VERSION ""

NS_ :

BS_:

BU_: TCM HCM IPMA_ADAS PSCM ABS_ESC TCCM TCM_DSL PCM_HEV PCM ECM_HEVDSL ECM_HEV ECM_Diesel ECM SIMA_DLCS BCMD_IPDB VDM CMR_DSMC SOBDMC_HPCM CHCM GWM _delete AWD_DLCM GENERIC TSTR

BO_ 936 ParkAid_Data: 8 IPMA_ADAS
 SG_ ApaSys_D_Stat : 61|3@0+ (1,0) [0|7] "SED"  PSCM,GWM,ECM,ECM_Diesel,ECM_HEV,ECM_HEVDSL,PCM,PCM_HEV
 SG_ ApaSteWhl_D_RqDrv : 63|2@0+ (1,0) [0|3] "SED"  GWM
 SG_ ApaSteScanMde_D_Stat : 49|2@0+ (1,0) [0|3] "SED"  GWM
 SG_ ApaSelSapp_D_Stat : 51|2@0+ (1,0) [0|3] "SED"  GWM
 SG_ ApaSelPpa_D_Stat : 53|2@0+ (1,0) [0|3] "SED"  GWM
 SG_ ApaSelPoa_D_Stat : 55|2@0+ (1,0) [0|3] "SED"  GWM
 SG_ ApaScan_D_Stat : 41|2@0+ (1,0) [0|3] "SED"  GWM
 SG_ ApaLongCtl_D_RqDrv : 44|3@0+ (1,0) [0|7] "SED"  GWM
 SG_ ApaGearShif_D_RqDrv : 47|3@0+ (1,0) [0|7] "SED"  GWM
 SG_ ApaActvSide2_D_Stat : 33|2@0+ (1,0) [0|3] "SED"  GWM
 SG_ ApaAcsy_D_RqDrv : 36|3@0+ (1,0) [0|7] "SED"  GWM
 SG_ ApaTrgtDist_D_Stat : 11|4@0+ (1,0) [0|15] "SED"  GWM
 SG_ ApaMsgTxt_D_Rq : 15|4@0+ (1,0) [0|15] "SED"  GWM
 SG_ ApaChime_D_Rq : 39|3@0+ (1,0) [0|7] "SED"  GWM
 SG_ SAPPStatusCoding : 7|8@0+ (1,0) [0|255] "unitless"  GWM
 SG_ EPASExtAngleStatReq : 23|1@0+ (1,0) [0|1] "SED"  PSCM,GWM,ABS_ESC
 SG_ ExtSteeringAngleReq2 : 22|15@0+ (0.1,-1000) [-1000|2276.5] "Degrees"  GWM,PSCM
 SG_ ApaButtnPrssd_B_Stat : 58|1@0+ (1,0) [0|1] "SED"  PSCM,GWM

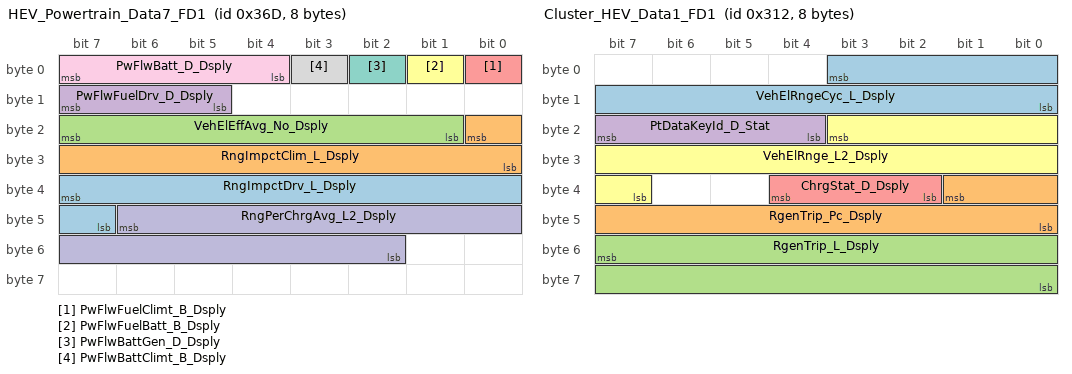
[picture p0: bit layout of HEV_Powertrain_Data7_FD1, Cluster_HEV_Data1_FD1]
BO_ 877 HEV_Powertrain_Data7_FD1: 8 SOBDMC_HPCM
 SG_ RngImpctDrv_L_Dsply : 39|9@0+ (1,-255) [-255|256] "km"  GWM
 SG_ RngImpctClim_L_Dsply : 16|9@0+ (1,-255) [-255|256] "km"  GWM
 SG_ VehElEffAvg_No_Dsply : 23|7@0+ (10,-100) [-100|1150] "wattHr/km"  GWM
 SG_ PwFlwFuelDrv_D_Dsply : 15|3@0+ (1,0) [0|7] "SED"  GWM
 SG_ PwFlwFuelClimt_B_Dsply : 0|1@0+ (1,0) [0|1] "SED"  GWM
 SG_ PwFlwFuelBatt_B_Dsply : 1|1@0+ (1,0) [0|1] "SED"  GWM
 SG_ PwFlwBattGen_D_Dsply : 2|1@0+ (1,0) [0|1] "SED"  GWM
 SG_ PwFlwBattClimt_B_Dsply : 3|1@0+ (1,0) [0|1] "SED"  GWM
 SG_ PwFlwBatt_D_Dsply : 7|4@0+ (1,0) [0|15] "SED"  GWM
 SG_ RngPerChrgAvg_L2_Dsply : 46|13@0+ (0.1,0) [0|818.9] "km"  ECM_HEV,GWM

BO_ 791 Cluster_HEV_Data8_FD1: 8 IPC
 SG_ AwdDrvMde_D2_Rq : 21|4@0+ (1,0) [0|15] "SED"  GENERIC
 SG_ StopStrtVThres_D_RqMnu : 17|2@0+ (1,0) [0|3] "SED"  ECM_HEV,ECM_HEVDSL,PCM_HEV
 SG_ EngAirFilt_B_RqReset : 48|1@0+ (1,0) [0|1] "SED"  ECM_Diesel,ECM,ECM_HEV,ECM_HEVDSL,PCM,GENERIC
 SG_ BattElEmotive_Pc_Dsply : 1|10@0+ (0.1,0) [0|102.1] "percent"  GENERIC
 SG_ HybMdeOvrrd_D_Rq : 7|2@0+ (1,0) [0|3] "SED"  PCM,SOBDMC_HPCM,PCM_HEV
 SG_ GpsElMdeSel_B_Rq : 50|1@0+ (1,0) [0|1] "SED"  SOBDMC_HPCM
 SG_ LongTermReset_B_Rq : 49|1@0+ (1,0) [0|1] "SED"  PCM_HEV,SOBDMC_HPCM
 SG_ EcoCcActv_B_Rq : 51|1@0+ (1,0) [0|1] "SED"  ECM_HEV
 SG_ DrvEffLvl_No_Stat : 61|6@0+ (1,0) [0|61] "unitless"  SOBDMC_HPCM
 SG_ ChargeProfIDPref_Rq : 5|2@0+ (1,0) [0|3] "SED"  GENERIC
 SG_ ConsAvgTrip_Fe_Dsply : 31|24@0+ (0.0001,0) [0|1677.7215] "litre/100km"  GENERIC
 SG_ GrdAsstAllw_D_RqMnu : 23|2@0+ (1,0) [0|3] "SED"  SOBDMC_HPCM,ECM_HEV
 SG_ PlgOvrrdStrt_D_Cmd : 55|2@0+ (1,0) [0|3] "SED"  SOBDMC_HPCM,PCM,PCM_HEV
 SG_ EcoMde_D_RqMnu : 3|2@0+ (1,0) [0|3] "SED"  SOBDMC_HPCM
 SG_ EmotiveType_D_Dsply : 53|2@0+ (1,0) [0|3] "SED"  GENERIC
 SG_ VehElEffTrip2Reset_B_Rq : 62|1@0+ (1,0) [0|1] "SED"  SOBDMC_HPCM
 SG_ VehElEffTrip1Reset_B_Rq : 63|1@0+ (1,0) [0|1] "SED"  SOBDMC_HPCM

BO_ 786 Cluster_HEV_Data1_FD1: 8 SOBDMC_HPCM
 SG_ VehElRngeCyc_L_Dsply : 3|12@0+ (0.1,0) [0|409.3] "km"  GWM
 SG_ RgenTrip_Pc_Dsply : 33|10@0+ (0.1,0) [0|102.3] "percent"  GWM
 SG_ RgenTrip_L_Dsply : 55|16@0+ (0.1,0) [0|6553.3] "kilometer"  GWM
 SG_ PtDataKeyId_D_Stat : 23|4@0+ (1,0) [0|15] "SED"  GWM
 SG_ ChrgStat_D_Dsply : 36|3@0+ (1,0) [0|7] "SED"  GWM
 SG_ VehElRnge_L2_Dsply : 19|13@0+ (0.1,0) [0|818.9] "kilometer"  ECM_HEV,GWM

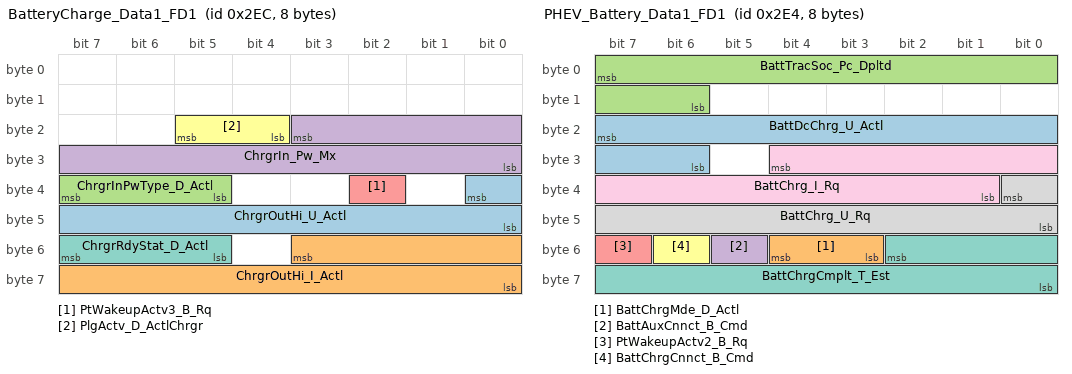
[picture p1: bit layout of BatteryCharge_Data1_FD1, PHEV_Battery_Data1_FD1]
BO_ 748 BatteryCharge_Data1_FD1: 8 SOBDM_BCCM
 SG_ ChrgrOutHi_U_Actl : 32|9@0+ (1,0) [0|510] "volt"  SOBDMC_HPCM,GENERIC
 SG_ ChrgrOutHi_I_Actl : 51|12@0+ (0.1,0) [0|409.4] "ampere"  SOBDMC_HPCM,GENERIC
 SG_ ChrgrInPwType_D_Actl : 39|3@0+ (1,0) [0|7] "SED"  SOBDMC_HPCM,PCM_HEV
 SG_ ChrgrIn_Pw_Mx : 19|12@0+ (50,0) [0|204700] "watts"  ECM_HEV,SOBDMC_HPCM,PCM_HEV
 SG_ PtWakeupActv3_B_Rq : 34|1@0+ (1,0) [0|1] "SED"  SOBDMC_HPCM,GENERIC
 SG_ PlgActv_D_ActlChrgr : 21|2@0+ (1,0) [0|3] "SED"  SOBDMC_HPCM,ECM_HEV,PCM_HEV
 SG_ ChrgrRdyStat_D_Actl : 55|3@0+ (1,0) [0|7] "SED"  SOBDMC_HPCM,ECM_HEV,PCM_HEV

BO_ 740 PHEV_Battery_Data1_FD1: 8 BECM
 SG_ BattDcChrg_U_Actl : 23|10@0+ (0.5,0) [0|510.5] "volt"  GENERIC
 SG_ BattChrgMde_D_Actl : 52|2@0+ (1,0) [0|3] "SED"  GENERIC
 SG_ BattTracSoc_Pc_Dpltd : 7|10@0+ (0.1,0) [0|102.3] "percent"  SOBDMC_HPCM,PCM_HEV
 SG_ BattAuxCnnct_B_Cmd : 53|1@0+ (1,0) [0|1] "SED"  SOBDMC_HPCM,GENERIC
 SG_ PtWakeupActv2_B_Rq : 55|1@0+ (1,0) [0|1] "SED"  SOBDMC_HPCM,GENERIC
 SG_ BattChrgCnnct_B_Cmd : 54|1@0+ (1,0) [0|1] "SED"  GENERIC
 SG_ BattChrgCmplt_T_Est : 50|11@0+ (1,0) [0|2047] "minute"  GENERIC
 SG_ BattChrg_U_Rq : 32|9@0+ (1,0) [0|511] "volt"  SOBDMC_HPCM,GENERIC
 SG_ BattChrg_I_Rq : 28|12@0+ (0.1,0) [0|409.5] "ampere"  SOBDMC_HPCM,GENERIC

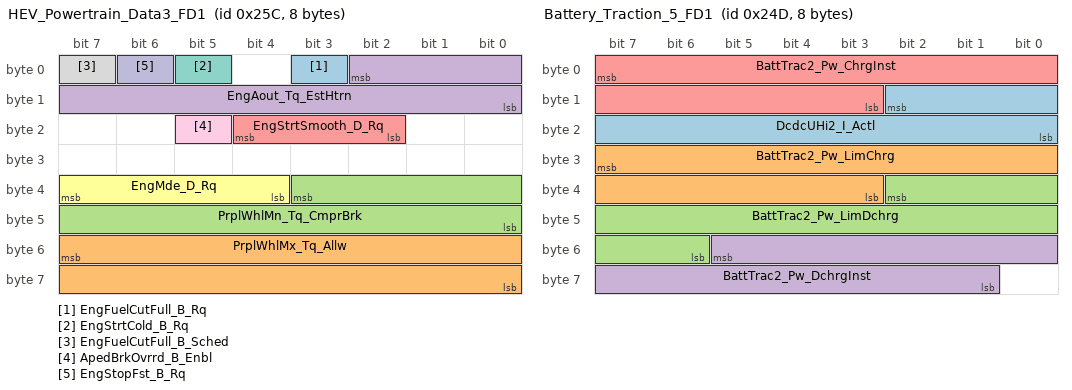
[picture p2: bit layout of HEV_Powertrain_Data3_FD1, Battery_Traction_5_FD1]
BO_ 604 HEV_Powertrain_Data3_FD1: 8 SOBDMC_HPCM
 SG_ EngFuelCutFull_B_Rq : 3|1@0+ (1,0) [0|1] "SED"  GWM,ECM_HEV
 SG_ PrplWhlMx_Tq_Allw : 55|16@0+ (4,-131072) [-131072|131064] "Nm"  GWM,ECM_HEV
 SG_ PrplWhlMn_Tq_CmprBrk : 35|12@0+ (4,-8192) [-8192|8184] "Nm"  GWM,ECM_HEV
 SG_ EngAout_Tq_EstHtrn : 2|11@0+ (1,-500) [-500|1546] "Nm"  GWM,ECM_HEV
 SG_ EngStrtSmooth_D_Rq : 20|3@0+ (1,0) [0|7] "SED"  GWM,ECM_HEV
 SG_ EngMde_D_Rq : 39|4@0+ (1,0) [0|15] "SED"  GWM,ECM_HEV
 SG_ EngStrtCold_B_Rq : 5|1@0+ (1,0) [0|1] "SED"  GWM,ECM_HEV
 SG_ EngFuelCutFull_B_Sched : 7|1@0+ (1,0) [0|1] "SED"  GWM,ECM_HEV
 SG_ ApedBrkOvrrd_B_Enbl : 21|1@0+ (1,0) [0|1] "SED"  GWM,ECM_HEV
 SG_ EngStopFst_B_Rq : 6|1@0+ (1,0) [0|1] "SED"  GWM,ECM_HEV

BO_ 589 Battery_Traction_5_FD1: 8 BECM
 SG_ DcdcUHi2_I_Actl : 10|11@0+ (0.1,0) [0|204.6] "ampere"  SOBDMC_HPCM,ECM_HEVDSL,PCM_HEV
 SG_ BattTrac2_Pw_LimChrg : 31|13@0+ (50,0) [0|409550] "watts"  SOBDMC_HPCM,ECM_HEVDSL,PCM_HEV
 SG_ BattTrac2_Pw_LimDchrg : 34|13@0+ (50,0) [0|409550] "watts"  SOBDMC_HPCM,ECM_HEVDSL,PCM_HEV
 SG_ BattTrac2_Pw_DchrgInst : 53|13@0+ (50,0) [0|409550] "watts"  SOBDMC_HPCM,ECM_HEVDSL,PCM_HEV
 SG_ BattTrac2_Pw_ChrgInst : 7|13@0+ (50,0) [0|409550] "watts"  SOBDMC_HPCM,ECM_HEVDSL,PCM_HEV

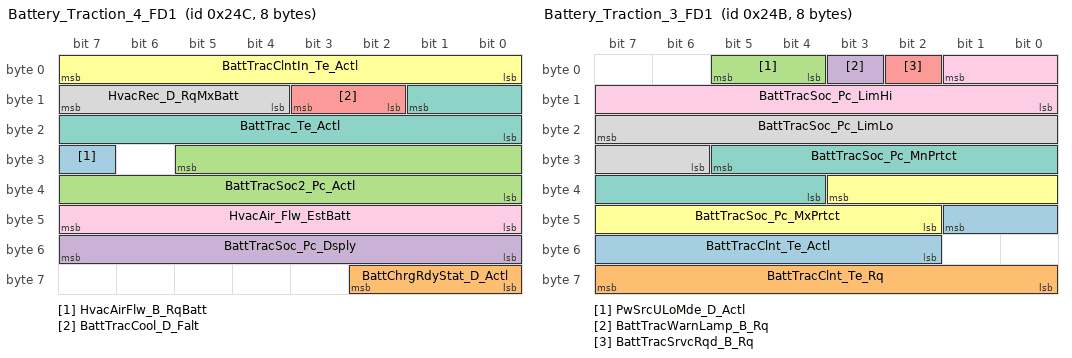
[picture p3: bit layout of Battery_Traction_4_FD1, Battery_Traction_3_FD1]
BO_ 588 Battery_Traction_4_FD1: 8 BECM
 SG_ HvacAirFlw_B_RqBatt : 31|1@0+ (1,0) [0|1] "SED"  SOBDMC_HPCM,ECM_HEVDSL
 SG_ BattChrgRdyStat_D_Actl : 58|3@0+ (1,0) [0|7] "SED"  SOBDMC_HPCM,ECM_HEV,ECM_HEVDSL,PCM_HEV
 SG_ BattTracSoc2_Pc_Actl : 29|14@0+ (0.01,0) [0|163.81] "%"  SOBDMC_HPCM,ECM_HEV,ECM_HEVDSL,PCM_HEV
 SG_ BattTracSoc_Pc_Dsply : 55|8@0+ (0.5,0) [0|126.5] "Percent"  SOBDMC_HPCM,PCM_HEV
 SG_ BattTracCool_D_Falt : 11|2@0+ (1,0) [0|3] "SED"  GENERIC
 SG_ BattTracClntIn_Te_Actl : 7|8@0+ (1,-50) [-50|204] "degC"  GENERIC
 SG_ BattTrac_Te_Actl : 9|10@0+ (0.5,-50) [-50|460.5] "degC"  SOBDMC_HPCM,ECM_HEV,ECM_HEVDSL,PCM_HEV
 SG_ HvacRec_D_RqMxBatt : 15|4@0+ (1,0) [0|15] "SED"  GENERIC
 SG_ HvacAir_Flw_EstBatt : 47|8@0+ (0.5,0) [0|127] "liter/second"  ECM_HEVDSL

BO_ 587 Battery_Traction_3_FD1: 8 BECM
 SG_ BattTracClnt_Te_Actl : 41|8@0+ (0.5,-60) [-60|66.5] "degC"  ECM_Diesel,ECM_HEVDSL,SOBDMC_HPCM
 SG_ BattTracClnt_Te_Rq : 63|8@0+ (0.5,-60) [-60|67.5] "degC"  SOBDMC_HPCM,GENERIC
 SG_ PwSrcULoMde_D_Actl : 5|2@0+ (1,0) [0|3] "SED"  ECM_HEV,ECM_HEVDSL,PCM_HEV
 SG_ BattTracWarnLamp_B_Rq : 3|1@0+ (1,0) [0|1] "SED"  GENERIC
 SG_ BattTracSrvcRqd_B_Rq : 2|1@0+ (1,0) [0|1] "SED"  GENERIC
 SG_ BattTracSoc_Pc_MxPrtct : 35|10@0+ (0.1,0) [0|100] "%"  SOBDMC_HPCM,ECM_HEVDSL,PCM_HEV,ECM_HEV
 SG_ BattTracSoc_Pc_MnPrtct : 29|10@0+ (0.1,0) [0|100] "%"  SOBDMC_HPCM,ECM_HEV,ECM_HEVDSL,PCM_HEV
 SG_ BattTracSoc_Pc_LimLo : 23|10@0+ (0.1,0) [0|100] "%"  SOBDMC_HPCM,ECM_HEV,ECM_HEVDSL,PCM_HEV
 SG_ BattTracSoc_Pc_LimHi : 1|10@0+ (0.1,0) [0|100] "%"  SOBDMC_HPCM,ECM_HEV,ECM_HEVDSL,PCM_HEV

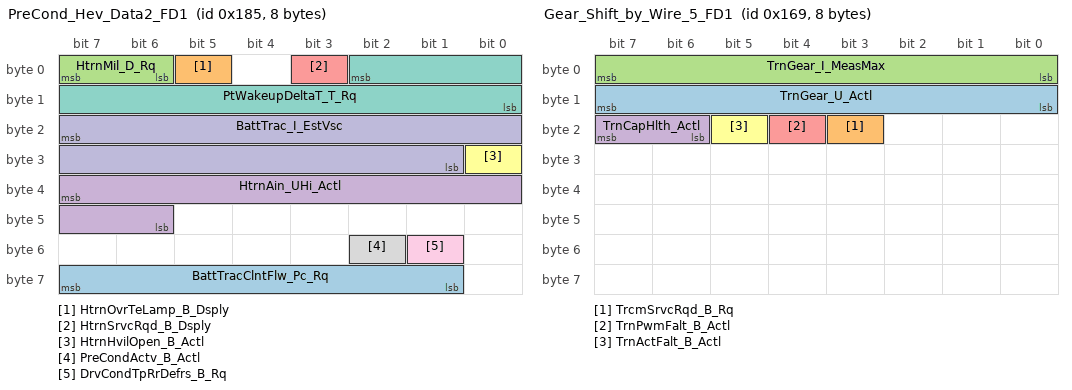
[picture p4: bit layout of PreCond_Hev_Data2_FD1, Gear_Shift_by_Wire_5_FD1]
BO_ 389 PreCond_Hev_Data2_FD1: 8 SOBDMC_HPCM
 SG_ BattTracClntFlw_Pc_Rq : 63|7@0+ (1,0) [0|127] "percent"  GWM,GENERIC
 SG_ HtrnOvrTeLamp_B_Dsply : 5|1@0+ (1,0) [0|1] "SED"  GWM,GENERIC
 SG_ HtrnMil_D_Rq : 7|2@0+ (1,0) [0|3] "SED"  GWM,ECM_HEV
 SG_ HtrnAin_UHi_Actl : 39|10@0+ (0.5,0) [0|510.5] "volt"  GWM,PCM_HEV,ECM_HEV
 SG_ HtrnSrvcRqd_B_Dsply : 3|1@0+ (1,0) [0|1] "SED"  GWM
 SG_ HtrnHvilOpen_B_Actl : 24|1@0+ (1,0) [0|1] "SED"  GWM,PCM_HEV
 SG_ PtWakeupDeltaT_T_Rq : 2|11@0+ (1,0) [0|2045] "minute"  GWM,GENERIC
 SG_ PreCondActv_B_Actl : 50|1@0+ (1,0) [0|1] "SED"  GWM,ECM_HEV,PCM_HEV
 SG_ DrvCondTpRrDefrs_B_Rq : 49|1@0+ (1,0) [0|1] "SED"  GWM,GENERIC
 SG_ BattTrac_I_EstVsc : 23|15@0+ (0.05,-750) [-750|888.25] "Amps"  GWM

BO_ 361 Gear_Shift_by_Wire_5_FD1: 8 TRCM
 SG_ TrnGear_U_Actl : 15|8@0+ (0.1,0) [0|25.5] "volt"  PCM,PCM_HEV
 SG_ TrcmSrvcRqd_B_Rq : 19|1@0+ (1,0) [0|1] "SED"  GENERIC
 SG_ TrnGear_I_MeasMax : 7|8@0+ (0.1,0) [0|25.4] "Amps"  ECM_HEV,PCM,PCM_HEV
 SG_ TrnCapHlth_Actl : 23|2@0+ (1,0) [0|3] "SED"  ECM_HEV,PCM,PCM_HEV
 SG_ TrnPwmFalt_B_Actl : 20|1@0+ (1,0) [0|1] "SED"  ECM_HEV,PCM,PCM_HEV
 SG_ TrnActFalt_B_Actl : 21|1@0+ (1,0) [0|1] "SED"  PCM_HEV,PCM,ECM_HEV

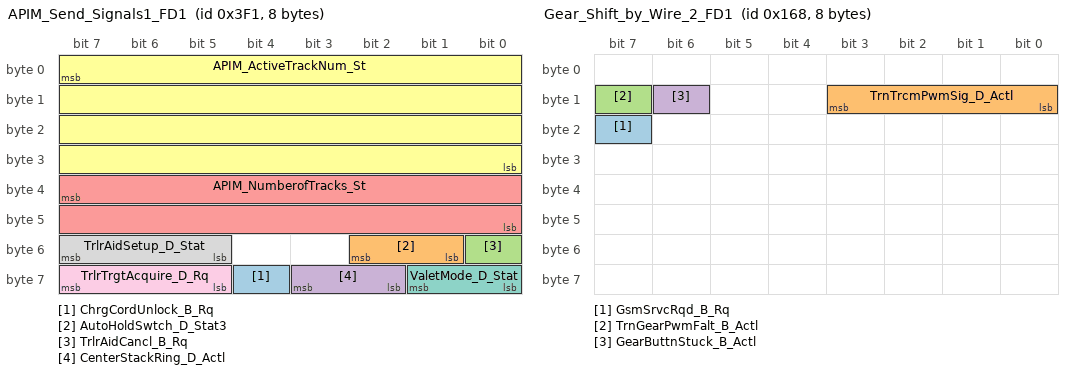
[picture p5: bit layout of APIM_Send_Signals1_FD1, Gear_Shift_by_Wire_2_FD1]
BO_ 1009 APIM_Send_Signals1_FD1: 8 APIM
 SG_ ChrgCordUnlock_B_Rq : 60|1@0+ (1,0) [0|1] "SED"  GENERIC
 SG_ AutoHoldSwtch_D_Stat3 : 50|2@0+ (1,0) [0|3] "SED"  ABS_ESC
 SG_ TrlrAidCancl_B_Rq : 48|1@0+ (1,0) [0|1] "SED"  IPMA_ADAS,PSCM
 SG_ CenterStackRing_D_Actl : 59|2@0+ (1,0) [0|3] "SED"  GENERIC
 SG_ APIM_NumberofTracks_St : 39|16@0+ (1,0) [0|65535] "unitless"  GENERIC
 SG_ APIM_ActiveTrackNum_St : 7|32@0+ (1,0) [0|4294967295] "unitless"  GENERIC
 SG_ ValetMode_D_Stat : 57|2@0+ (1,0) [0|3] "SED"  GENERIC
 SG_ TrlrAidSetup_D_Stat : 55|3@0+ (1,0) [0|7] "SED"  GENERIC
 SG_ TrlrTrgtAcquire_D_Rq : 63|3@0+ (1,0) [0|7] "SED"  GENERIC

BO_ 360 Gear_Shift_by_Wire_2_FD1: 8 GSM
 SG_ GsmSrvcRqd_B_Rq : 23|1@0+ (1,0) [0|1] "SED"  TCM,SOBDMC_HPCM,TCM_DSL
 SG_ TrnTrcmPwmSig_D_Actl : 11|4@0+ (1,0) [0|15] "SED"  TCM,SOBDMC_HPCM,ECM_HEV,PCM,PCM_HEV,TCM_DSL
 SG_ TrnGearPwmFalt_B_Actl : 15|1@0+ (1,0) [0|1] "SED"  TCM,SOBDMC_HPCM,ECM_HEV,PCM,PCM_HEV,TCM_DSL
 SG_ GearButtnStuck_B_Actl : 14|1@0+ (1,0) [0|1] "SED"  TCM,SOBDMC_HPCM,ECM_HEV,PCM,PCM_HEV,TCM_DSL

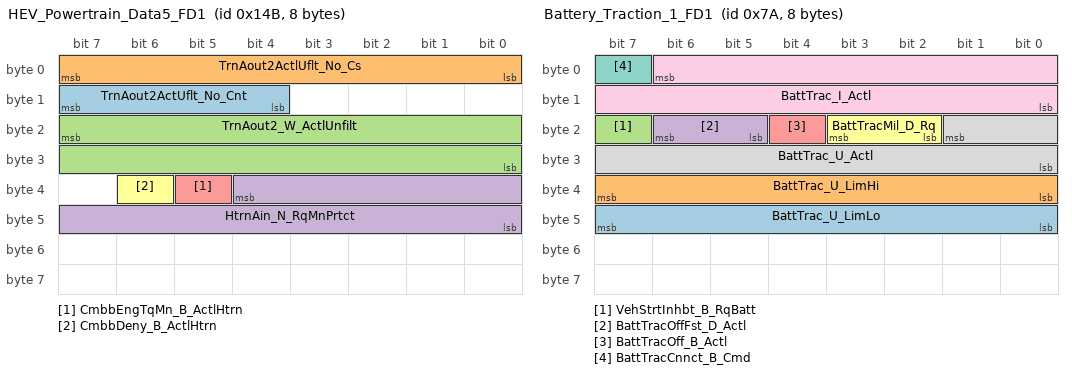
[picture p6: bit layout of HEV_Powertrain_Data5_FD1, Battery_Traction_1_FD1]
BO_ 331 HEV_Powertrain_Data5_FD1: 8 SOBDMC_HPCM
 SG_ TrnAout2ActUflt_No_Cnt : 15|4@0+ (1,0) [0|15] "Unitless"  GWM,ECM_HEV
 SG_ TrnAout2ActlUflt_No_Cs : 7|8@0+ (1,0) [0|255] "Unitless"  GWM,ECM_HEV
 SG_ TrnAout2_W_ActlUnfilt : 23|16@0+ (0.1,-3276.5) [-3276.5|3276.8] "rad/s"  GWM,ABS_ESC,ECM_HEV
 SG_ HtrnAin_N_RqMnPrtct : 36|13@0+ (2,0) [0|16382] "RPM"  GWM,ECM_HEV
 SG_ CmbbEngTqMn_B_ActlHtrn : 37|1@0+ (1,0) [0|1] "SED"  GWM,ECM_HEV
 SG_ CmbbDeny_B_ActlHtrn : 38|1@0+ (1,0) [0|1] "SED"  GWM,ECM_HEV

BO_ 140 CruiseCtrl_StrgData2_FD1: 8 IPC
 SG_ DcacPwResetBttn_D_Stat : 36|2@0+ (1,0) [0|3] "SED"  ECM,ECM_Diesel,ECM_HEV,ECM_HEVDSL,PCM,PCM_HEV
 SG_ CcAslButtnIndxIncPress2 : 18|1@0+ (1,0) [0|1] "SED"  ECM,ECM_HEVDSL,PCM
 SG_ SteWhlSwtchMde_D_Stat : 23|2@0+ (1,0) [0|3] "SED"  GENERIC
 SG_ CcAslButtnIndxDecPress2 : 19|1@0+ (1,0) [0|1] "SED"  ECM,ECM_HEVDSL,PCM
 SG_ CcAslButtnResIncPress3 : 29|1@0+ (1,0) [0|1] "SED"  PCM,ECM_HEVDSL,ECM
 SG_ CcButtnOnPress3 : 37|1@0+ (1,0) [0|1] "SED"  PCM,ECM_HEVDSL,ECM
 SG_ CcButtnOnOffPress3 : 38|1@0+ (1,0) [0|1] "SED"  PCM,ECM_HEVDSL,ECM
 SG_ CcButtnOnOffCnclPress3 : 39|1@0+ (1,0) [0|1] "SED"  PCM,ECM_HEVDSL,ECM
 SG_ CcButtnOffPress3 : 24|1@0+ (1,0) [0|1] "SED"  PCM,ECM_HEVDSL,ECM
 SG_ CcAsllButtnResPress3 : 25|1@0+ (1,0) [0|1] "SED"  PCM,ECM_HEVDSL,ECM
 SG_ CcAslButtnSetPress3 : 26|1@0+ (1,0) [0|1] "SED"  PCM,ECM_HEVDSL,ECM
 SG_ CcAslButtnSetIncPress3 : 27|1@0+ (1,0) [0|1] "SED"  PCM,ECM_HEVDSL,ECM
 SG_ CcAslButtnSetDecPress3 : 28|1@0+ (1,0) [0|1] "SED"  PCM,ECM_HEVDSL,ECM
 SG_ CcAslButtnResDecPress3 : 30|1@0+ (1,0) [0|1] "SED"  PCM,ECM_HEVDSL,ECM
 SG_ CcAslButtnOnPress3 : 31|1@0+ (1,0) [0|1] "SED"  PCM,ECM_HEVDSL,ECM
 SG_ CcAslButtnOnOffCncl3 : 16|1@0+ (1,0) [0|1] "SED"  PCM,ECM_HEVDSL,ECM
 SG_ CcAslButtnDeny_B_Actl3 : 20|1@0+ (1,0) [0|1] "SED"  PCM,ECM_HEVDSL,ECM
 SG_ CcAslButtnCnclPress3 : 8|1@0+ (1,0) [0|1] "SED"  PCM,ECM_HEVDSL,ECM
 SG_ AslButtnOnOffPress3 : 9|1@0+ (1,0) [0|1] "SED"  PCM,ECM_HEVDSL,ECM
 SG_ AslButtnOnOffCnclPress2 : 10|1@0+ (1,0) [0|1] "SED"  PCM,ECM_HEVDSL,ECM
 SG_ CcAslButtnOffCnclPress2 : 17|1@0+ (1,0) [0|1] "SED"  ECM_HEVDSL,PCM,ECM
 SG_ CcAslButtnCnclResPress2 : 21|1@0+ (1,0) [0|1] "SED"  ECM,ECM_HEVDSL,PCM

BO_ 122 Battery_Traction_1_FD1: 8 BECM
 SG_ BattTrac_U_LimLo : 47|8@0+ (2,0) [0|510] "volt"  SOBDMC_HPCM,PCM_HEV
 SG_ BattTrac_U_LimHi : 39|8@0+ (2,0) [0|510] "volt"  SOBDMC_HPCM,PCM_HEV
 SG_ VehStrtInhbt_B_RqBatt : 23|1@0+ (1,0) [0|1] "SED"  SOBDMC_HPCM,PCM_HEV,ECM_HEVDSL
 SG_ BattTracOffFst_D_Actl : 22|2@0+ (1,0) [0|3] "SED"  SOBDMC_HPCM,ECM_HEV,ECM_HEVDSL,PCM_HEV
 SG_ BattTracOff_B_Actl : 20|1@0+ (1,0) [0|1] "SED"  ECM_HEVDSL,SOBDMC_HPCM,PCM_HEV
 SG_ BattTracMil_D_Rq : 19|2@0+ (1,0) [0|3] "SED"  PCM_HEV,ECM_HEV
 SG_ BattTracCnnct_B_Cmd : 7|1@0+ (1,0) [0|1] "SED"  SOBDMC_HPCM,ECM_HEV,ECM_HEVDSL,PCM_HEV
 SG_ BattTrac_U_Actl : 17|10@0+ (0.5,0) [0|510.5] "Volts"  SOBDMC_HPCM,ECM_HEV,ECM_HEVDSL,PCM_HEV
 SG_ BattTrac_I_Actl : 6|15@0+ (0.05,-750) [-750|888.25] "Amps"  SOBDMC_HPCM,ECM_HEV,ECM_HEVDSL,PCM_HEV

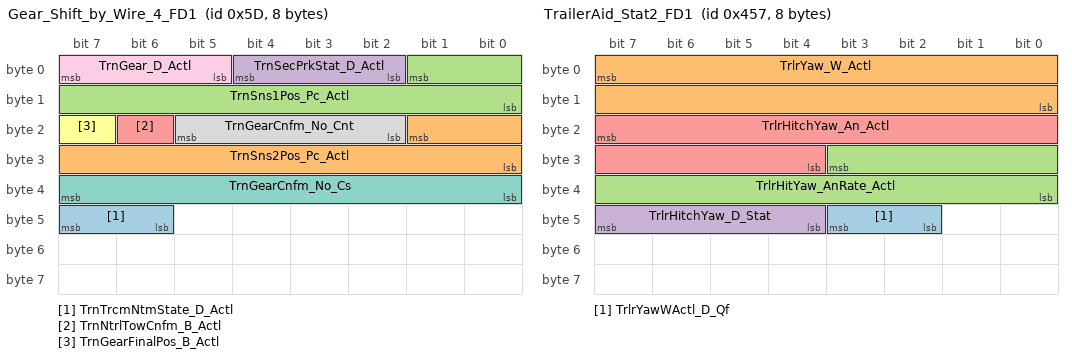
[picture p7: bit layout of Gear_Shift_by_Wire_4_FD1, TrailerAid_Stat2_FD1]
BO_ 93 Gear_Shift_by_Wire_4_FD1: 8 TRCM
 SG_ TrnTrcmNtmState_D_Actl : 47|2@0+ (1,0) [0|3] "SED"  TCM,ECM_HEV,PCM,PCM_HEV,TCM_DSL
 SG_ TrnSns2Pos_Pc_Actl : 17|10@0+ (0.1,0) [0|102.2] "percent duty cycle"  ECM_HEV,PCM,PCM_HEV
 SG_ TrnSns1Pos_Pc_Actl : 1|10@0+ (0.1,0) [0|102.2] "percent duty cycle"  ECM_HEV,PCM,PCM_HEV
 SG_ TrnSecPrkStat_D_Actl : 4|3@0+ (1,0) [0|7] "SED"  ECM_HEV,PCM,PCM_HEV
 SG_ TrnNtrlTowCnfm_B_Actl : 22|1@0+ (1,0) [0|1] "SED"  ECM_HEV,PCM,PCM_HEV
 SG_ TrnGearFinalPos_B_Actl : 23|1@0+ (1,0) [0|1] "SED"  ECM_HEV,PCM,PCM_HEV
 SG_ TrnGearCnfm_No_Cs : 39|8@0+ (1,0) [0|255] "Unitless"  ECM_HEV,PCM,PCM_HEV
 SG_ TrnGearCnfm_No_Cnt : 21|4@0+ (1,0) [0|15] "Unitless"  ECM_HEV,PCM,PCM_HEV
 SG_ TrnGear_D_Actl : 7|3@0+ (1,0) [0|7] "SED"  ECM_HEV,PCM,PCM_HEV

BO_ 90 Gear_Shift_by_Wire_FD1: 8 GSM
 SG_ TrnGsmNtmState_D_Actl : 55|2@0+ (1,0) [0|3] "SED"  TCM,SOBDMC_HPCM,ABS_ESC,ECM_HEV,PCM,PCM_HEV,TCM_DSL
 SG_ DrQltyDrv_D_StatGsm : 42|3@0+ (1,0) [0|7] "SED"  TCM,SOBDMC_HPCM,ABS_ESC,ECM,ECM_HEV,ECM_HEVDSL,PCM,PCM_HEV,TCM_DSL,IPMA_ADAS
 SG_ TrnBtsiOvrrd_B_Stat : 43|1@0+ (1,0) [0|1] "SED"  ABS_ESC,TCM,SOBDMC_HPCM,ECM,ECM_HEV,ECM_HEVDSL,PCM,PCM_HEV,TCM_DSL
 SG_ GsmGearMsgTxt_D_Rq : 63|2@0+ (1,0) [0|3] "SED"  SOBDMC_HPCM,GENERIC
 SG_ TrnRng_D_RqGsm : 51|4@0+ (1,0) [0|15] "SED"  TCM,SOBDMC_HPCM,ECM,ECM_HEV,ECM_HEVDSL,PCM,TCM_DSL,PCM_HEV
 SG_ PrkBrkActv_D_RqGsmGear : 53|2@0+ (1,0) [0|3] "SED"  SOBDMC_HPCM,ABS_ESC
 SG_ TrnValidGearRq_D_Stat : 25|2@0+ (1,0) [0|3] "SED"  ABS_ESC,TCM,SOBDMC_HPCM,ECM_HEV,PCM,PCM_HEV,TCM_DSL
 SG_ TrnGearRqCnt_B_Actl : 26|1@0+ (1,0) [0|1] "unitless"  ABS_ESC,TCM,SOBDMC_HPCM,ECM_HEV,PCM,PCM_HEV,TCM_DSL
 SG_ TrnGearButtn_U_Actl : 23|8@0+ (0.05,0) [0|12.7] "VOLT"  TCM,SOBDMC_HPCM,ECM_HEV,PCM,PCM_HEV,TCM_DSL
 SG_ TrnGearButtn_B_ActlR2 : 8|1@0+ (1,0) [0|1] "SED"  TCM,SOBDMC_HPCM,ECM_HEV,PCM,PCM_HEV,TCM_DSL
 SG_ TrnGearButtn_B_ActlR1 : 9|1@0+ (1,0) [0|1] "SED"  TCM,SOBDMC_HPCM,ECM_HEV,PCM,PCM_HEV,TCM_DSL
 SG_ TrnGearButtn_B_ActlR0 : 10|1@0+ (1,0) [0|1] "SED"  TCM,SOBDMC_HPCM,ECM_HEV,PCM,PCM_HEV,TCM_DSL
 SG_ TrnGearButtn_B_ActlP2 : 11|1@0+ (1,0) [0|1] "SED"  TCM,SOBDMC_HPCM,TCM_DSL,ECM_HEV,PCM,PCM_HEV
 SG_ TrnGearButtn_B_ActlP1 : 12|1@0+ (1,0) [0|1] "SED"  TCM,SOBDMC_HPCM,ECM_HEV,PCM,PCM_HEV,TCM_DSL
 SG_ TrnGearButtn_B_ActlP0 : 13|1@0+ (1,0) [0|1] "SED"  TCM,SOBDMC_HPCM,ECM_HEV,PCM,PCM_HEV,TCM_DSL
 SG_ TrnGearButtn_B_ActlN2 : 14|1@0+ (1,0) [0|1] "SED"  TCM,SOBDMC_HPCM,ECM_HEV,PCM,PCM_HEV,TCM_DSL
 SG_ TrnGearButtn_B_ActlN1 : 15|1@0+ (1,0) [0|1] "SED"  TCM,SOBDMC_HPCM,ECM_HEV,PCM,PCM_HEV,TCM_DSL
 SG_ TrnGearButtn_B_ActlN0 : 0|1@0+ (1,0) [0|1] "SED"  TCM,SOBDMC_HPCM,ECM_HEV,PCM,PCM_HEV,TCM_DSL
 SG_ TrnGearButtn_B_ActlM2 : 1|1@0+ (1,0) [0|1] "SED"  TCM,SOBDMC_HPCM,ECM_HEV,PCM,PCM_HEV,TCM_DSL
 SG_ TrnGearButtn_B_ActlM1 : 2|1@0+ (1,0) [0|1] "SED"  TCM,SOBDMC_HPCM,ECM_HEV,PCM,PCM_HEV,TCM_DSL
 SG_ TrnGearButtn_B_ActlM0 : 3|1@0+ (1,0) [0|1] "SED"  TCM,SOBDMC_HPCM,ECM_HEV,PCM,PCM_HEV,TCM_DSL
 SG_ TrnGearButtn_B_ActlD2 : 4|1@0+ (1,0) [0|1] "SED"  TCM,SOBDMC_HPCM,ECM_HEV,PCM,PCM_HEV,TCM_DSL
 SG_ TrnGearButtn_B_ActlD1 : 5|1@0+ (1,0) [0|1] "SED"  TCM,SOBDMC_HPCM,ECM_HEV,PCM,PCM_HEV,TCM_DSL
 SG_ TrnGearButtn_B_ActlD0 : 6|1@0+ (1,0) [0|1] "SED"  TCM,SOBDMC_HPCM,ECM_HEV,PCM,PCM_HEV,TCM_DSL
 SG_ TrnGear_No_Cs : 39|8@0+ (1,0) [0|255] "Unitless"  ABS_ESC,TCM,SOBDMC_HPCM,ECM_HEV,PCM,PCM_HEV,TCM_DSL
 SG_ TrnGear_No_Cnt : 47|4@0+ (1,0) [0|15] "Unitless"  ABS_ESC,TCM,SOBDMC_HPCM,ECM_HEV,PCM,PCM_HEV,TCM_DSL
 SG_ TrnGear_D_RqDrv : 31|5@0+ (1,0) [0|31] "SED"  ABS_ESC,TCM,SOBDMC_HPCM,ECM_HEV,PCM,PCM_HEV,TCM_DSL
 SG_ BrkSwtchPos_B_ActlGsm : 7|1@0+ (1,0) [0|1] "SED"  ABS_ESC,TCM,SOBDMC_HPCM,ECM_HEV,PCM,PCM_HEV,TCM_DSL

BO_ 1114 TrailerAid_Data_FD1: 8 IPC
 SG_ TrailCtlSwtch_B_Stat2 : 16|1@0+ (1,0) [0|1] "SED"  ABS_ESC
 SG_ TrlBrkInitOut_D_Rq : 60|2@0+ (1,0) [0|3] "SED"  GENERIC

BO_ 1111 TrailerAid_Stat2_FD1: 8 RCM
 SG_ TrlrYawWActl_D_Qf : 43|2@0+ (1,0) [0|3] "SED"  IPMA_ADAS,PSCM
 SG_ TrlrYaw_W_Actl : 7|16@0+ (0.0002,-6.5) [-6.5|6.6066] "radians/second"  IPMA_ADAS,PSCM
 SG_ TrlrHitYaw_AnRate_Actl : 27|12@0+ (0.1,-50) [-50|359.3] "degrees/second"  IPMA_ADAS,PSCM
 SG_ TrlrHitchYaw_D_Stat : 47|4@0+ (1,0) [0|15] "SED"  IPMA_ADAS,PSCM
 SG_ TrlrHitchYaw_An_Actl : 23|12@0+ (0.1,-90) [-90|319.3] "degrees"  IPMA_ADAS,PSCM

BO_ 1106 TrailerAid_Stat1_FD1: 8 RCM
 SG_ TrlrSnsId_No_Actl : 7|48@0+ (1,0) [0|281474976710653] "unitless"  PSCM,IPMA_ADAS

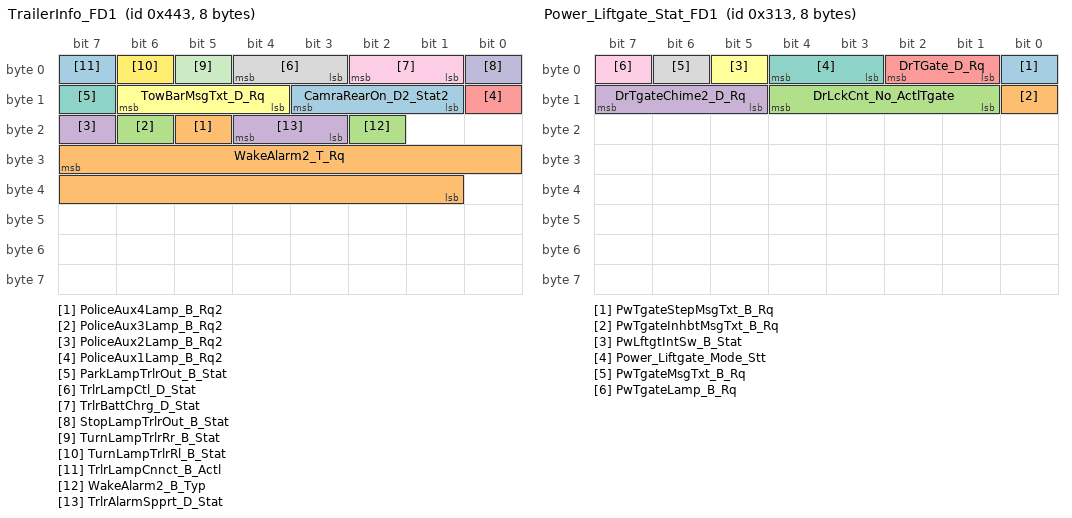
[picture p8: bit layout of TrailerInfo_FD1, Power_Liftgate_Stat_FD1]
BO_ 1091 TrailerInfo_FD1: 8 TRM
 SG_ CamraRearOn_D2_Stat2 : 11|3@0+ (1,0) [0|7] "SED"  IPMA_ADAS
 SG_ PoliceAux4Lamp_B_Rq2 : 21|1@0+ (1,0) [0|1] "SED"  GENERIC
 SG_ PoliceAux3Lamp_B_Rq2 : 22|1@0+ (1,0) [0|1] "SED"  GENERIC
 SG_ PoliceAux2Lamp_B_Rq2 : 23|1@0+ (1,0) [0|1] "SED"  GENERIC
 SG_ PoliceAux1Lamp_B_Rq2 : 8|1@0+ (1,0) [0|1] "SED"  GENERIC
 SG_ TowBarMsgTxt_D_Rq : 14|3@0+ (1,0) [0|7] "SED"  GENERIC
 SG_ ParkLampTrlrOut_B_Stat : 15|1@0+ (1,0) [0|1] "SED"  GENERIC
 SG_ TrlrLampCtl_D_Stat : 4|2@0+ (1,0) [0|3] "SED"  GENERIC
 SG_ TrlrBattChrg_D_Stat : 2|2@0+ (1,0) [0|3] "SED"  GENERIC
 SG_ StopLampTrlrOut_B_Stat : 0|1@0+ (1,0) [0|1] "SED"  GENERIC
 SG_ TurnLampTrlrRr_B_Stat : 5|1@0+ (1,0) [0|1] "SED"  GENERIC
 SG_ TurnLampTrlrRl_B_Stat : 6|1@0+ (1,0) [0|1] "SED"  GENERIC
 SG_ TrlrLampCnnct_B_Actl : 7|1@0+ (1,0) [0|1] "SED"  TCM,VDM,ECM,ECM_Diesel,ECM_HEV,ECM_HEVDSL,PCM,PCM_HEV,TCM_DSL,ABS_ESC,IPMA_ADAS,PSCM,AWD_DLCM
 SG_ WakeAlarm2_T_Rq : 31|15@0+ (1,0) [0|32767] "minute"  GENERIC
 SG_ WakeAlarm2_B_Typ : 18|1@0+ (1,0) [0|1] "SED"  GENERIC
 SG_ TrlrAlarmSpprt_D_Stat : 20|2@0+ (1,0) [0|3] "SED"  GENERIC

BO_ 138 ActiveFrontStrg_Stat2_FD1: 8 GWM
 SG_ SteWhlRelCalib_T_Actl : 7|8@0+ (1,0) [0|255] "ms"  ABS_ESC
 SG_ SteWhlRelCalib_An_Sns : 15|15@0+ (0.1,-1600) [-1600|1676.5] "deg"  CMR_DSMC,ABS_ESC,PSCM,TCCM

BO_ 131 Steering_Data_FD1: 8 SCCM
 SG_ TurnLghtSwtch_D_Arb : 55|4@0+ (1,0) [0|15] "SED"  IPMA_ADAS
 SG_ HeadLghtHiCtrl_D_RqAhb : 43|3@0+ (1,0) [0|7] "SED"  HCM,GENERIC
 SG_ AhbStat_B_Dsply : 33|1@0+ (1,0) [0|1] "SED"  GENERIC
 SG_ WiprFrontSwtch_D_Stat : 47|4@0+ (1,0) [0|15] "SED"  GENERIC
 SG_ HeadLghtHiOn_B_StatAhb : 34|1@0+ (1,0) [0|1] "SED"  IPMA_ADAS
 SG_ HeadLghtHiFlash_D_Actl : 36|2@0+ (1,0) [0|3] "SED"  HCM,IPMA_ADAS
 SG_ TjaButtnOnOffPress : 40|1@0+ (1,0) [0|1] "SED"  ECM,ECM_Diesel,ECM_HEVDSL,IPMA_ADAS,PCM,PCM_HEV
 SG_ AccButtnGapTogglePress : 32|1@0+ (1,0) [0|1] "SED"  IPMA_ADAS
 SG_ WiprFront_D_Stat : 3|4@0+ (1,0) [0|15] "SED"  SOBDMC_HPCM,HCM,ABS_ESC,ECM,ECM_Diesel,ECM_HEV,ECM_HEVDSL,IPMA_ADAS,PCM,PCM_HEV,AWD_DLCM
 SG_ TurnLghtSwtch_D_Stat : 5|2@0+ (1,0) [0|3] "SED"  HCM,IPMA_ADAS,PSCM
 SG_ LghtAmb_D_Sns : 15|3@0+ (1,0) [0|7] "SED"  HCM,IPMA_ADAS
 SG_ AccButtnGapIncPress : 11|1@0+ (1,0) [0|1] "SED"  IPMA_ADAS
 SG_ AccButtnGapDecPress : 12|1@0+ (1,0) [0|1] "SED"  IPMA_ADAS
 SG_ AslButtnOnOffPress : 9|1@0+ (1,0) [0|1] "SED"  ECM,ECM_Diesel,ECM_HEV,ECM_HEVDSL,PCM,PCM_HEV,IPMA_ADAS
 SG_ AslButtnOnOffCnclPress : 10|1@0+ (1,0) [0|1] "SED"  ECM,ECM_Diesel,ECM_HEV,ECM_HEVDSL,PCM,PCM_HEV,IPMA_ADAS
 SG_ CcButtnOnPress : 37|1@0+ (1,0) [0|1] "SED"  ECM,ECM_Diesel,ECM_HEV,ECM_HEVDSL,IPMA_ADAS,PCM,PCM_HEV
 SG_ CcButtnOnOffPress : 38|1@0+ (1,0) [0|1] "SED"  ECM,ECM_Diesel,ECM_HEV,ECM_HEVDSL,IPMA_ADAS,PCM,PCM_HEV
 SG_ CcButtnOnOffCnclPress : 39|1@0+ (1,0) [0|1] "SED"  ECM,ECM_Diesel,ECM_HEV,ECM_HEVDSL,IPMA_ADAS,PCM,PCM_HEV
 SG_ CcButtnOffPress : 24|1@0+ (1,0) [0|1] "SED"  ECM,ECM_Diesel,ECM_HEV,ECM_HEVDSL,IPMA_ADAS,PCM,PCM_HEV
 SG_ CcAsllButtnResPress : 25|1@0+ (1,0) [0|1] "SED"  ECM,ECM_Diesel,ECM_HEV,ECM_HEVDSL,IPMA_ADAS,PCM,PCM_HEV
 SG_ CcAslButtnSetPress : 26|1@0+ (1,0) [0|1] "SED"  ECM,ECM_Diesel,ECM_HEV,ECM_HEVDSL,PCM,PCM_HEV
 SG_ CcAslButtnSetIncPress : 27|1@0+ (1,0) [0|1] "SED"  ABS_ESC,ECM,ECM_Diesel,ECM_HEV,ECM_HEVDSL,IPMA_ADAS,PCM,PCM_HEV
 SG_ CcAslButtnSetDecPress : 28|1@0+ (1,0) [0|1] "SED"  ABS_ESC,ECM,ECM_Diesel,ECM_HEV,ECM_HEVDSL,IPMA_ADAS,PCM,PCM_HEV
 SG_ CcAslButtnResIncPress : 29|1@0+ (1,0) [0|1] "SED"  ABS_ESC,ECM,ECM_Diesel,ECM_HEV,ECM_HEVDSL,IPMA_ADAS,PCM,PCM_HEV
 SG_ CcAslButtnResDecPress : 30|1@0+ (1,0) [0|1] "SED"  ECM,ECM_Diesel,ECM_HEV,ECM_HEVDSL,PCM,PCM_HEV
 SG_ CcAslButtnOnPress : 31|1@0+ (1,0) [0|1] "SED"  ECM,ECM_Diesel,ECM_HEV,ECM_HEVDSL,IPMA_ADAS,PCM,PCM_HEV
 SG_ CcAslButtnOnOffCncl : 16|1@0+ (1,0) [0|1] "SED"  ECM,ECM_Diesel,ECM_HEV,ECM_HEVDSL,PCM,PCM_HEV
 SG_ CcAslButtnOffCnclPress : 17|1@0+ (1,0) [0|1] "SED"  ECM,ECM_Diesel,ECM_HEV,ECM_HEVDSL,PCM,PCM_HEV
 SG_ CcAslButtnIndxIncPress : 18|1@0+ (1,0) [0|1] "SED"  ECM,ECM_Diesel,ECM_HEV,ECM_HEVDSL,PCM,PCM_HEV
 SG_ CcAslButtnIndxDecPress : 19|1@0+ (1,0) [0|1] "SED"  ECM,ECM_Diesel,ECM_HEV,ECM_HEVDSL,PCM,PCM_HEV
 SG_ CcAslButtnDeny_B_Actl : 20|1@0+ (1,0) [0|1] "SED"  ECM,ECM_Diesel,ECM_HEV,ECM_HEVDSL,IPMA_ADAS,PCM,PCM_HEV
 SG_ CcAslButtnCnclResPress : 21|1@0+ (1,0) [0|1] "SED"  ABS_ESC,ECM,ECM_Diesel,ECM_HEV,ECM_HEVDSL,IPMA_ADAS,PCM,PCM_HEV
 SG_ CcAslButtnCnclPress : 8|1@0+ (1,0) [0|1] "SED"  ABS_ESC,ECM,ECM_Diesel,ECM_HEV,ECM_HEVDSL,IPMA_ADAS,PCM,PCM_HEV
 SG_ LaSwtchPos_D_Stat : 23|2@0+ (1,0) [0|3] "SED"  IPMA_ADAS
 SG_ HeadLghtHiFlash_D_Stat : 7|2@0+ (1,0) [0|3] "SED"  HCM,GENERIC

BO_ 787 Power_Liftgate_Stat_FD1: 8 GWM
 SG_ PwTgateStepMsgTxt_B_Rq : 0|1@0+ (1,0) [0|1] "SED"  GENERIC
 SG_ PwTgateInhbtMsgTxt_B_Rq : 8|1@0+ (1,0) [0|1] "SED"  GENERIC
 SG_ DrLckCnt_No_ActlTgate : 12|4@0+ (1,0) [0|15] "unitless"  GENERIC
 SG_ DrTgateChime2_D_Rq : 15|3@0+ (1,0) [0|7] "SED"  GENERIC
 SG_ DrTGate_D_Rq : 2|2@0+ (1,0) [0|3] "SED"  ECM,ECM_Diesel,ECM_HEVDSL,PCM,PCM_HEV
 SG_ PwLftgtIntSw_B_Stat : 5|1@0+ (1,0) [0|1] "SED"  GENERIC
 SG_ Power_Liftgate_Mode_Stt : 4|2@0+ (1,0) [0|3] "SED"  GENERIC
 SG_ PwTgateMsgTxt_B_Rq : 6|1@0+ (1,0) [0|1] "SED"  GENERIC
 SG_ PwTgateLamp_B_Rq : 7|1@0+ (1,0) [0|1] "SED"  GENERIC

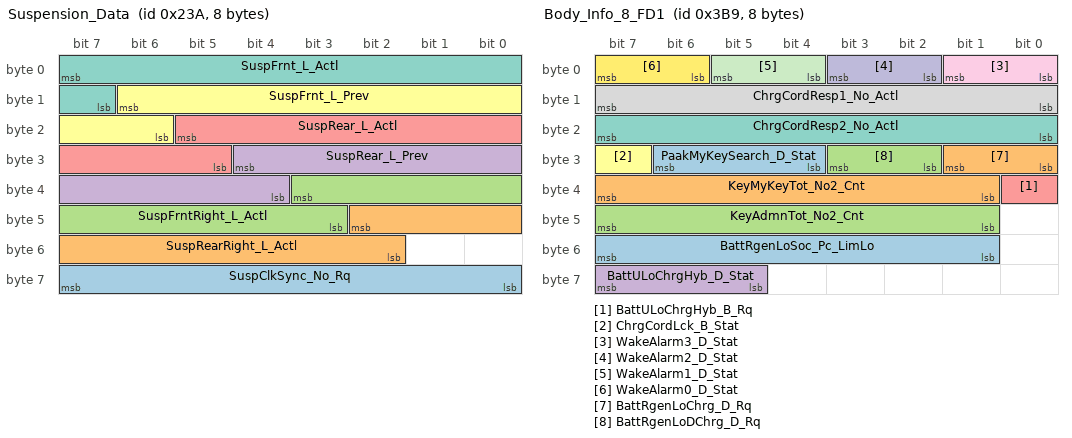
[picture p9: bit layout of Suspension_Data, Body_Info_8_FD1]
BO_ 570 Suspension_Data: 8 VDM
 SG_ SuspClkSync_No_Rq : 63|8@0+ (1,0) [0|253] "unitless"  GWM,IPMA_ADAS
 SG_ SuspRearRight_L_Actl : 42|9@0+ (0.782779,-200) [-200|199.21729] "millimeter"  HCM,GWM,ABS_ESC,PSCM,IPMA_ADAS
 SG_ SuspFrntRight_L_Actl : 35|9@0+ (0.782779,-200) [-200|199.21729] "millimeter"  HCM,ABS_ESC,PSCM,GWM,IPMA_ADAS
 SG_ SuspRear_L_Prev : 28|9@0+ (0.782779,-200) [-200|199.21729] "millimeter"  HCM,ABS_ESC,GWM
 SG_ SuspRear_L_Actl : 21|9@0+ (0.782779,-200) [-200|199.21729] "millimeter"  HCM,ABS_ESC,PSCM,GWM,IPMA_ADAS
 SG_ SuspFrnt_L_Prev : 14|9@0+ (0.782779,-200) [-200|199.21729] "millimeter"  HCM,ABS_ESC,GWM
 SG_ SuspFrnt_L_Actl : 7|9@0+ (0.782779,-200) [-200|199.21729] "millimeter"  HCM,PSCM,ABS_ESC,GWM,IPMA_ADAS

BO_ 953 Body_Info_8_FD1: 8 BCM
 SG_ PaakMyKeySearch_D_Stat : 30|3@0+ (1,0) [0|7] "SED"  GENERIC
 SG_ KeyMyKeyTot_No2_Cnt : 39|7@0+ (1,0) [0|127] "unitless"  GENERIC
 SG_ KeyAdmnTot_No2_Cnt : 47|7@0+ (1,0) [0|127] "unitless"  GENERIC
 SG_ BattULoChrgHyb_D_Stat : 63|3@0+ (1,0) [0|7] "SED"  GENERIC
 SG_ BattULoChrgHyb_B_Rq : 32|1@0+ (1,0) [0|1] "SED"  SOBDMC_HPCM
 SG_ ChrgCordLck_B_Stat : 31|1@0+ (1,0) [0|1] "SED"  GENERIC
 SG_ ChrgCordResp2_No_Actl : 23|8@0+ (1,0) [0|255] "unitless"  GENERIC
 SG_ ChrgCordResp1_No_Actl : 15|8@0+ (1,0) [0|255] "unitless"  GENERIC
 SG_ WakeAlarm3_D_Stat : 1|2@0+ (1,0) [0|3] "SED"  GENERIC
 SG_ WakeAlarm2_D_Stat : 3|2@0+ (1,0) [0|3] "SED"  GENERIC
 SG_ WakeAlarm1_D_Stat : 5|2@0+ (1,0) [0|3] "SED"  ECM_Diesel,ECM_HEV,ECM_HEVDSL,PCM,PCM_HEV,ECM
 SG_ WakeAlarm0_D_Stat : 7|2@0+ (1,0) [0|3] "SED"  SOBDMC_HPCM,GENERIC
 SG_ BattRgenLoSoc_Pc_LimLo : 55|7@0+ (1,0) [0|100] "percent"  GENERIC
 SG_ BattRgenLoChrg_D_Rq : 25|2@0+ (1,0) [0|3] "SED"  PCM,PCM_HEV
 SG_ BattRgenLoDChrg_D_Rq : 27|2@0+ (1,0) [0|3] "SED"  PCM,PCM_HEV

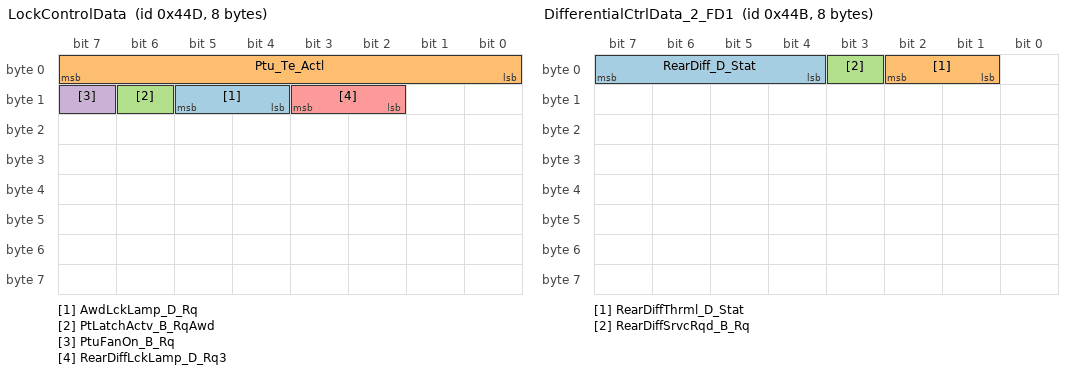
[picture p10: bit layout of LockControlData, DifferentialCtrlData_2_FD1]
BO_ 1101 LockControlData: 8 AWD_DLCM
 SG_ AwdLckLamp_D_Rq : 13|2@0+ (1,0) [0|3] "SED"  GWM
 SG_ Ptu_Te_Actl : 7|8@0+ (1,-50) [-50|204] "degC"  ECM,ECM_Diesel,ECM_HEVDSL,PCM,GWM
 SG_ PtLatchActv_B_RqAwd : 14|1@0+ (1,0) [0|1] "SED"  ECM,ECM_Diesel,ECM_HEV,ECM_HEVDSL,PCM,PCM_HEV,GWM
 SG_ PtuFanOn_B_Rq : 15|1@0+ (1,0) [0|1] "SED"  ECM,ECM_Diesel,ECM_HEV,ECM_HEVDSL,PCM,PCM_HEV,GWM
 SG_ RearDiffLckLamp_D_Rq3 : 11|2@0+ (1,0) [0|3] "SED"  GWM

BO_ 1099 DifferentialCtrlData_2_FD1: 8 DCMR_ELSD
 SG_ RearDiff_D_Stat : 7|4@0+ (1,0) [0|15] "SED"  ABS_ESC,PCM
 SG_ RearDiffThrml_D_Stat : 2|2@0+ (1,0) [0|3] "SED"  ECM,ABS_ESC,PCM
 SG_ RearDiffSrvcRqd_B_Rq : 3|1@0+ (1,0) [0|1] "SED"  ABS_ESC

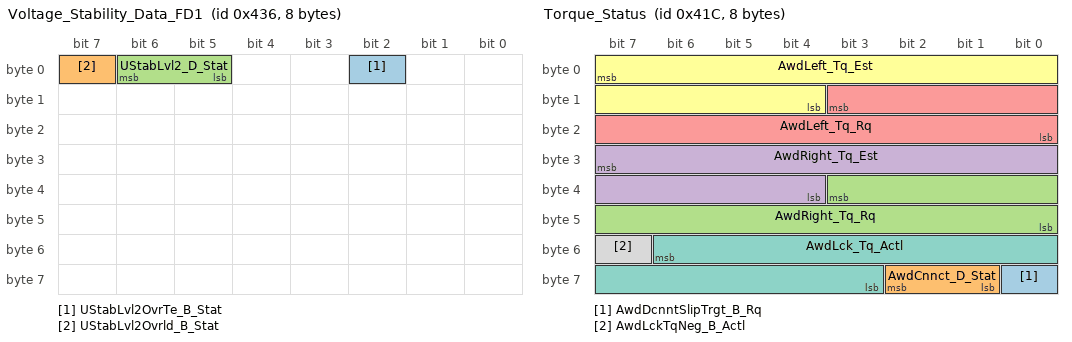
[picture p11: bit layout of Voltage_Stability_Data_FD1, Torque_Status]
BO_ 1078 Voltage_Stability_Data_FD1: 8 GWM
 SG_ UStabLvl2OvrTe_B_Stat : 2|1@0+ (1,0) [0|1] "SED"  ECM,ECM_Diesel,ECM_HEVDSL,PCM,PCM_HEV
 SG_ UStabLvl2Ovrld_B_Stat : 7|1@0+ (1,0) [0|1] "SED"  ECM,ECM_Diesel,ECM_HEVDSL,PCM,PCM_HEV
 SG_ UStabLvl2_D_Stat : 6|2@0+ (1,0) [0|3] "SED"  ECM,ECM_Diesel,ECM_HEVDSL,PCM,PCM_HEV

BO_ 1052 Torque_Status: 8 AWD_DLCM
 SG_ AwdDcnntSlipTrgt_B_Rq : 56|1@0+ (1,0) [0|1] "SED"  ABS_ESC,GWM
 SG_ AwdCnnct_D_Stat : 58|2@0+ (1,0) [0|3] "SED"  ABS_ESC,GWM
 SG_ AwdRight_Tq_Rq : 35|12@0+ (1,0) [0|4093] "Nm"  ABS_ESC,GWM
 SG_ AwdRight_Tq_Est : 31|12@0+ (1,0) [0|4093] "Nm"  ABS_ESC,PCM,PCM_HEV,GWM
 SG_ AwdLeft_Tq_Rq : 11|12@0+ (1,0) [0|4093] "Nm"  ABS_ESC,GWM
 SG_ AwdLeft_Tq_Est : 7|12@0+ (1,0) [0|4093] "Nm"  ABS_ESC,PCM,PCM_HEV,GWM
 SG_ AwdLck_Tq_Actl : 54|12@0+ (1,0) [0|4093] "Nm"  SOBDMC_HPCM,ABS_ESC,PCM,PCM_HEV,PSCM,TCM,TCM_DSL,GWM
 SG_ AwdLckTqNeg_B_Actl : 55|1@0+ (1,0) [0|1] "SED"  ABS_ESC,PSCM,GWM,TCM,TCM_DSL

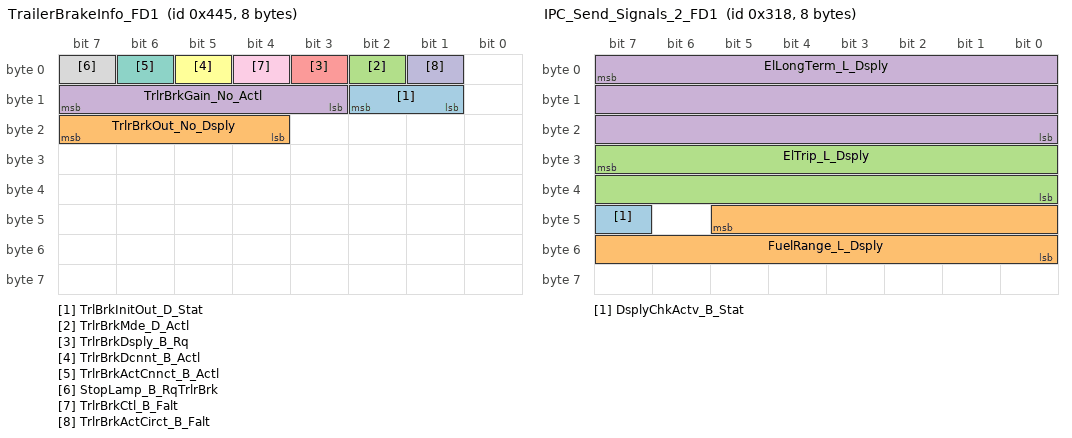
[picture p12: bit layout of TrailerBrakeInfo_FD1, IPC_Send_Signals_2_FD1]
BO_ 1093 TrailerBrakeInfo_FD1: 8 TRM_ITRM
 SG_ TrlBrkInitOut_D_Stat : 10|2@0+ (1,0) [0|3] "SED"  GENERIC
 SG_ TrlrBrkOut_No_Dsply : 23|4@0+ (1,0) [0|15] "unitless"  GENERIC
 SG_ TrlrBrkMde_D_Actl : 2|1@0+ (1,0) [0|1] "SED"  TCCM
 SG_ TrlrBrkGain_No_Actl : 15|5@0+ (0.5,0) [0|15.5] "unitless"  GENERIC
 SG_ TrlrBrkDsply_B_Rq : 3|1@0+ (1,0) [0|1] "SED"  GENERIC
 SG_ TrlrBrkDcnnt_B_Actl : 5|1@0+ (1,0) [0|1] "SED"  VDM,GENERIC
 SG_ TrlrBrkActCnnct_B_Actl : 6|1@0+ (1,0) [0|1] "SED"  TCM,VDM,ECM,ECM_Diesel,ECM_HEV,ECM_HEVDSL,PCM,PCM_HEV,TCM_DSL,ABS_ESC,PSCM,TCCM,SOBDMC_HPCM,IPMA_ADAS
 SG_ StopLamp_B_RqTrlrBrk : 7|1@0+ (1,0) [0|1] "SED"  GENERIC
 SG_ TrlrBrkCtl_B_Falt : 4|1@0+ (1,0) [0|1] "SED"  IPMA_ADAS
 SG_ TrlrBrkActCirct_B_Falt : 1|1@0+ (1,0) [0|1] "SED"  IPMA_ADAS

BO_ 837 VeyDynamics_Data: 8 VDM
 SG_ SuspVLimBRq_No_Cs : 39|8@0+ (1,0) [0|255] "Unitless"  ABS_ESC,GWM
 SG_ SuspVLimBRq_No_Cnt : 47|4@0+ (1,0) [0|15] "Unitless"  ABS_ESC,GWM
 SG_ VdmSustnActv_B_Rq : 12|1@0+ (1,0) [0|1] "SED"  GWM
 SG_ VehCurb_M_Actl : 43|10@0+ (5,0) [0|5105] "kilogram"  GWM,ABS_ESC
 SG_ VehGvwr_M_Actl : 49|10@0+ (10,0) [0|10210] "kilogram"  GWM
 SG_ Ccd_B_Falt : 24|1@0+ (1,0) [0|1] "SED"  GWM,GENERIC
 SG_ SuspVLim_B_Rq : 18|1@0+ (1,0) [0|1] "SED"  ABS_ESC,PCM,ECM_HEV,GWM,ECM
 SG_ SelDrvMdeSusp_D_Stat : 20|2@0+ (1,0) [0|3] "SED"  GWM,ABS_ESC
 SG_ AdptDrvMdePt_D_Rq : 23|3@0+ (1,0) [0|7] "SED"  GWM,ABS_ESC
 SG_ AdptDrvMdeChassis_D_Rq : 10|3@0+ (1,0) [0|7] "SED"  GWM,ABS_ESC
 SG_ AirSprngRateRr_D_Rq : 27|2@0+ (1,0) [0|3] "SED"  GWM,GENERIC
 SG_ AirSprngRateRl_D_Rq : 29|2@0+ (1,0) [0|3] "SED"  GWM,GENERIC
 SG_ SuspType_B_Stat : 25|1@0+ (1,0) [0|1] "SED"  ECM_HEV,GWM,ECM,PCM
 SG_ AirSprngRateFr_D_Rq : 31|2@0+ (1,0) [0|3] "SED"  GWM,GENERIC
 SG_ AirSprngRateFl_D_Rq : 17|2@0+ (1,0) [0|3] "SED"  GWM,GENERIC
 SG_ AirSusp_D_Stat : 1|2@0+ (1,0) [0|3] "SED"  GWM,GENERIC
 SG_ AirSuspMsgTxt_D_Rq : 3|2@0+ (1,0) [0|3] "SED"  GWM,GENERIC
 SG_ SuspDrvMde_D_Stat : 15|3@0+ (1,0) [0|7] "SED"  GWM,ABS_ESC
 SG_ CcdMsgTxt_D_RqDsply : 7|4@0+ (1,0) [0|15] "SED"  GWM,ECM,ECM_Diesel,ECM_HEVDSL,PCM,PCM_HEV,ABS_ESC,PSCM,AWD_DLCM

BO_ 792 IPC_Send_Signals_2_FD1: 8 IPC
 SG_ DsplyChkActv_B_Stat : 47|1@0+ (1,0) [0|1] "SED"  GENERIC
 SG_ FuelRange_L_Dsply : 45|14@0+ (0.1,0) [0|1638.3] "km"  ECM_Diesel,ECM_HEVDSL,ECM
 SG_ ElTrip_L_Dsply : 31|16@0+ (0.1,0) [0|6553.3] "unitless"  GENERIC
 SG_ ElLongTerm_L_Dsply : 7|24@0+ (0.1,0) [0|1677721.3] "unitless"  GENERIC

BO_ 968 Cluster_Lighting_Rq_FD1: 8 IPC
 SG_ IpcLvl_B_Type : 56|1@0+ (1,0) [0|1] "SED"  ECM_Diesel,ECM_HEV,PCM,PCM_HEV
 SG_ RvltnMatchAllw_D_Rq : 58|2@0+ (1,0) [0|3] "SED"  ECM,PCM
 SG_ BrkDrvMde_D_Rq : 18|3@0+ (1,0) [0|7] "SED"  ABS_ESC
 SG_ LnchCtl_N_Rq : 55|8@0+ (50,0) [0|12750] "rpm"  ABS_ESC,PCM,PCM_HEV
 SG_ LnchCtl_D_Rq : 63|2@0+ (1,0) [0|3] "SED"  ABS_ESC,PCM,PCM_HEV
 SG_ CurrentColor_CmdGage : 43|4@0+ (1,0) [0|15] "SED"  GENERIC
 SG_ BlendedColor_CmdGage : 25|2@0+ (1,0) [0|3] "SED"  GENERIC
 SG_ BlendColorRed_CmdGage : 47|4@0+ (1,0) [0|15] "SED"  GENERIC
 SG_ BlendColorGrn_CmdGage : 35|4@0+ (1,0) [0|15] "SED"  GENERIC
 SG_ BlendColorBlue_CmdGage : 39|4@0+ (1,0) [0|15] "SED"  GENERIC
 SG_ Dimming_Level_Cmd : 1|2@0+ (1,0) [0|3] "SED"  GENERIC
 SG_ Current_Color_Cmd : 23|4@0+ (1,0) [0|15] "SED"  GENERIC
 SG_ BlendedColorRed_Cmd : 11|4@0+ (1,0) [0|15] "SED"  GENERIC
 SG_ BlendedColorGreen_Cmd : 15|4@0+ (1,0) [0|15] "SED"  GENERIC
 SG_ BlendedColorBlue_Cmd : 5|4@0+ (1,0) [0|15] "SED"  GENERIC
 SG_ BlendedColor_Cmd : 7|2@0+ (1,0) [0|3] "SED"  GENERIC
 SG_ SuspDrvMde_D_Rq : 61|3@0+ (1,0) [0|7] "SED"  VDM,GENERIC
 SG_ SlMde_D_Rq : 27|2@0+ (1,0) [0|3] "SED"  ECM_HEV,ECM,ECM_Diesel,ECM_HEVDSL,PCM,PCM_HEV
 SG_ IsaOffst_D_Rq : 31|4@0+ (1,0) [0|15] "SED"  ECM_HEV,ECM,ECM_Diesel,ECM_HEVDSL,PCM,PCM_HEV

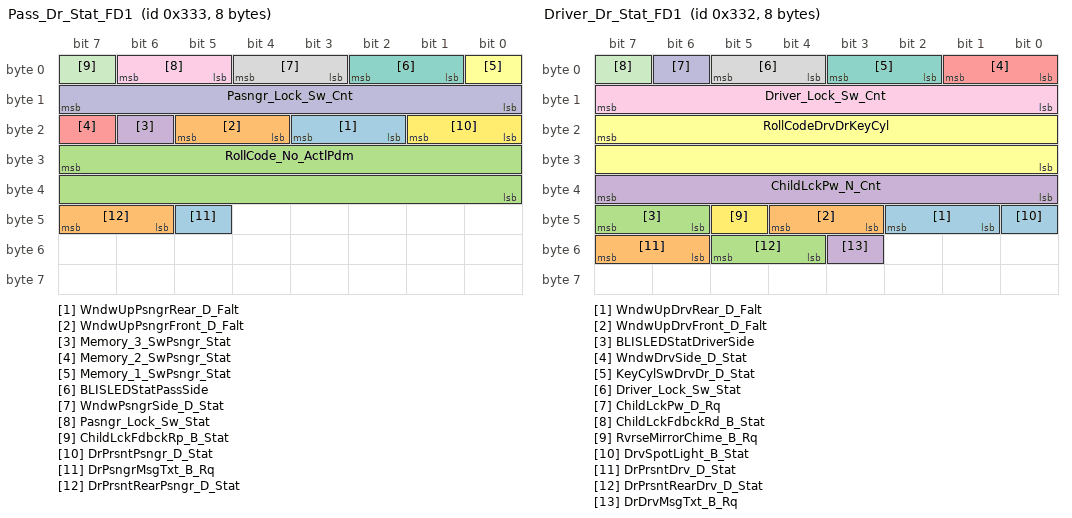
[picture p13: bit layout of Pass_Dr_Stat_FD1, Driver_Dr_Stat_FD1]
BO_ 819 Pass_Dr_Stat_FD1: 8 PDM
 SG_ WndwUpPsngrRear_D_Falt : 19|2@0+ (1,0) [0|3] "SED"  IPMA_ADAS
 SG_ WndwUpPsngrFront_D_Falt : 21|2@0+ (1,0) [0|3] "SED"  IPMA_ADAS
 SG_ RollCode_No_ActlPdm : 31|16@0+ (1,0) [0|65535] "Unitless"  GENERIC
 SG_ Memory_3_SwPsngr_Stat : 22|1@0+ (1,0) [0|1] "SED"  GENERIC
 SG_ Memory_2_SwPsngr_Stat : 23|1@0+ (1,0) [0|1] "SED"  GENERIC
 SG_ Memory_1_SwPsngr_Stat : 0|1@0+ (1,0) [0|1] "SED"  GENERIC
 SG_ BLISLEDStatPassSide : 2|2@0+ (1,0) [0|3] "SED"  IPMA_ADAS
 SG_ WndwPsngrSide_D_Stat : 4|2@0+ (1,0) [0|3] "SED"  ECM,ECM_Diesel,ECM_HEV,ECM_HEVDSL,PCM
 SG_ Pasngr_Lock_Sw_Stat : 6|2@0+ (1,0) [0|3] "SED"  GENERIC
 SG_ Pasngr_Lock_Sw_Cnt : 15|8@0+ (1,0) [0|255] "Cnt"  GENERIC
 SG_ ChildLckFdbckRp_B_Stat : 7|1@0+ (1,0) [0|1] "SED"  GENERIC
 SG_ DrPrsntPsngr_D_Stat : 17|2@0+ (1,0) [0|3] "SED"  GENERIC
 SG_ DrPsngrMsgTxt_B_Rq : 45|1@0+ (1,0) [0|1] "SED"  GENERIC
 SG_ DrPrsntRearPsngr_D_Stat : 47|2@0+ (1,0) [0|3] "SED"  GENERIC

BO_ 818 Driver_Dr_Stat_FD1: 8 DDM
 SG_ WndwUpDrvRear_D_Falt : 42|2@0+ (1,0) [0|3] "SED"  IPMA_ADAS
 SG_ WndwUpDrvFront_D_Falt : 44|2@0+ (1,0) [0|3] "SED"  IPMA_ADAS
 SG_ BLISLEDStatDriverSide : 47|2@0+ (1,0) [0|3] "SED"  IPMA_ADAS
 SG_ ChildLckPw_N_Cnt : 39|8@0+ (1,0) [0|255] "unitless"  GENERIC
 SG_ WndwDrvSide_D_Stat : 1|2@0+ (1,0) [0|3] "SED"  ECM,ECM_Diesel,ECM_HEVDSL,PCM
 SG_ RollCodeDrvDrKeyCyl : 23|16@0+ (1,0) [0|65535] "Unitless"  GENERIC
 SG_ KeyCylSwDrvDr_D_Stat : 3|2@0+ (1,0) [0|3] "SED"  GENERIC
 SG_ Driver_Lock_Sw_Stat : 5|2@0+ (1,0) [0|3] "SED"  GENERIC
 SG_ Driver_Lock_Sw_Cnt : 15|8@0+ (1,0) [0|255] "Cnt"  GENERIC
 SG_ ChildLckPw_D_Rq : 6|1@0+ (1,0) [0|1] "SED"  GENERIC
 SG_ ChildLckFdbckRd_B_Stat : 7|1@0+ (1,0) [0|1] "SED"  GENERIC
 SG_ RvrseMirrorChime_B_Rq : 45|1@0+ (1,0) [0|1] "SED"  GENERIC
 SG_ DrvSpotLight_B_Stat : 40|1@0+ (1,0) [0|1] "SED"  GENERIC
 SG_ DrPrsntDrv_D_Stat : 55|2@0+ (1,0) [0|3] "SED"  PCM,PCM_HEV,ABS_ESC
 SG_ DrPrsntRearDrv_D_Stat : 53|2@0+ (1,0) [0|3] "SED"  GENERIC
 SG_ DrDrvMsgTxt_B_Rq : 51|1@0+ (1,0) [0|1] "SED"  GENERIC

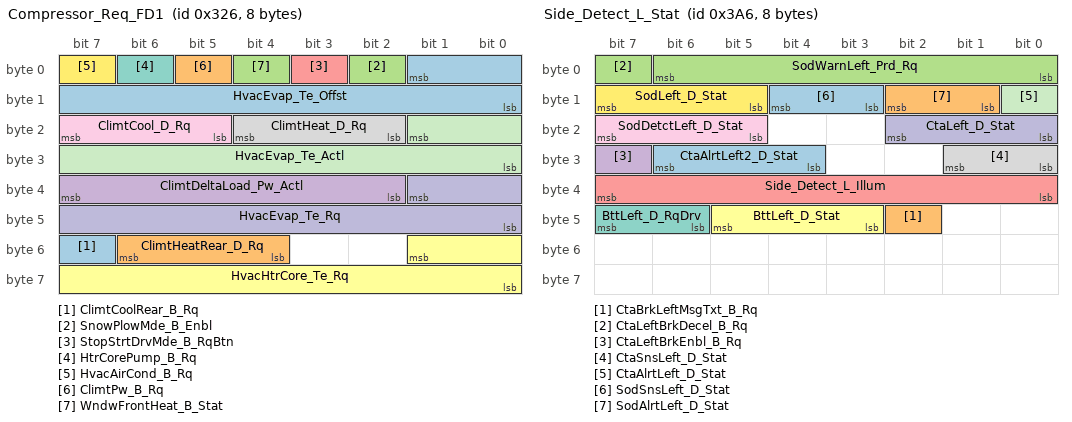
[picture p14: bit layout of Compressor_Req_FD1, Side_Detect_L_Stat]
BO_ 806 Compressor_Req_FD1: 8 HVAC_RCCM
 SG_ ClimtCoolRear_B_Rq : 55|1@0+ (1,0) [0|1] "SED"  SOBDMC_HPCM,GENERIC
 SG_ ClimtHeatRear_D_Rq : 54|3@0+ (1,0) [0|7] "SED"  PCM,SOBDMC_HPCM
 SG_ SnowPlowMde_B_Enbl : 2|1@0+ (1,0) [0|1] "SED"  GENERIC
 SG_ ClimtDeltaLoad_Pw_Actl : 39|6@0+ (50,-1600) [-1600|1450] "watts"  ECM,ECM_Diesel,ECM_HEV,ECM_HEVDSL,PCM,PCM_HEV
 SG_ StopStrtDrvMde_B_RqBtn : 3|1@0+ (1,0) [0|1] "SED"  ECM,ECM_Diesel,ECM_HEVDSL,PCM,PCM_HEV
 SG_ HvacHtrCore_Te_Rq : 49|10@0+ (0.25,-50) [-50|205.75] "degC"  SOBDMC_HPCM,ECM,ECM_Diesel,ECM_HEV,ECM_HEVDSL,PCM_HEV
 SG_ HtrCorePump_B_Rq : 6|1@0+ (1,0) [0|1] "SED"  ECM,ECM_Diesel,ECM_HEV,ECM_HEVDSL,PCM,PCM_HEV
 SG_ ClimtHeat_D_Rq : 20|3@0+ (1,0) [0|7] "SED"  SOBDMC_HPCM,ECM,ECM_Diesel,ECM_HEV,ECM_HEVDSL,PCM,PCM_HEV
 SG_ ClimtCool_D_Rq : 23|3@0+ (1,0) [0|7] "SED"  SOBDMC_HPCM,ECM,ECM_Diesel,ECM_HEV,ECM_HEVDSL,PCM,PCM_HEV
 SG_ HvacEvap_Te_Rq : 33|10@0+ (0.125,-50) [-50|77.875] "Degrees C"  ECM_HEV,SOBDMC_HPCM,ECM,ECM_Diesel,ECM_HEVDSL,PCM,PCM_HEV
 SG_ HvacEvap_Te_Actl : 17|10@0+ (0.125,-50) [-50|77.75] "Degrees C"  SOBDMC_HPCM,ECM,ECM_Diesel,ECM_HEVDSL,PCM,PCM_HEV
 SG_ HvacAirCond_B_Rq : 7|1@0+ (1,0) [0|1] "SED"  ECM,ECM_Diesel,ECM_HEVDSL,PCM,PCM_HEV
 SG_ HvacEvap_Te_Offst : 1|10@0+ (0.125,-50) [-50|77.875] "Degrees C"  ECM,ECM_Diesel,ECM_HEVDSL,PCM,PCM_HEV
 SG_ ClimtPw_B_Rq : 5|1@0+ (1,0) [0|1] "SED"  ECM,ECM_Diesel,ECM_HEVDSL,PCM,PCM_HEV
 SG_ WndwFrontHeat_B_Stat : 4|1@0+ (1,0) [0|1] "SED"  GENERIC

BO_ 765 Mc_Send_Signals_2_FD1: 8 IPC
 SG_ BalrSwtch_D_Stat : 57|2@0+ (1,0) [0|3] "SED"  IPMA_ADAS
 SG_ BalrMde_D_Rq : 59|2@0+ (1,0) [0|3] "SED"  IPMA_ADAS
 SG_ RstrnOnPsngr_D_RqMnu : 63|4@0+ (1,0) [0|15] "SED"  GENERIC
 SG_ WaitToStartLamp_D_Falt : 50|2@0+ (1,0) [0|3] "SED"  ECM,ECM_Diesel,ECM_HEVDSL
 SG_ EsaOn_B_Rq : 15|1@0+ (1,0) [0|1] "SED"  PSCM
 SG_ BttOn_B_Rq : 26|1@0+ (1,0) [0|1] "SED"  IPMA_ADAS
 SG_ Btt_L_Actl : 39|7@0+ (0.1,0) [0|12.5] "meter"  IPMA_ADAS
 SG_ RearDiffLck_D_RqArb : 25|2@0+ (1,0) [0|3] "SED"  TCCM
 SG_ AwdMde_D_RqArb : 47|3@0+ (1,0) [0|7] "SED"  TCCM
 SG_ SelDrvMdeTxtReset_B_Rq : 40|1@0+ (1,0) [0|1] "SED"  ABS_ESC
 SG_ AutoTowAllw_D_RqMnu : 52|2@0+ (1,0) [0|3] "SED"  PCM_HEV,ECM,ECM_Diesel,ECM_HEVDSL,PCM
 SG_ DrvInputRequired_B_Rq : 32|1@0+ (1,0) [0|1] "SED"  GENERIC
 SG_ SelDrvMdeDsply_B_Avail : 41|1@0+ (1,0) [0|1] "SED"  ABS_ESC
 SG_ EngExhMdeQuiet_D_Rq : 17|2@0+ (1,0) [0|3] "SED"  GENERIC
 SG_ AirSusp_D_RqDrv : 31|2@0+ (1,0) [0|3] "SED"  VDM,GENERIC
 SG_ Mc_VehUntTrpCoUsrSel_St : 23|1@0+ (1,0) [0|1] "SED"  ECM_Diesel,ECM_HEV,ECM_HEVDSL,PCM_HEV,PCM
 SG_ Mc_VehUnitTempUsrSel_St : 22|1@0+ (1,0) [0|1] "SED"  GENERIC
 SG_ Mc_VehDayNightUsrSel_St : 14|3@0+ (1,0) [0|7] "SED"  GENERIC
 SG_ Mc_VehTimeFrmtUsrSel_St : 1|2@0+ (1,0) [0|3] "SED"  GENERIC
 SG_ Mc_VehThemeUsrSel_St : 11|4@0+ (1,0) [0|15] "SED"  GENERIC
 SG_ Mc_VehLangUsrSel_St : 7|6@0+ (1,0) [0|63] "SED"  GENERIC
 SG_ AwdRnge_D_ActlIpc : 29|3@0+ (1,0) [0|7] "SED"  TCM,ABS_ESC,ECM,ECM_Diesel,ECM_HEVDSL,PCM,PCM_HEV,TCCM,TCM_DSL
 SG_ AwdDrvMde_D_Rq : 44|3@0+ (1,0) [0|7] "SED"  TCCM
 SG_ EngExhMdeQuiet_D2_Rq : 55|3@0+ (1,0) [0|7] "SED"  PCM,ECM
 SG_ BrkLineLck_D_Rq : 19|2@0+ (1,0) [0|3] "SED"  ABS_ESC
 SG_ EdmSailMde_B_RqDrv : 48|1@0+ (1,0) [0|1] "SED"  ECM,ECM_Diesel,ECM_HEV,ECM_HEVDSL,PCM,PCM_HEV
 SG_ Running_Board_Cmd : 21|2@0+ (1,0) [0|3] "SED"  GENERIC

BO_ 518 DifferentialCtrlData_1_FD1: 8 DCMR_ELSD
 SG_ RearDiffLck_Tq_Actl2 : 7|14@0+ (1,0) [0|16381] "Nm"  TCCM,ABS_ESC,ECM,ECM_HEVDSL,PCM
 SG_ LsdCluPlate_Te_Est : 23|9@0+ (1,-40) [-40|470] "degC"  ECM,PCM

BO_ 559 ElecHorizon_Data2_FD1: 8 APIM
 SG_ EhData2_No_Actl : 7|64@0+ (1,0) [0|1.84467440737096E+019] "unitless"  IPMA_ADAS,ECM,ECM_Diesel,ECM_HEV,ECM_HEVDSL,PCM,PCM_HEV,HCM

BO_ 558 ElecHorizon_Data1_FD1: 8 APIM
 SG_ EhData1_No_Actl : 7|64@0+ (1,0) [0|1.84467440737096E+019] "unitless"  IPMA_ADAS,ECM,ECM_Diesel,ECM_HEV,ECM_HEVDSL,PCM,PCM_HEV,HCM

BO_ 934 Side_Detect_L_Stat: 8 IPMA_ADAS
 SG_ CtaAlrtLeft2_D_Stat : 30|3@0+ (1,0) [0|7] "SED"  GWM
 SG_ CtaBrkLeftMsgTxt_B_Rq : 42|1@0+ (1,0) [0|1] "SED"  GWM
 SG_ CtaLeftBrkDecel_B_Rq : 7|1@0+ (1,0) [0|1] "SED"  GWM,ABS_ESC
 SG_ CtaLeftBrkEnbl_B_Rq : 31|1@0+ (1,0) [0|1] "SED"  GWM,ABS_ESC
 SG_ Side_Detect_L_Illum : 39|8@0+ (1,0) [0|255] "Percent"  GWM
 SG_ BttLeft_D_Stat : 45|3@0+ (1,0) [0|7] "SED"  GWM
 SG_ BttLeft_D_RqDrv : 47|2@0+ (1,0) [0|3] "SED"  GWM
 SG_ CtaSnsLeft_D_Stat : 25|2@0+ (1,0) [0|3] "SED"  GWM
 SG_ SodDetctLeft_D_Stat : 23|3@0+ (1,0) [0|7] "SED"  GWM
 SG_ CtaLeft_D_Stat : 18|3@0+ (1,0) [0|7] "SED"  GWM
 SG_ CtaAlrtLeft_D_Stat : 8|1@0+ (1,0) [0|1] "SED"  GWM
 SG_ SodLeft_D_Stat : 15|3@0+ (1,0) [0|7] "SED"  GWM
 SG_ SodSnsLeft_D_Stat : 12|2@0+ (1,0) [0|3] "SED"  GWM
 SG_ SodAlrtLeft_D_Stat : 10|2@0+ (1,0) [0|3] "SED"  GWM
 SG_ SodWarnLeft_Prd_Rq : 6|7@0+ (1,0) [0|127] "millisecond"  GWM

BO_ 825 Front_Distance_Req_FD1: 8 GWM
 SG_ WndwFrontHeat_B_Rq : 43|1@0+ (1,0) [0|1] "SED"  GENERIC
 SG_ FdsmTrgRight_B_Actl : 5|1@0+ (1,0) [0|1] "SED"  GENERIC
 SG_ FdsmTrgLeft_B_Actl : 6|1@0+ (1,0) [0|1] "SED"  GENERIC
 SG_ FdsmTrgDist_L_Actl : 1|10@0+ (0.0156,0) [0|15.9588] "meter"  GENERIC
 SG_ FdsmTrgCntr_B_Actl : 7|1@0+ (1,0) [0|1] "SED"  GENERIC
 SG_ LscmbbSrvcRqd_B_Rq : 44|1@0+ (1,0) [0|1] "SED"  GENERIC
 SG_ LscmbbPostEvnt_B_Dsply : 45|1@0+ (1,0) [0|1] "SED"  GENERIC
 SG_ LscmbbEngTqMn_B_Rq : 47|1@0+ (1,0) [0|1] "SED"  SOBDMC_HPCM,ABS_ESC,ECM,ECM_Diesel,ECM_HEVDSL,PCM,PCM_HEV
 SG_ LscmbbMsgTxt_D_Rq : 46|1@0+ (1,0) [0|1] "SED"  GENERIC
 SG_ LscmbbDeny_B_Actl : 24|1@0+ (1,0) [0|1] "SED"  ABS_ESC
 SG_ LscmbbBrkPrchg_D_Rq : 26|2@0+ (1,0) [0|3] "SED"  ABS_ESC
 SG_ LscmbbBrkDecel_No_Cs : 39|8@0+ (1,0) [0|255] "Unitless"  ABS_ESC
 SG_ LscmbbBrkDecel_No_Cnt : 30|4@0+ (1,0) [0|15] "Unitless"  ABS_ESC
 SG_ LscmbbBrkDecel_B_Enbl : 31|1@0+ (1,0) [0|1] "SED"  ABS_ESC
 SG_ LscmbbBrkDecel_A_Rq : 23|8@0+ (0.05,-12.75) [-12.75|0] "m/s^2"  ABS_ESC
 SG_ LscmbbBlck_B_Actl : 2|1@0+ (1,0) [0|1] "SED"  GENERIC
 SG_ LscmbbBaSens_D_Rq : 4|2@0+ (1,0) [0|3] "SED"  ABS_ESC

BO_ 1072 Cluster_Info1_FD1: 8 IPC
 SG_ PtDrvMde_D_Rq : 61|4@0+ (1,0) [0|15] "SED"  ECM,ECM_Diesel,ECM_HEVDSL,PCM,PCM_HEV
 SG_ DrvSlipCtlMde_D_Rq : 33|2@0+ (1,0) [0|3] "SED"  ABS_ESC
 SG_ EngIdlShutDown_B_RqDrv : 3|1@0+ (1,0) [0|1] "SED"  ECM,ECM_Diesel,ECM_HEV,ECM_HEVDSL,PCM,PCM_HEV
 SG_ DrvPerfMde_D_Rq : 49|2@0+ (1,0) [0|3] "SED"  PCM,PCM_HEV,ECM_HEV
 SG_ HsaMde_D_Rq : 54|2@0+ (1,0) [0|3] "SED"  ABS_ESC
 SG_ StopStrtDrvMde_D_RqMnu : 47|2@0+ (1,0) [0|3] "SED"  ECM,ECM_Diesel,ECM_HEVDSL,PCM,PCM_HEV
 SG_ NtrlTowMdeEnbl_B_RqDrv : 1|1@0+ (1,0) [0|1] "SED"  TCM,SOBDMC_HPCM,TCCM,TCM_DSL,PCM_HEV,PCM,ECM_HEV,AWD_DLCM
 SG_ LscmbbStat_B_Actl : 2|1@0+ (1,0) [0|1] "SED"  GENERIC
 SG_ BulbChkActv_B_Stat : 55|1@0+ (1,0) [0|1] "SED"  GENERIC
 SG_ ParkDetect_Stat : 52|1@0+ (1,0) [0|1] "SED"  TCM_DSL,TCM,PCM_HEV,PCM
 SG_ ReducedGuard_D_Rq : 51|2@0+ (1,0) [0|3] "SED"  GENERIC
 SG_ FrostWarn_D_Stat : 45|2@0+ (1,0) [0|3] "SED"  ECM,ECM_Diesel,ECM_HEV,ECM_HEVDSL,PCM,PCM_HEV
 SG_ TrlrBrkMde_D_Rq : 57|1@0+ (1,0) [0|1] "SED"  GENERIC
 SG_ TRLR_SWAY_CONFIG_CMD : 56|1@0+ (1,0) [0|1] "SED"  ABS_ESC
 SG_ TRAILER_BRAKE_CONFIG : 37|1@0+ (1,0) [0|1] "SED"  GENERIC
 SG_ Power_Liftgate_Mode_Cmd : 39|1@0+ (1,0) [0|1] "SED"  GENERIC
 SG_ AccEnbl_B_RqDrv : 35|1@0+ (1,0) [0|1] "SED"  IPMA_ADAS
 SG_ OdometerMasterValue : 15|24@0+ (1,0) [0|16777214] "km"  CMR_DSMC,TCM,SOBDMC_HPCM,ABS_ESC,ECM,ECM_Diesel,ECM_HEV,ECM_HEVDSL,IPMA_ADAS,PCM,PCM_HEV,PSCM,TCM_DSL,VDM,CHCM,TCCM,AWD_DLCM
 SG_ EngOilLife_B_RqReset : 43|1@0+ (1,0) [0|1] "SED"  ECM,ECM_Diesel,ECM_HEV,ECM_HEVDSL,PCM,PCM_HEV
 SG_ MetricActvTe_B_Actl : 38|1@0+ (1,0) [0|1] "SED"  GENERIC
 SG_ AccDeny_B_RqIpc : 7|1@0+ (1,0) [0|1] "SED"  IPMA_ADAS
 SG_ ePRNDL_MODE : 0|1@0+ (1,0) [0|1] "SED"  SOBDMC_HPCM,TCM,ECM,ECM_Diesel,ECM_HEV,ECM_HEVDSL,PCM,PCM_HEV,TCM_DSL
 SG_ PrkLckCtlEnbl_D_RqIpc : 63|2@0+ (1,0) [0|3] "SED"  GENERIC
 SG_ DrvSlipCtlMde_B_Rq2 : 34|1@0+ (1,0) [0|1] "SED"  ABS_ESC
 SG_ MetricActv_B_Actl : 6|1@0+ (1,0) [0|1] "SED"  ECM,ECM_Diesel,ECM_HEV,ECM_HEVDSL,IPMA_ADAS,PCM,PCM_HEV
 SG_ KeyTypeChngMykey_D_Rq : 41|2@0+ (1,0) [0|3] "SED"  GENERIC
 SG_ ManRgen_D_Rq : 5|2@0+ (1,0) [0|3] "SED"  ECM,ECM_Diesel,ECM_HEVDSL
 SG_ Fda_B_Stat : 36|1@0+ (1,0) [0|1] "SED"  GENERIC
 SG_ HaDsplyCpblty_B_Stat : 42|1@0+ (1,0) [0|1] "SED"  IPMA_ADAS

BO_ 909 Body_Info_6_FD1: 8 BCM
 SG_ IgnPsswrdDsply_B_Rq : 57|1@0+ (1,0) [0|1] "SED"  GENERIC
 SG_ ElPwPoint_D_Rq : 59|2@0+ (1,0) [0|3] "SED"  GENERIC
 SG_ PoliceIdlMde_D_Stat : 55|4@0+ (1,0) [0|15] "SED"  GENERIC
 SG_ DrLatchMsgTxt_D_Rq : 43|3@0+ (1,0) [0|7] "SED"  GENERIC
 SG_ WiprFront_D_Stat2 : 63|4@0+ (1,0) [0|15] "SED"  ECM_HEVDSL,PCM,PCM_HEV,ECM,AWD_DLCM
 SG_ SecurityMsgTxt_D_Rq : 47|2@0+ (1,0) [0|3] "SED"  GENERIC
 SG_ PrmtrAlrmEvnt_D_Stat : 35|4@0+ (1,0) [0|15] "SED"  GENERIC
 SG_ TurnLghtSwtch_D_Stat2 : 49|2@0+ (1,0) [0|3] "SED"  PSCM
 SG_ HeadLghtHiPrmsn_D_Stat : 51|2@0+ (1,0) [0|3] "SED"  HCM,IPMA_ADAS
 SG_ SteWhlLckMsgTxt_D_Rq : 25|2@0+ (1,0) [0|3] "SED"  GENERIC
 SG_ immoMsgTxt_D_Rq : 39|4@0+ (1,0) [0|15] "SED"  GENERIC
 SG_ PrsnlDevcChrgEnbl_B_Rq : 40|1@0+ (1,0) [0|1] "SED"  GENERIC
 SG_ TracKeyMde_D_Stat : 45|2@0+ (1,0) [0|3] "SED"  PCM,PCM_HEV
 SG_ PEBackupSlot_Stats : 27|2@0+ (1,0) [0|3] "SED"  GENERIC
 SG_ KeyMykeyTot_No_Cnt : 3|4@0+ (1,0) [0|15] "Counts"  GENERIC
 SG_ Keycode_Status : 15|20@0+ (1,0) [0|1048575] "unitless"  GENERIC
 SG_ KeyAdmnTot_No_Cnt : 7|4@0+ (1,0) [0|15] "Counts"  GENERIC
 SG_ HazrdLght_B_Stat : 56|1@0+ (1,0) [0|1] "SED"  GENERIC

BO_TX_BU_ 877 : PCM_HEV,SOBDMC_HPCM;
BO_TX_BU_ 786 : PCM_HEV,SOBDMC_HPCM;
BO_TX_BU_ 570 : GWM,VDM;
BO_TX_BU_ 1052 : SOBDMC_HPCM,PCM,ECM_HEV,ECM_Diesel,ECM,AWD_DLCM;
BO_TX_BU_ 837 : GWM,VDM;
CM_ SG_ 791 ChargeProfIDPref_Rq "Object:ChargeProfIDPref_St
Status of the charge preference for the current Charge Profile.";
CM_ SG_ 361 TrcmSrvcRqd_B_Rq "Signal not transmitted on vehicles that do not have shift by wire.";
CM_ SG_ 361 TrnGear_I_MeasMax "Signal not transmitted on vehicles that do not have shift by wire.";
CM_ SG_ 361 TrnCapHlth_Actl "Signal not transmitted on vehicles that do not have shift by wire.";
CM_ SG_ 361 TrnPwmFalt_B_Actl "Signal not transmitted on vehicles that do not have shift by wire.";
CM_ SG_ 361 TrnActFalt_B_Actl "Signal not transmitted on vehicles that do not have shift by wire.";
CM_ BO_ 1009 "APIM Tx";
CM_ SG_ 1009 CenterStackRing_D_Actl "The Center Stack sends the CPLR a signal to turn On or Off the light Ring, This is a customer selectable preference switch";
CM_ SG_ 1009 APIM_NumberofTracks_St "Object NumberofTracks";
CM_ SG_ 1009 APIM_ActiveTrackNum_St "Object.ActiveTrackNum";
CM_ SG_ 360 GsmSrvcRqd_B_Rq "Signal not transmitted on vehicles that do not have shift by wire.";
CM_ SG_ 360 TrnTrcmPwmSig_D_Actl "Signal not transmitted on vehicles that do not have shift by wire.";
CM_ SG_ 360 TrnGearPwmFalt_B_Actl "Signal not transmitted on vehicles that do not have shift by wire.";
CM_ SG_ 360 GearButtnStuck_B_Actl "Signal not transmitted on vehicles that do not have shift by wire.";
CM_ SG_ 93 TrnTrcmNtmState_D_Actl "Signal not transmitted on vehicles that do not have shift by wire.";
CM_ SG_ 93 TrnSns2Pos_Pc_Actl "Signal not transmitted on vehicles that do not have shift by wire.";
CM_ SG_ 93 TrnSns1Pos_Pc_Actl "Signal not transmitted on vehicles that do not have shift by wire.";
CM_ SG_ 93 TrnSecPrkStat_D_Actl "Signal not transmitted on vehicles that do not have shift by wire.";
CM_ SG_ 93 TrnNtrlTowCnfm_B_Actl "Signal not transmitted on vehicles that do not have shift by wire.";
CM_ SG_ 93 TrnGearFinalPos_B_Actl "Signal not transmitted on vehicles that do not have shift by wire.";
CM_ SG_ 93 TrnGearCnfm_No_Cs "Signal not transmitted on vehicles that do not have shift by wire.";
CM_ SG_ 93 TrnGearCnfm_No_Cnt "Signal not transmitted on vehicles that do not have shift by wire.";
CM_ SG_ 93 TrnGear_D_Actl "Signal not transmitted on vehicles that do not have shift by wire.";
CM_ SG_ 90 TrnGsmNtmState_D_Actl "Signal not transmitted on vehicles that do not have shift by wire.";
CM_ SG_ 90 DrQltyDrv_D_StatGsm "Signal not transmitted on vehicles that do not have shift by wire.";
CM_ SG_ 90 TrnBtsiOvrrd_B_Stat "Signal not transmitted on vehicles that do not have shift by wire.";
CM_ SG_ 90 TrnValidGearRq_D_Stat "Signal not transmitted on vehicles that do not have shift by wire.";
CM_ SG_ 90 TrnGearRqCnt_B_Actl "Signal not transmitted on vehicles that do not have shift by wire.";
CM_ SG_ 90 TrnGearButtn_U_Actl "Signal not transmitted on vehicles that do not have shift by wire.";
CM_ SG_ 90 TrnGearButtn_B_ActlR2 "Signal not transmitted on vehicles that do not have shift by wire.";
CM_ SG_ 90 TrnGearButtn_B_ActlR1 "Signal not transmitted on vehicles that do not have shift by wire.";
CM_ SG_ 90 TrnGearButtn_B_ActlR0 "Signal not transmitted on vehicles that do not have shift by wire.";
CM_ SG_ 90 TrnGearButtn_B_ActlP2 "Signal not transmitted on vehicles that do not have shift by wire.";
CM_ SG_ 90 TrnGearButtn_B_ActlP1 "Signal not transmitted on vehicles that do not have shift by wire.";
CM_ SG_ 90 TrnGearButtn_B_ActlP0 "Signal not transmitted on vehicles that do not have shift by wire.";
CM_ SG_ 90 TrnGearButtn_B_ActlN2 "Signal not transmitted on vehicles that do not have shift by wire.";
CM_ SG_ 90 TrnGearButtn_B_ActlN1 "Signal not transmitted on vehicles that do not have shift by wire.";
CM_ SG_ 90 TrnGearButtn_B_ActlN0 "Signal not transmitted on vehicles that do not have shift by wire.";
CM_ SG_ 90 TrnGearButtn_B_ActlM2 "Signal not transmitted on vehicles that do not have shift by wire.";
CM_ SG_ 90 TrnGearButtn_B_ActlM1 "Signal not transmitted on vehicles that do not have shift by wire.";
CM_ SG_ 90 TrnGearButtn_B_ActlM0 "Signal not transmitted on vehicles that do not have shift by wire.";
CM_ SG_ 90 TrnGearButtn_B_ActlD2 "Signal not transmitted on vehicles that do not have shift by wire.";
CM_ SG_ 90 TrnGearButtn_B_ActlD1 "Signal not transmitted on vehicles that do not have shift by wire.";
CM_ SG_ 90 TrnGearButtn_B_ActlD0 "Signal not transmitted on vehicles that do not have shift by wire.";
CM_ SG_ 90 TrnGear_No_Cs "Signal not transmitted on vehicles that do not have shift by wire.";
CM_ SG_ 90 TrnGear_No_Cnt "Signal not transmitted on vehicles that do not have shift by wire.";
CM_ SG_ 90 TrnGear_D_RqDrv "Signal not transmitted on vehicles that do not have shift by wire.";
CM_ SG_ 90 BrkSwtchPos_B_ActlGsm "Signal not transmitted on vehicles that do not have shift by wire.";
CM_ BO_ 1111 " new RCM Serial Trailer Aid (TrailerAid_Stat1) 48 bits";
CM_ BO_ 1106 " new RCM Serial Trailer Aid (TrailerAid_Stat1) 48 bits";
CM_ SG_ 1091 PoliceAux4Lamp_B_Rq2 "Signal not transmitted on programs that do not have AWD.";
CM_ SG_ 1091 PoliceAux3Lamp_B_Rq2 "Signal not transmitted on programs that do not have AWD.";
CM_ SG_ 1091 PoliceAux2Lamp_B_Rq2 "Signal not transmitted on programs that do not have AWD.";
CM_ SG_ 1091 PoliceAux1Lamp_B_Rq2 "Signal not transmitted on programs that do not have AWD.";
CM_ SG_ 138 SteWhlRelCalib_An_Sns "Signal is not transmitted on vehicles where PSCM is transmitting the message that contains this signal.
Signal data set to 0x0 for ABS only vehicle option content";
CM_ BO_ 1078 "not supported by DCDC variants";
CM_ SG_ 1093 StopLamp_B_RqTrlrBrk "Signal not transmitted on all variants.";
CM_ SG_ 792 ElTrip_L_Dsply "Key cycle trip distance driven with the engine off (Trip EV Miles)";
CM_ SG_ 792 ElLongTerm_L_Dsply "Long term distance distance driven with the engine off since the last long term reset (Long Term EV Miles).";
CM_ SG_ 968 IpcLvl_B_Type "specifically set to NoSigSendType, MSGDCR-006764, signal should not be changing value.";
CM_ SG_ 765 Mc_VehUntTrpCoUsrSel_St "Object.VehicleSettings.Disp_Miles_Kilometers.Rq";
CM_ SG_ 765 Mc_VehUnitTempUsrSel_St "Object.VehicleSettings.Disp_Temperature.Rq";
CM_ SG_ 765 Mc_VehDayNightUsrSel_St "Object.BodyInterface.Settings.VehicleDayNightUserSelection
Object.BodyInterface.Status.AMDayNightSensitivity";
CM_ SG_ 765 Mc_VehTimeFrmtUsrSel_St "Object.BodyInterface.Settings.VehicleTimeFormatUserSelection";
CM_ SG_ 765 Mc_VehThemeUsrSel_St "Object.BodyInterface.Settings.VehicleThemeUserSelection";
CM_ SG_ 765 Mc_VehLangUsrSel_St "Object.BodyInterface.Settings.VehicleLanguageUserSelection
Object Vehicle Settings.Disp_LangSel
";
CM_ BO_ 559 "APIM Tx";
CM_ BO_ 558 "APIM Tx";
CM_ SG_ 1072 MetricActv_B_Actl "0 =Inactive(English), 1=Active(Metric)";
BA_DEF_ BO_  "VFrameFormat" ENUM  "StandardCAN","ExtendedCAN","reserved","reserved","reserved","reserved","reserved","reserved","reserved","reserved","reserved","reserved","reserved","reserved","StandardCAN_FD","ExtendedCAN_FD";
BA_DEF_ SG_  "GenSigSendType" ENUM  "Cyclic","OnWrite","vector_leerstring","OnChange","vector_leerstring","IfActive","vector_leerstring","NoSigSendType";
BA_DEF_ SG_  "GenSigInactiveValue" INT 0 100000;
BA_DEF_ SG_  "WakeupSignal" ENUM  "No","Yes";
BA_DEF_ SG_  "UsedOnPgmDBC" ENUM  "No","Yes";
BA_DEF_ SG_  "GenSigStartValueInteger" INT 0 1000000000;
BA_DEF_ SG_  "ContentDependant" ENUM  "No","Yes";
BA_DEF_ SG_  "MetaData" ENUM  "No","Yes";
BA_DEF_ SG_  "GenSigStartValue" HEX 0 268435455;
BA_DEF_ SG_  "U_CX727_MY2021_Rx" ENUM  "No","Yes";
BA_DEF_ SG_  "U_P702_MY2021_Rx" ENUM  "No","Yes";
BA_DEF_ SG_  "U_T6_MCA_MY2020_Rx" ENUM  "No","Yes";
BA_DEF_ SG_  "ECGUsedRxSignal" ENUM  "No","Yes";
BA_DEF_ SG_  "U_CD542_MY2021_Rx" ENUM  "No","Yes";
BA_DEF_ SG_  "U_U55X_MY2022_Rx" ENUM  "No","Yes";
BA_DEF_ SG_  "U_CD764_MY2022_Rx" ENUM  "No","Yes";
BA_DEF_ SG_  "U_CDX706_MY2023_Rx" ENUM  "No","Yes";
BA_DEF_ SG_  "U_CX727_MY2021_Tx" ENUM  "No","Yes";
BA_DEF_ SG_  "U_P702_MY2021_Tx" ENUM  "No","Yes";
BA_DEF_ SG_  "U_T6_MCA_MY2020_Tx" ENUM  "No","Yes";
BA_DEF_ SG_  "ECGUsedTxSignal" ENUM  "No","Yes";
BA_DEF_ SG_  "U_CD542_MY2021_Tx" ENUM  "No","Yes";
BA_DEF_ SG_  "U_U55X_MY2022_Tx" ENUM  "No","Yes";
BA_DEF_ SG_  "U_CD764_MY2022_Tx" ENUM  "No","Yes";
BA_DEF_ SG_  "U_CDX706_MY2023_Tx" ENUM  "No","Yes";
BA_DEF_ BO_  "GenMsgILSupport" ENUM  "No","Yes";
BA_DEF_ BO_  "DiagResponse" ENUM  "No","Yes";
BA_DEF_ BO_  "DiagRequest" ENUM  "No","Yes";
BA_DEF_ BO_  "TpTxIndex" INT 0 536870911;
BA_DEF_ BO_  "DiagState" ENUM  "No","Yes";
BA_DEF_ BO_  "TpApplType" STRING ;
BA_DEF_ BO_  "NmAsrMessage" ENUM  "No","Yes";
BA_DEF_ BO_  "ProgBWConditional" STRING ;
BA_DEF_ BO_  "SCP_AuthInfoTxLength" INT 0 512;
BA_DEF_ BO_  "SCP_FreshnessValueTxLength" INT 0 512;
BA_DEF_ BO_  "SCP_FreshnessValueLength" INT 0 512;
BA_DEF_ BO_  "OvtpPushApplication" ENUM  "FALSE","TRUE";
BA_DEF_ BO_  "GenMsgSendType" ENUM  "FixedPeriodic","Event","EnabledPeriodic","NotUsed","NotUsed","EventPeriodic","NotUsed","NotUsed","NoMsgSendType";
BA_DEF_ BO_  "GenMsgCycleTime" INT 0 100000;
BA_DEF_ BO_  "GenMsgDelayTime" INT 0 1000;
BA_DEF_ BO_  "GenMsgNrOfRepetition" INT 0 100;
BA_DEF_ BO_  "GenMsgStartDelayTime" INT 0 10000;
BA_DEF_ BO_  "EventRateOfChange" INT 10 10000;
BA_DEF_ BO_  "FrameGatewayId" HEX 0 1407;
BA_DEF_ BO_  "NetworkInitialization" ENUM  "No","Yes";
BA_DEF_ BO_  "FrameGatewayNetwork" STRING ;
BA_DEF_ BO_  "FrameRouting" STRING ;
BA_DEF_DEF_  "VFrameFormat" "ExtendedCAN_FD";
BA_DEF_DEF_  "GenSigSendType" "NoSigSendType";
BA_DEF_DEF_  "GenSigInactiveValue" 0;
BA_DEF_DEF_  "WakeupSignal" "No";
BA_DEF_DEF_  "UsedOnPgmDBC" "Yes";
BA_DEF_DEF_  "GenSigStartValueInteger" 0;
BA_DEF_DEF_  "ContentDependant" "No";
BA_DEF_DEF_  "MetaData" "No";
BA_DEF_DEF_  "GenSigStartValue" 0;
BA_DEF_DEF_  "U_CX727_MY2021_Rx" "No";
BA_DEF_DEF_  "U_P702_MY2021_Rx" "No";
BA_DEF_DEF_  "U_T6_MCA_MY2020_Rx" "No";
BA_DEF_DEF_  "ECGUsedRxSignal" "No";
BA_DEF_DEF_  "U_CD542_MY2021_Rx" "No";
BA_DEF_DEF_  "U_U55X_MY2022_Rx" "No";
BA_DEF_DEF_  "U_CD764_MY2022_Rx" "No";
BA_DEF_DEF_  "U_CDX706_MY2023_Rx" "No";
BA_DEF_DEF_  "U_CX727_MY2021_Tx" "No";
BA_DEF_DEF_  "U_P702_MY2021_Tx" "No";
BA_DEF_DEF_  "U_T6_MCA_MY2020_Tx" "No";
BA_DEF_DEF_  "ECGUsedTxSignal" "No";
BA_DEF_DEF_  "U_CD542_MY2021_Tx" "No";
BA_DEF_DEF_  "U_U55X_MY2022_Tx" "No";
BA_DEF_DEF_  "U_CD764_MY2022_Tx" "No";
BA_DEF_DEF_  "U_CDX706_MY2023_Tx" "No";
BA_DEF_DEF_  "GenMsgILSupport" "Yes";
BA_DEF_DEF_  "DiagResponse" "No";
BA_DEF_DEF_  "DiagRequest" "No";
BA_DEF_DEF_  "TpTxIndex" 0;
BA_DEF_DEF_  "DiagState" "No";
BA_DEF_DEF_  "TpApplType" "";
BA_DEF_DEF_  "NmAsrMessage" "No";
BA_DEF_DEF_  "ProgBWConditional" "NONE";
BA_DEF_DEF_  "SCP_AuthInfoTxLength" 53;
BA_DEF_DEF_  "SCP_FreshnessValueTxLength" 11;
BA_DEF_DEF_  "SCP_FreshnessValueLength" 64;
BA_DEF_DEF_  "OvtpPushApplication" "FALSE";
BA_DEF_DEF_  "GenMsgSendType" "NoMsgSendType";
BA_DEF_DEF_  "GenMsgCycleTime" 0;
BA_DEF_DEF_  "GenMsgDelayTime" 20;
BA_DEF_DEF_  "GenMsgNrOfRepetition" 1;
BA_DEF_DEF_  "GenMsgStartDelayTime" 0;
BA_DEF_DEF_  "EventRateOfChange" 10000;
BA_DEF_DEF_  "FrameGatewayId" 0;
BA_DEF_DEF_  "NetworkInitialization" "Yes";
BA_DEF_DEF_  "FrameGatewayNetwork" "NONE";
BA_DEF_DEF_  "FrameRouting" "";
BA_ "GenMsgSendType" BO_ 791 5;
BA_ "GenMsgCycleTime" BO_ 791 1000;
BA_ "GenMsgSendType" BO_ 748 0;
BA_ "GenMsgCycleTime" BO_ 748 100;
BA_ "GenMsgSendType" BO_ 740 0;
BA_ "GenMsgCycleTime" BO_ 740 100;
BA_ "GenMsgSendType" BO_ 589 0;
BA_ "GenMsgCycleTime" BO_ 589 100;
BA_ "GenMsgSendType" BO_ 588 0;
BA_ "GenMsgCycleTime" BO_ 588 100;
BA_ "GenMsgSendType" BO_ 587 0;
BA_ "GenMsgCycleTime" BO_ 587 100;
BA_ "GenMsgSendType" BO_ 361 0;
BA_ "GenMsgCycleTime" BO_ 361 1000;
BA_ "GenMsgSendType" BO_ 1009 5;
BA_ "GenMsgCycleTime" BO_ 1009 1000;
BA_ "GenMsgSendType" BO_ 360 0;
BA_ "GenMsgCycleTime" BO_ 360 1000;
BA_ "GenMsgSendType" BO_ 140 5;
BA_ "GenMsgCycleTime" BO_ 140 1000;
BA_ "GenMsgSendType" BO_ 122 0;
BA_ "GenMsgCycleTime" BO_ 122 10;
BA_ "GenMsgSendType" BO_ 93 5;
BA_ "GenMsgCycleTime" BO_ 93 100;
BA_ "GenMsgSendType" BO_ 90 5;
BA_ "GenMsgCycleTime" BO_ 90 100;
BA_ "GenMsgSendType" BO_ 1114 5;
BA_ "GenMsgCycleTime" BO_ 1114 1000;
BA_ "GenMsgSendType" BO_ 1111 0;
BA_ "GenMsgCycleTime" BO_ 1111 50;
BA_ "GenMsgSendType" BO_ 1106 5;
BA_ "GenMsgCycleTime" BO_ 1106 1000;
BA_ "GenMsgSendType" BO_ 1091 5;
BA_ "GenMsgCycleTime" BO_ 1091 1000;
BA_ "GenMsgSendType" BO_ 131 5;
BA_ "GenMsgCycleTime" BO_ 131 100;
BA_ "GenMsgSendType" BO_ 953 5;
BA_ "GenMsgCycleTime" BO_ 953 1000;
BA_ "GenMsgSendType" BO_ 1099 5;
BA_ "GenMsgCycleTime" BO_ 1099 1000;
BA_ "GenMsgSendType" BO_ 1093 0;
BA_ "GenMsgCycleTime" BO_ 1093 100;
BA_ "GenMsgSendType" BO_ 792 0;
BA_ "GenMsgCycleTime" BO_ 792 100;
BA_ "GenMsgSendType" BO_ 968 5;
BA_ "GenMsgCycleTime" BO_ 968 1000;
BA_ "GenMsgSendType" BO_ 819 5;
BA_ "GenMsgCycleTime" BO_ 819 100;
BA_ "GenMsgSendType" BO_ 818 5;
BA_ "GenMsgCycleTime" BO_ 818 100;
BA_ "GenMsgSendType" BO_ 806 0;
BA_ "GenMsgCycleTime" BO_ 806 100;
BA_ "GenMsgSendType" BO_ 765 5;
BA_ "GenMsgCycleTime" BO_ 765 1000;
BA_ "GenMsgSendType" BO_ 518 0;
BA_ "GenMsgCycleTime" BO_ 518 50;
BA_ "GenMsgSendType" BO_ 559 1;
BA_ "GenMsgSendType" BO_ 558 1;
BA_ "GenMsgSendType" BO_ 1072 5;
BA_ "GenMsgCycleTime" BO_ 1072 100;
BA_ "GenMsgSendType" BO_ 909 5;
BA_ "GenMsgCycleTime" BO_ 909 1000;
BA_ "GenMsgSendType" BO_ 936 0;
BA_ "GenMsgCycleTime" BO_ 936 20;
BA_ "GenMsgDelayTime" BO_ 936 10;
BA_ "FrameRouting" BO_ 936 "FD1_CAN,0x3A8;HS2_CAN,0x3A8";
BA_ "VFrameFormat" BO_ 936 14;
BA_ "GenMsgSendType" BO_ 877 5;
BA_ "GenMsgCycleTime" BO_ 877 1000;
BA_ "VFrameFormat" BO_ 877 14;
BA_ "FrameGatewayId" BO_ 791 791;
BA_ "FrameGatewayNetwork" BO_ 791 "HS3_CAN";
BA_ "FrameRouting" BO_ 791 "HS3_CAN,0x317;";
BA_ "VFrameFormat" BO_ 791 14;
BA_ "GenMsgSendType" BO_ 786 0;
BA_ "GenMsgCycleTime" BO_ 786 100;
BA_ "VFrameFormat" BO_ 786 14;
BA_ "FrameGatewayId" BO_ 748 748;
BA_ "FrameGatewayNetwork" BO_ 748 "HS1_CAN";
BA_ "FrameRouting" BO_ 748 "HS1_CAN,0x2EC;";
BA_ "VFrameFormat" BO_ 748 14;
BA_ "FrameGatewayId" BO_ 740 740;
BA_ "FrameGatewayNetwork" BO_ 740 "HS1_CAN";
BA_ "FrameRouting" BO_ 740 "HS1_CAN,0x2E4;";
BA_ "VFrameFormat" BO_ 740 14;
BA_ "GenMsgSendType" BO_ 604 0;
BA_ "GenMsgCycleTime" BO_ 604 10;
BA_ "GenMsgDelayTime" BO_ 604 0;
BA_ "VFrameFormat" BO_ 604 14;
BA_ "FrameGatewayId" BO_ 589 589;
BA_ "FrameGatewayNetwork" BO_ 589 "HS1_CAN";
BA_ "FrameRouting" BO_ 589 "HS1_CAN,0x24D;";
BA_ "VFrameFormat" BO_ 589 14;
BA_ "FrameGatewayId" BO_ 588 588;
BA_ "FrameGatewayNetwork" BO_ 588 "HS1_CAN";
BA_ "FrameRouting" BO_ 588 "HS1_CAN,0x24C;";
BA_ "VFrameFormat" BO_ 588 14;
BA_ "FrameGatewayId" BO_ 587 587;
BA_ "FrameGatewayNetwork" BO_ 587 "HS1_CAN";
BA_ "FrameRouting" BO_ 587 "HS1_CAN,0x24B;";
BA_ "VFrameFormat" BO_ 587 14;
BA_ "GenMsgSendType" BO_ 389 0;
BA_ "GenMsgCycleTime" BO_ 389 100;
BA_ "VFrameFormat" BO_ 389 14;
BA_ "FrameGatewayId" BO_ 361 361;
BA_ "FrameGatewayNetwork" BO_ 361 "HS2_CAN";
BA_ "FrameRouting" BO_ 361 "HS2_CAN,0x169;";
BA_ "VFrameFormat" BO_ 361 14;
BA_ "FrameGatewayId" BO_ 1009 1009;
BA_ "FrameGatewayNetwork" BO_ 1009 "HS3_CAN";
BA_ "FrameRouting" BO_ 1009 "HS3_CAN,0x3F1;";
BA_ "VFrameFormat" BO_ 1009 14;
BA_ "FrameGatewayId" BO_ 360 360;
BA_ "FrameGatewayNetwork" BO_ 360 "HS2_CAN";
BA_ "FrameRouting" BO_ 360 "HS2_CAN,0x168;";
BA_ "VFrameFormat" BO_ 360 14;
BA_ "GenMsgSendType" BO_ 331 0;
BA_ "GenMsgCycleTime" BO_ 331 10;
BA_ "GenMsgDelayTime" BO_ 331 0;
BA_ "VFrameFormat" BO_ 331 14;
BA_ "FrameGatewayId" BO_ 140 140;
BA_ "FrameGatewayNetwork" BO_ 140 "HS3_CAN";
BA_ "FrameRouting" BO_ 140 "HS3_CAN,0x8C;";
BA_ "VFrameFormat" BO_ 140 14;
BA_ "FrameGatewayId" BO_ 122 122;
BA_ "FrameGatewayNetwork" BO_ 122 "HS1_CAN";
BA_ "FrameRouting" BO_ 122 "HS1_CAN,0x7A;";
BA_ "VFrameFormat" BO_ 122 14;
BA_ "FrameGatewayId" BO_ 93 93;
BA_ "FrameGatewayNetwork" BO_ 93 "HS2_CAN";
BA_ "FrameRouting" BO_ 93 "HS2_CAN,0x5D;";
BA_ "VFrameFormat" BO_ 93 14;
BA_ "FrameGatewayId" BO_ 90 90;
BA_ "FrameGatewayNetwork" BO_ 90 "HS2_CAN";
BA_ "FrameRouting" BO_ 90 "HS2_CAN,0x5A;";
BA_ "VFrameFormat" BO_ 90 14;
BA_ "FrameGatewayId" BO_ 1114 1114;
BA_ "FrameGatewayNetwork" BO_ 1114 "HS3_CAN";
BA_ "FrameRouting" BO_ 1114 "HS3_CAN,0x45A;";
BA_ "VFrameFormat" BO_ 1114 14;
BA_ "FrameGatewayId" BO_ 1111 1111;
BA_ "FrameGatewayNetwork" BO_ 1111 "HS2_CAN";
BA_ "FrameRouting" BO_ 1111 "HS2_CAN,0x457;";
BA_ "VFrameFormat" BO_ 1111 14;
BA_ "FrameGatewayId" BO_ 1106 1106;
BA_ "FrameGatewayNetwork" BO_ 1106 "HS2_CAN";
BA_ "FrameRouting" BO_ 1106 "HS2_CAN,0x452;";
BA_ "VFrameFormat" BO_ 1106 14;
BA_ "FrameRouting" BO_ 1091 "HS3_CAN,0x443;MS1_CAN,0x443";
BA_ "VFrameFormat" BO_ 1091 14;
BA_ "FrameGatewayId" BO_ 138 138;
BA_ "FrameGatewayNetwork" BO_ 138 "HS2_CAN";
BA_ "FrameRouting" BO_ 138 "HS2_CAN,0x8A;";
BA_ "VFrameFormat" BO_ 138 14;
BA_ "FrameGatewayId" BO_ 131 131;
BA_ "FrameGatewayNetwork" BO_ 131 "HS2_CAN";
BA_ "FrameRouting" BO_ 131 "HS2_CAN,0x83;";
BA_ "VFrameFormat" BO_ 131 14;
BA_ "FrameRouting" BO_ 787 "MS1_CAN,0x313;MS2_CAN,0x313";
BA_ "VFrameFormat" BO_ 787 14;
BA_ "GenMsgSendType" BO_ 570 0;
BA_ "GenMsgCycleTime" BO_ 570 20;
BA_ "GenMsgDelayTime" BO_ 570 10;
BA_ "VFrameFormat" BO_ 570 14;
BA_ "FrameGatewayId" BO_ 953 953;
BA_ "FrameGatewayNetwork" BO_ 953 "HS1_CAN";
BA_ "FrameRouting" BO_ 953 "HS1_CAN,0x3B9;";
BA_ "VFrameFormat" BO_ 953 14;
BA_ "GenMsgSendType" BO_ 1101 5;
BA_ "GenMsgCycleTime" BO_ 1101 1000;
BA_ "VFrameFormat" BO_ 1101 14;
BA_ "FrameGatewayId" BO_ 1099 1099;
BA_ "FrameGatewayNetwork" BO_ 1099 "HS1_CAN";
BA_ "FrameRouting" BO_ 1099 "HS1_CAN,0x44B;";
BA_ "VFrameFormat" BO_ 1099 14;
BA_ "FrameGatewayId" BO_ 1078 1078;
BA_ "FrameGatewayNetwork" BO_ 1078 "HS1_CAN";
BA_ "FrameRouting" BO_ 1078 "HS1_CAN,0x436;";
BA_ "VFrameFormat" BO_ 1078 14;
BA_ "GenMsgSendType" BO_ 1052 0;
BA_ "GenMsgCycleTime" BO_ 1052 50;
BA_ "VFrameFormat" BO_ 1052 14;
BA_ "FrameGatewayId" BO_ 1093 1093;
BA_ "FrameGatewayNetwork" BO_ 1093 "HS3_CAN";
BA_ "FrameRouting" BO_ 1093 "HS3_CAN,0x445;";
BA_ "VFrameFormat" BO_ 1093 14;
BA_ "GenMsgSendType" BO_ 837 5;
BA_ "GenMsgCycleTime" BO_ 837 100;
BA_ "VFrameFormat" BO_ 837 14;
BA_ "FrameGatewayId" BO_ 792 792;
BA_ "FrameGatewayNetwork" BO_ 792 "HS3_CAN";
BA_ "FrameRouting" BO_ 792 "HS3_CAN,0x318;";
BA_ "VFrameFormat" BO_ 792 14;
BA_ "FrameGatewayId" BO_ 968 968;
BA_ "FrameGatewayNetwork" BO_ 968 "HS3_CAN";
BA_ "FrameRouting" BO_ 968 "HS3_CAN,0x3C8;";
BA_ "VFrameFormat" BO_ 968 14;
BA_ "FrameGatewayId" BO_ 819 819;
BA_ "FrameGatewayNetwork" BO_ 819 "MS1_CAN";
BA_ "FrameRouting" BO_ 819 "MS1_CAN,0x333;";
BA_ "VFrameFormat" BO_ 819 14;
BA_ "FrameGatewayId" BO_ 818 818;
BA_ "FrameGatewayNetwork" BO_ 818 "MS1_CAN";
BA_ "FrameRouting" BO_ 818 "MS1_CAN,0x332;";
BA_ "VFrameFormat" BO_ 818 14;
BA_ "FrameGatewayId" BO_ 806 806;
BA_ "FrameGatewayNetwork" BO_ 806 "MS1_CAN";
BA_ "FrameRouting" BO_ 806 "MS1_CAN,0x326;";
BA_ "VFrameFormat" BO_ 806 14;
BA_ "FrameGatewayId" BO_ 765 765;
BA_ "FrameGatewayNetwork" BO_ 765 "HS3_CAN";
BA_ "FrameRouting" BO_ 765 "HS3_CAN,0x2FD;";
BA_ "VFrameFormat" BO_ 765 14;
BA_ "FrameGatewayId" BO_ 518 518;
BA_ "FrameGatewayNetwork" BO_ 518 "HS1_CAN";
BA_ "FrameRouting" BO_ 518 "HS1_CAN,0x206;";
BA_ "VFrameFormat" BO_ 518 14;
BA_ "FrameGatewayId" BO_ 559 559;
BA_ "FrameGatewayNetwork" BO_ 559 "HS3_CAN";
BA_ "FrameRouting" BO_ 559 "HS3_CAN,0x22F;";
BA_ "VFrameFormat" BO_ 559 14;
BA_ "FrameGatewayId" BO_ 558 558;
BA_ "FrameGatewayNetwork" BO_ 558 "HS3_CAN";
BA_ "FrameRouting" BO_ 558 "HS3_CAN,0x22E;";
BA_ "VFrameFormat" BO_ 558 14;
BA_ "GenMsgSendType" BO_ 934 5;
BA_ "GenMsgCycleTime" BO_ 934 200;
BA_ "FrameRouting" BO_ 934 "FD1_CAN,0x3A6;MS1_CAN,0x3A6";
BA_ "VFrameFormat" BO_ 934 14;
BA_ "FrameGatewayId" BO_ 825 825;
BA_ "FrameGatewayNetwork" BO_ 825 "HS2_CAN";
BA_ "FrameRouting" BO_ 825 "HS2_CAN,0x339;";
BA_ "VFrameFormat" BO_ 825 14;
BA_ "FrameGatewayId" BO_ 1072 1072;
BA_ "FrameGatewayNetwork" BO_ 1072 "HS3_CAN";
BA_ "FrameRouting" BO_ 1072 "HS3_CAN,0x430;";
BA_ "VFrameFormat" BO_ 1072 14;
BA_ "FrameGatewayId" BO_ 909 909;
BA_ "FrameGatewayNetwork" BO_ 909 "HS1_CAN";
BA_ "FrameRouting" BO_ 909 "HS1_CAN,0x38D;";
BA_ "VFrameFormat" BO_ 909 14;
BA_ "U_CX727_MY2021_Rx" SG_ 936 ApaSys_D_Stat 1;
BA_ "U_P702_MY2021_Rx" SG_ 936 ApaSys_D_Stat 1;
BA_ "U_T6_MCA_MY2020_Rx" SG_ 936 ApaSys_D_Stat 1;
BA_ "U_CD542_MY2021_Rx" SG_ 936 ApaSys_D_Stat 1;
BA_ "U_U55X_MY2022_Rx" SG_ 936 ApaSys_D_Stat 1;
BA_ "U_CD764_MY2022_Rx" SG_ 936 ApaSys_D_Stat 1;
BA_ "U_CDX706_MY2023_Rx" SG_ 936 ApaSys_D_Stat 1;
BA_ "U_T6_MCA_MY2020_Tx" SG_ 936 ApaSys_D_Stat 1;
BA_ "U_CD542_MY2021_Tx" SG_ 936 ApaSys_D_Stat 1;
BA_ "U_U55X_MY2022_Tx" SG_ 936 ApaSys_D_Stat 1;
BA_ "U_CD764_MY2022_Tx" SG_ 936 ApaSys_D_Stat 1;
BA_ "U_CDX706_MY2023_Tx" SG_ 936 ApaSys_D_Stat 1;
BA_ "U_T6_MCA_MY2020_Tx" SG_ 936 ApaSteWhl_D_RqDrv 1;
BA_ "U_CD542_MY2021_Tx" SG_ 936 ApaSteWhl_D_RqDrv 1;
BA_ "U_U55X_MY2022_Tx" SG_ 936 ApaSteWhl_D_RqDrv 1;
BA_ "U_CD764_MY2022_Tx" SG_ 936 ApaSteWhl_D_RqDrv 1;
BA_ "U_CDX706_MY2023_Tx" SG_ 936 ApaSteWhl_D_RqDrv 1;
BA_ "U_T6_MCA_MY2020_Tx" SG_ 936 ApaSteScanMde_D_Stat 1;
BA_ "U_CD542_MY2021_Tx" SG_ 936 ApaSteScanMde_D_Stat 1;
BA_ "U_U55X_MY2022_Tx" SG_ 936 ApaSteScanMde_D_Stat 1;
BA_ "U_CD764_MY2022_Tx" SG_ 936 ApaSteScanMde_D_Stat 1;
BA_ "U_CDX706_MY2023_Tx" SG_ 936 ApaSteScanMde_D_Stat 1;
BA_ "U_T6_MCA_MY2020_Tx" SG_ 936 ApaSelSapp_D_Stat 1;
BA_ "U_CD542_MY2021_Tx" SG_ 936 ApaSelSapp_D_Stat 1;
BA_ "U_U55X_MY2022_Tx" SG_ 936 ApaSelSapp_D_Stat 1;
BA_ "U_CD764_MY2022_Tx" SG_ 936 ApaSelSapp_D_Stat 1;
BA_ "U_CDX706_MY2023_Tx" SG_ 936 ApaSelSapp_D_Stat 1;
BA_ "U_T6_MCA_MY2020_Tx" SG_ 936 ApaSelPpa_D_Stat 1;
BA_ "U_CD542_MY2021_Tx" SG_ 936 ApaSelPpa_D_Stat 1;
BA_ "U_U55X_MY2022_Tx" SG_ 936 ApaSelPpa_D_Stat 1;
BA_ "U_CD764_MY2022_Tx" SG_ 936 ApaSelPpa_D_Stat 1;
BA_ "U_CDX706_MY2023_Tx" SG_ 936 ApaSelPpa_D_Stat 1;
BA_ "U_T6_MCA_MY2020_Tx" SG_ 936 ApaSelPoa_D_Stat 1;
BA_ "U_CD542_MY2021_Tx" SG_ 936 ApaSelPoa_D_Stat 1;
BA_ "U_U55X_MY2022_Tx" SG_ 936 ApaSelPoa_D_Stat 1;
BA_ "U_CD764_MY2022_Tx" SG_ 936 ApaSelPoa_D_Stat 1;
BA_ "U_CDX706_MY2023_Tx" SG_ 936 ApaSelPoa_D_Stat 1;
BA_ "U_T6_MCA_MY2020_Tx" SG_ 936 ApaScan_D_Stat 1;
BA_ "U_CD542_MY2021_Tx" SG_ 936 ApaScan_D_Stat 1;
BA_ "U_U55X_MY2022_Tx" SG_ 936 ApaScan_D_Stat 1;
BA_ "U_CD764_MY2022_Tx" SG_ 936 ApaScan_D_Stat 1;
BA_ "U_CDX706_MY2023_Tx" SG_ 936 ApaScan_D_Stat 1;
BA_ "U_T6_MCA_MY2020_Tx" SG_ 936 ApaLongCtl_D_RqDrv 1;
BA_ "U_CD542_MY2021_Tx" SG_ 936 ApaLongCtl_D_RqDrv 1;
BA_ "U_U55X_MY2022_Tx" SG_ 936 ApaLongCtl_D_RqDrv 1;
BA_ "U_CD764_MY2022_Tx" SG_ 936 ApaLongCtl_D_RqDrv 1;
BA_ "U_CDX706_MY2023_Tx" SG_ 936 ApaLongCtl_D_RqDrv 1;
BA_ "U_T6_MCA_MY2020_Tx" SG_ 936 ApaGearShif_D_RqDrv 1;
BA_ "U_CD542_MY2021_Tx" SG_ 936 ApaGearShif_D_RqDrv 1;
BA_ "U_U55X_MY2022_Tx" SG_ 936 ApaGearShif_D_RqDrv 1;
BA_ "U_CD764_MY2022_Tx" SG_ 936 ApaGearShif_D_RqDrv 1;
BA_ "U_CDX706_MY2023_Tx" SG_ 936 ApaGearShif_D_RqDrv 1;
BA_ "U_T6_MCA_MY2020_Tx" SG_ 936 ApaActvSide2_D_Stat 1;
BA_ "U_CD542_MY2021_Tx" SG_ 936 ApaActvSide2_D_Stat 1;
BA_ "U_U55X_MY2022_Tx" SG_ 936 ApaActvSide2_D_Stat 1;
BA_ "U_CD764_MY2022_Tx" SG_ 936 ApaActvSide2_D_Stat 1;
BA_ "U_CDX706_MY2023_Tx" SG_ 936 ApaActvSide2_D_Stat 1;
BA_ "U_T6_MCA_MY2020_Tx" SG_ 936 ApaAcsy_D_RqDrv 1;
BA_ "U_CD542_MY2021_Tx" SG_ 936 ApaAcsy_D_RqDrv 1;
BA_ "U_U55X_MY2022_Tx" SG_ 936 ApaAcsy_D_RqDrv 1;
BA_ "U_CD764_MY2022_Tx" SG_ 936 ApaAcsy_D_RqDrv 1;
BA_ "U_CDX706_MY2023_Tx" SG_ 936 ApaAcsy_D_RqDrv 1;
BA_ "U_T6_MCA_MY2020_Tx" SG_ 936 ApaTrgtDist_D_Stat 1;
BA_ "U_CD542_MY2021_Tx" SG_ 936 ApaTrgtDist_D_Stat 1;
BA_ "U_U55X_MY2022_Tx" SG_ 936 ApaTrgtDist_D_Stat 1;
BA_ "U_CD764_MY2022_Tx" SG_ 936 ApaTrgtDist_D_Stat 1;
BA_ "U_CDX706_MY2023_Tx" SG_ 936 ApaTrgtDist_D_Stat 1;
BA_ "U_T6_MCA_MY2020_Tx" SG_ 936 ApaMsgTxt_D_Rq 1;
BA_ "U_CD542_MY2021_Tx" SG_ 936 ApaMsgTxt_D_Rq 1;
BA_ "U_U55X_MY2022_Tx" SG_ 936 ApaMsgTxt_D_Rq 1;
BA_ "U_CD764_MY2022_Tx" SG_ 936 ApaMsgTxt_D_Rq 1;
BA_ "U_CDX706_MY2023_Tx" SG_ 936 ApaMsgTxt_D_Rq 1;
BA_ "U_T6_MCA_MY2020_Tx" SG_ 936 ApaChime_D_Rq 1;
BA_ "U_CD542_MY2021_Tx" SG_ 936 ApaChime_D_Rq 1;
BA_ "U_U55X_MY2022_Tx" SG_ 936 ApaChime_D_Rq 1;
BA_ "U_CD764_MY2022_Tx" SG_ 936 ApaChime_D_Rq 1;
BA_ "U_CDX706_MY2023_Tx" SG_ 936 ApaChime_D_Rq 1;
BA_ "U_T6_MCA_MY2020_Tx" SG_ 936 SAPPStatusCoding 1;
BA_ "U_CD542_MY2021_Tx" SG_ 936 SAPPStatusCoding 1;
BA_ "U_U55X_MY2022_Tx" SG_ 936 SAPPStatusCoding 1;
BA_ "U_CD764_MY2022_Tx" SG_ 936 SAPPStatusCoding 1;
BA_ "U_CDX706_MY2023_Tx" SG_ 936 SAPPStatusCoding 1;
BA_ "U_CX727_MY2021_Rx" SG_ 936 EPASExtAngleStatReq 1;
BA_ "U_P702_MY2021_Rx" SG_ 936 EPASExtAngleStatReq 1;
BA_ "U_T6_MCA_MY2020_Rx" SG_ 936 EPASExtAngleStatReq 1;
BA_ "U_CD542_MY2021_Rx" SG_ 936 EPASExtAngleStatReq 1;
BA_ "U_U55X_MY2022_Rx" SG_ 936 EPASExtAngleStatReq 1;
BA_ "U_CD764_MY2022_Rx" SG_ 936 EPASExtAngleStatReq 1;
BA_ "U_CDX706_MY2023_Rx" SG_ 936 EPASExtAngleStatReq 1;
BA_ "U_T6_MCA_MY2020_Tx" SG_ 936 EPASExtAngleStatReq 1;
BA_ "U_CD542_MY2021_Tx" SG_ 936 EPASExtAngleStatReq 1;
BA_ "U_U55X_MY2022_Tx" SG_ 936 EPASExtAngleStatReq 1;
BA_ "U_CD764_MY2022_Tx" SG_ 936 EPASExtAngleStatReq 1;
BA_ "U_CDX706_MY2023_Tx" SG_ 936 EPASExtAngleStatReq 1;
BA_ "U_CX727_MY2021_Rx" SG_ 936 ExtSteeringAngleReq2 1;
BA_ "U_P702_MY2021_Rx" SG_ 936 ExtSteeringAngleReq2 1;
BA_ "U_T6_MCA_MY2020_Rx" SG_ 936 ExtSteeringAngleReq2 1;
BA_ "U_CD542_MY2021_Rx" SG_ 936 ExtSteeringAngleReq2 1;
BA_ "U_U55X_MY2022_Rx" SG_ 936 ExtSteeringAngleReq2 1;
BA_ "U_CD764_MY2022_Rx" SG_ 936 ExtSteeringAngleReq2 1;
BA_ "U_CDX706_MY2023_Rx" SG_ 936 ExtSteeringAngleReq2 1;
BA_ "U_T6_MCA_MY2020_Tx" SG_ 936 ExtSteeringAngleReq2 1;
BA_ "U_CD542_MY2021_Tx" SG_ 936 ExtSteeringAngleReq2 1;
BA_ "U_U55X_MY2022_Tx" SG_ 936 ExtSteeringAngleReq2 1;
BA_ "U_CD764_MY2022_Tx" SG_ 936 ExtSteeringAngleReq2 1;
BA_ "U_CDX706_MY2023_Tx" SG_ 936 ExtSteeringAngleReq2 1;
BA_ "U_T6_MCA_MY2020_Tx" SG_ 936 ApaButtnPrssd_B_Stat 1;
BA_ "U_U55X_MY2022_Tx" SG_ 936 ApaButtnPrssd_B_Stat 1;
BA_ "U_CDX706_MY2023_Tx" SG_ 936 ApaButtnPrssd_B_Stat 1;
BA_ "GenSigStartValueInteger" SG_ 877 RngImpctDrv_L_Dsply 255;
BA_ "U_CX727_MY2021_Tx" SG_ 877 RngImpctDrv_L_Dsply 1;
BA_ "U_P702_MY2021_Tx" SG_ 877 RngImpctDrv_L_Dsply 1;
BA_ "U_CD542_MY2021_Tx" SG_ 877 RngImpctDrv_L_Dsply 1;
BA_ "U_CDX706_MY2023_Tx" SG_ 877 RngImpctDrv_L_Dsply 1;
BA_ "GenSigStartValueInteger" SG_ 877 RngImpctClim_L_Dsply 255;
BA_ "U_CX727_MY2021_Tx" SG_ 877 RngImpctClim_L_Dsply 1;
BA_ "U_P702_MY2021_Tx" SG_ 877 RngImpctClim_L_Dsply 1;
BA_ "U_CD542_MY2021_Tx" SG_ 877 RngImpctClim_L_Dsply 1;
BA_ "U_CDX706_MY2023_Tx" SG_ 877 RngImpctClim_L_Dsply 1;
BA_ "GenSigStartValueInteger" SG_ 877 VehElEffAvg_No_Dsply 126;
BA_ "GenSigStartValue" SG_ 877 VehElEffAvg_No_Dsply 126;
BA_ "ECGUsedRxSignal" SG_ 877 VehElEffAvg_No_Dsply 1;
BA_ "U_CDX706_MY2023_Rx" SG_ 877 VehElEffAvg_No_Dsply 1;
BA_ "U_CX727_MY2021_Tx" SG_ 877 VehElEffAvg_No_Dsply 1;
BA_ "U_P702_MY2021_Tx" SG_ 877 VehElEffAvg_No_Dsply 1;
BA_ "U_CD542_MY2021_Tx" SG_ 877 VehElEffAvg_No_Dsply 1;
BA_ "U_CDX706_MY2023_Tx" SG_ 877 VehElEffAvg_No_Dsply 1;
BA_ "GenSigSendType" SG_ 877 PwFlwFuelDrv_D_Dsply 3;
BA_ "U_CX727_MY2021_Tx" SG_ 877 PwFlwFuelDrv_D_Dsply 1;
BA_ "U_P702_MY2021_Tx" SG_ 877 PwFlwFuelDrv_D_Dsply 1;
BA_ "U_CD542_MY2021_Tx" SG_ 877 PwFlwFuelDrv_D_Dsply 1;
BA_ "U_CDX706_MY2023_Tx" SG_ 877 PwFlwFuelDrv_D_Dsply 1;
BA_ "GenSigSendType" SG_ 877 PwFlwFuelClimt_B_Dsply 3;
BA_ "U_P702_MY2021_Tx" SG_ 877 PwFlwFuelClimt_B_Dsply 1;
BA_ "U_CD542_MY2021_Tx" SG_ 877 PwFlwFuelClimt_B_Dsply 1;
BA_ "U_CDX706_MY2023_Tx" SG_ 877 PwFlwFuelClimt_B_Dsply 1;
BA_ "GenSigSendType" SG_ 877 PwFlwFuelBatt_B_Dsply 3;
BA_ "U_CX727_MY2021_Tx" SG_ 877 PwFlwFuelBatt_B_Dsply 1;
BA_ "U_P702_MY2021_Tx" SG_ 877 PwFlwFuelBatt_B_Dsply 1;
BA_ "U_CD542_MY2021_Tx" SG_ 877 PwFlwFuelBatt_B_Dsply 1;
BA_ "U_CDX706_MY2023_Tx" SG_ 877 PwFlwFuelBatt_B_Dsply 1;
BA_ "GenSigSendType" SG_ 877 PwFlwBattGen_D_Dsply 3;
BA_ "U_CX727_MY2021_Tx" SG_ 877 PwFlwBattGen_D_Dsply 1;
BA_ "U_P702_MY2021_Tx" SG_ 877 PwFlwBattGen_D_Dsply 1;
BA_ "U_CD542_MY2021_Tx" SG_ 877 PwFlwBattGen_D_Dsply 1;
BA_ "U_CDX706_MY2023_Tx" SG_ 877 PwFlwBattGen_D_Dsply 1;
BA_ "GenSigSendType" SG_ 877 PwFlwBattClimt_B_Dsply 3;
BA_ "U_CX727_MY2021_Tx" SG_ 877 PwFlwBattClimt_B_Dsply 1;
BA_ "U_P702_MY2021_Tx" SG_ 877 PwFlwBattClimt_B_Dsply 1;
BA_ "U_CD542_MY2021_Tx" SG_ 877 PwFlwBattClimt_B_Dsply 1;
BA_ "U_CDX706_MY2023_Tx" SG_ 877 PwFlwBattClimt_B_Dsply 1;
BA_ "GenSigSendType" SG_ 877 PwFlwBatt_D_Dsply 3;
BA_ "U_CX727_MY2021_Tx" SG_ 877 PwFlwBatt_D_Dsply 1;
BA_ "U_P702_MY2021_Tx" SG_ 877 PwFlwBatt_D_Dsply 1;
BA_ "U_CD542_MY2021_Tx" SG_ 877 PwFlwBatt_D_Dsply 1;
BA_ "U_CDX706_MY2023_Tx" SG_ 877 PwFlwBatt_D_Dsply 1;
BA_ "GenSigStartValueInteger" SG_ 877 RngPerChrgAvg_L2_Dsply 4094;
BA_ "GenSigStartValue" SG_ 877 RngPerChrgAvg_L2_Dsply 8190;
BA_ "ECGUsedRxSignal" SG_ 877 RngPerChrgAvg_L2_Dsply 1;
BA_ "U_CD542_MY2021_Rx" SG_ 877 RngPerChrgAvg_L2_Dsply 1;
BA_ "U_CDX706_MY2023_Rx" SG_ 877 RngPerChrgAvg_L2_Dsply 1;
BA_ "GenSigStartValueInteger" SG_ 791 StopStrtVThres_D_RqMnu 1;
BA_ "GenSigStartValue" SG_ 791 StopStrtVThres_D_RqMnu 1;
BA_ "U_P702_MY2021_Rx" SG_ 791 EngAirFilt_B_RqReset 1;
BA_ "U_CDX706_MY2023_Rx" SG_ 791 EngAirFilt_B_RqReset 1;
BA_ "GenSigStartValueInteger" SG_ 791 BattElEmotive_Pc_Dsply 1022;
BA_ "GenSigStartValue" SG_ 791 BattElEmotive_Pc_Dsply 1022;
BA_ "U_CX727_MY2021_Rx" SG_ 791 HybMdeOvrrd_D_Rq 1;
BA_ "U_CD542_MY2021_Rx" SG_ 791 HybMdeOvrrd_D_Rq 1;
BA_ "U_CDX706_MY2023_Rx" SG_ 791 HybMdeOvrrd_D_Rq 1;
BA_ "U_CX727_MY2021_Rx" SG_ 791 GpsElMdeSel_B_Rq 1;
BA_ "U_CD542_MY2021_Rx" SG_ 791 GpsElMdeSel_B_Rq 1;
BA_ "U_CX727_MY2021_Rx" SG_ 791 LongTermReset_B_Rq 1;
BA_ "U_CD542_MY2021_Rx" SG_ 791 LongTermReset_B_Rq 1;
BA_ "U_CDX706_MY2023_Rx" SG_ 791 LongTermReset_B_Rq 1;
BA_ "U_CX727_MY2021_Rx" SG_ 791 DrvEffLvl_No_Stat 1;
BA_ "U_CD542_MY2021_Rx" SG_ 791 DrvEffLvl_No_Stat 1;
BA_ "U_CDX706_MY2023_Rx" SG_ 791 DrvEffLvl_No_Stat 1;
BA_ "WakeupSignal" SG_ 791 ChargeProfIDPref_Rq 1;
BA_ "U_CX727_MY2021_Rx" SG_ 791 GrdAsstAllw_D_RqMnu 1;
BA_ "U_CD542_MY2021_Rx" SG_ 791 GrdAsstAllw_D_RqMnu 1;
BA_ "U_CDX706_MY2023_Rx" SG_ 791 GrdAsstAllw_D_RqMnu 1;
BA_ "U_CX727_MY2021_Rx" SG_ 791 PlgOvrrdStrt_D_Cmd 1;
BA_ "U_CD542_MY2021_Rx" SG_ 791 PlgOvrrdStrt_D_Cmd 1;
BA_ "GenSigStartValueInteger" SG_ 791 EcoMde_D_RqMnu 1;
BA_ "GenSigStartValue" SG_ 791 EcoMde_D_RqMnu 1;
BA_ "U_CX727_MY2021_Rx" SG_ 791 EcoMde_D_RqMnu 1;
BA_ "U_CD542_MY2021_Rx" SG_ 791 EcoMde_D_RqMnu 1;
BA_ "U_CDX706_MY2023_Rx" SG_ 791 VehElEffTrip2Reset_B_Rq 1;
BA_ "U_CDX706_MY2023_Rx" SG_ 791 VehElEffTrip1Reset_B_Rq 1;
BA_ "ECGUsedRxSignal" SG_ 786 VehElRngeCyc_L_Dsply 1;
BA_ "U_CD542_MY2021_Rx" SG_ 786 VehElRngeCyc_L_Dsply 1;
BA_ "U_U55X_MY2022_Rx" SG_ 786 VehElRngeCyc_L_Dsply 1;
BA_ "U_CDX706_MY2023_Rx" SG_ 786 VehElRngeCyc_L_Dsply 1;
BA_ "U_CX727_MY2021_Tx" SG_ 786 VehElRngeCyc_L_Dsply 1;
BA_ "U_CD542_MY2021_Tx" SG_ 786 VehElRngeCyc_L_Dsply 1;
BA_ "ECGUsedRxSignal" SG_ 786 RgenTrip_Pc_Dsply 1;
BA_ "U_CD542_MY2021_Rx" SG_ 786 RgenTrip_Pc_Dsply 1;
BA_ "U_U55X_MY2022_Rx" SG_ 786 RgenTrip_Pc_Dsply 1;
BA_ "U_CDX706_MY2023_Rx" SG_ 786 RgenTrip_Pc_Dsply 1;
BA_ "U_CX727_MY2021_Tx" SG_ 786 RgenTrip_Pc_Dsply 1;
BA_ "U_P702_MY2021_Tx" SG_ 786 RgenTrip_Pc_Dsply 1;
BA_ "U_CD542_MY2021_Tx" SG_ 786 RgenTrip_Pc_Dsply 1;
BA_ "GenSigStartValueInteger" SG_ 786 RgenTrip_L_Dsply 65535;
BA_ "GenSigStartValue" SG_ 786 RgenTrip_L_Dsply 65535;
BA_ "ECGUsedRxSignal" SG_ 786 RgenTrip_L_Dsply 1;
BA_ "U_CD542_MY2021_Rx" SG_ 786 RgenTrip_L_Dsply 1;
BA_ "U_U55X_MY2022_Rx" SG_ 786 RgenTrip_L_Dsply 1;
BA_ "U_CDX706_MY2023_Rx" SG_ 786 RgenTrip_L_Dsply 1;
BA_ "U_CX727_MY2021_Tx" SG_ 786 RgenTrip_L_Dsply 1;
BA_ "U_P702_MY2021_Tx" SG_ 786 RgenTrip_L_Dsply 1;
BA_ "U_CD542_MY2021_Tx" SG_ 786 RgenTrip_L_Dsply 1;
BA_ "ECGUsedRxSignal" SG_ 786 PtDataKeyId_D_Stat 1;
BA_ "U_CD542_MY2021_Rx" SG_ 786 PtDataKeyId_D_Stat 1;
BA_ "U_U55X_MY2022_Rx" SG_ 786 PtDataKeyId_D_Stat 1;
BA_ "U_CDX706_MY2023_Rx" SG_ 786 PtDataKeyId_D_Stat 1;
BA_ "U_CX727_MY2021_Tx" SG_ 786 PtDataKeyId_D_Stat 1;
BA_ "U_CD542_MY2021_Tx" SG_ 786 PtDataKeyId_D_Stat 1;
BA_ "U_CDX706_MY2023_Tx" SG_ 786 PtDataKeyId_D_Stat 1;
BA_ "ECGUsedRxSignal" SG_ 786 ChrgStat_D_Dsply 1;
BA_ "U_CD542_MY2021_Rx" SG_ 786 ChrgStat_D_Dsply 1;
BA_ "U_U55X_MY2022_Rx" SG_ 786 ChrgStat_D_Dsply 1;
BA_ "U_CDX706_MY2023_Rx" SG_ 786 ChrgStat_D_Dsply 1;
BA_ "U_CX727_MY2021_Tx" SG_ 786 ChrgStat_D_Dsply 1;
BA_ "U_P702_MY2021_Tx" SG_ 786 ChrgStat_D_Dsply 1;
BA_ "U_CD542_MY2021_Tx" SG_ 786 ChrgStat_D_Dsply 1;
BA_ "GenSigStartValue" SG_ 786 VehElRnge_L2_Dsply 8191;
BA_ "ECGUsedRxSignal" SG_ 786 VehElRnge_L2_Dsply 1;
BA_ "U_CD542_MY2021_Rx" SG_ 786 VehElRnge_L2_Dsply 1;
BA_ "U_U55X_MY2022_Rx" SG_ 786 VehElRnge_L2_Dsply 1;
BA_ "U_CDX706_MY2023_Rx" SG_ 786 VehElRnge_L2_Dsply 1;
BA_ "U_CX727_MY2021_Rx" SG_ 748 ChrgrOutHi_U_Actl 1;
BA_ "U_CD542_MY2021_Rx" SG_ 748 ChrgrOutHi_U_Actl 1;
BA_ "U_CX727_MY2021_Rx" SG_ 748 ChrgrOutHi_I_Actl 1;
BA_ "U_CD542_MY2021_Rx" SG_ 748 ChrgrOutHi_I_Actl 1;
BA_ "U_CX727_MY2021_Rx" SG_ 748 ChrgrIn_Pw_Mx 1;
BA_ "U_CD542_MY2021_Rx" SG_ 748 ChrgrIn_Pw_Mx 1;
BA_ "U_CDX706_MY2023_Rx" SG_ 748 ChrgrIn_Pw_Mx 1;
BA_ "WakeupSignal" SG_ 748 PtWakeupActv3_B_Rq 1;
BA_ "GenSigStartValueInteger" SG_ 748 PlgActv_D_ActlChrgr 3;
BA_ "GenSigStartValue" SG_ 748 PlgActv_D_ActlChrgr 2;
BA_ "U_CX727_MY2021_Rx" SG_ 748 PlgActv_D_ActlChrgr 1;
BA_ "U_CX727_MY2021_Rx" SG_ 748 ChrgrRdyStat_D_Actl 1;
BA_ "U_CD542_MY2021_Rx" SG_ 748 ChrgrRdyStat_D_Actl 1;
BA_ "U_CDX706_MY2023_Rx" SG_ 748 ChrgrRdyStat_D_Actl 1;
BA_ "GenSigStartValueInteger" SG_ 740 BattDcChrg_U_Actl 1022;
BA_ "GenSigStartValue" SG_ 740 BattDcChrg_U_Actl 1022;
BA_ "U_CX727_MY2021_Rx" SG_ 740 BattTracSoc_Pc_Dpltd 1;
BA_ "U_CD542_MY2021_Rx" SG_ 740 BattTracSoc_Pc_Dpltd 1;
BA_ "U_CX727_MY2021_Rx" SG_ 740 BattAuxCnnct_B_Cmd 1;
BA_ "U_CD542_MY2021_Rx" SG_ 740 BattAuxCnnct_B_Cmd 1;
BA_ "WakeupSignal" SG_ 740 PtWakeupActv2_B_Rq 1;
BA_ "U_CX727_MY2021_Rx" SG_ 740 BattChrg_U_Rq 1;
BA_ "U_CD542_MY2021_Rx" SG_ 740 BattChrg_U_Rq 1;
BA_ "U_CX727_MY2021_Rx" SG_ 740 BattChrg_I_Rq 1;
BA_ "U_CD542_MY2021_Rx" SG_ 740 BattChrg_I_Rq 1;
BA_ "U_CX727_MY2021_Rx" SG_ 589 BattTrac2_Pw_LimChrg 1;
BA_ "U_P702_MY2021_Rx" SG_ 589 BattTrac2_Pw_LimChrg 1;
BA_ "U_CD542_MY2021_Rx" SG_ 589 BattTrac2_Pw_LimChrg 1;
BA_ "U_CDX706_MY2023_Rx" SG_ 589 BattTrac2_Pw_LimChrg 1;
BA_ "U_CX727_MY2021_Rx" SG_ 589 BattTrac2_Pw_LimDchrg 1;
BA_ "U_P702_MY2021_Rx" SG_ 589 BattTrac2_Pw_LimDchrg 1;
BA_ "U_CD542_MY2021_Rx" SG_ 589 BattTrac2_Pw_LimDchrg 1;
BA_ "U_CDX706_MY2023_Rx" SG_ 589 BattTrac2_Pw_LimDchrg 1;
BA_ "U_CX727_MY2021_Rx" SG_ 589 BattTrac2_Pw_DchrgInst 1;
BA_ "U_P702_MY2021_Rx" SG_ 589 BattTrac2_Pw_DchrgInst 1;
BA_ "U_CD542_MY2021_Rx" SG_ 589 BattTrac2_Pw_DchrgInst 1;
BA_ "U_CDX706_MY2023_Rx" SG_ 589 BattTrac2_Pw_DchrgInst 1;
BA_ "U_CX727_MY2021_Rx" SG_ 589 BattTrac2_Pw_ChrgInst 1;
BA_ "U_P702_MY2021_Rx" SG_ 589 BattTrac2_Pw_ChrgInst 1;
BA_ "U_CD542_MY2021_Rx" SG_ 589 BattTrac2_Pw_ChrgInst 1;
BA_ "U_CDX706_MY2023_Rx" SG_ 589 BattTrac2_Pw_ChrgInst 1;
BA_ "WakeupSignal" SG_ 588 HvacAirFlw_B_RqBatt 1;
BA_ "U_CX727_MY2021_Rx" SG_ 588 BattChrgRdyStat_D_Actl 1;
BA_ "U_CD542_MY2021_Rx" SG_ 588 BattChrgRdyStat_D_Actl 1;
BA_ "U_CDX706_MY2023_Rx" SG_ 588 BattChrgRdyStat_D_Actl 1;
BA_ "GenSigStartValueInteger" SG_ 588 BattTracSoc2_Pc_Actl 16382;
BA_ "GenSigStartValue" SG_ 588 BattTracSoc2_Pc_Actl 16382;
BA_ "U_CX727_MY2021_Rx" SG_ 588 BattTracSoc2_Pc_Actl 1;
BA_ "U_P702_MY2021_Rx" SG_ 588 BattTracSoc2_Pc_Actl 1;
BA_ "U_CD542_MY2021_Rx" SG_ 588 BattTracSoc2_Pc_Actl 1;
BA_ "U_CDX706_MY2023_Rx" SG_ 588 BattTracSoc2_Pc_Actl 1;
BA_ "GenSigStartValueInteger" SG_ 588 BattTracSoc_Pc_Dsply 254;
BA_ "GenSigStartValue" SG_ 588 BattTracSoc_Pc_Dsply 254;
BA_ "U_CX727_MY2021_Rx" SG_ 588 BattTracSoc_Pc_Dsply 1;
BA_ "U_CD542_MY2021_Rx" SG_ 588 BattTracSoc_Pc_Dsply 1;
BA_ "GenSigStartValueInteger" SG_ 588 BattTracClntIn_Te_Actl 75;
BA_ "GenSigStartValue" SG_ 588 BattTracClntIn_Te_Actl 75;
BA_ "GenSigStartValueInteger" SG_ 588 BattTrac_Te_Actl 150;
BA_ "GenSigStartValue" SG_ 588 BattTrac_Te_Actl 150;
BA_ "U_CX727_MY2021_Rx" SG_ 588 BattTrac_Te_Actl 1;
BA_ "U_P702_MY2021_Rx" SG_ 588 BattTrac_Te_Actl 1;
BA_ "U_CD542_MY2021_Rx" SG_ 588 BattTrac_Te_Actl 1;
BA_ "U_CDX706_MY2023_Rx" SG_ 588 BattTrac_Te_Actl 1;
BA_ "GenSigStartValueInteger" SG_ 588 HvacRec_D_RqMxBatt 10;
BA_ "GenSigStartValue" SG_ 588 HvacRec_D_RqMxBatt 10;
BA_ "GenSigStartValueInteger" SG_ 587 BattTracClnt_Te_Actl 164;
BA_ "GenSigStartValue" SG_ 587 BattTracClnt_Te_Actl 254;
BA_ "U_CX727_MY2021_Rx" SG_ 587 BattTracClnt_Te_Actl 1;
BA_ "U_P702_MY2021_Rx" SG_ 587 BattTracClnt_Te_Actl 1;
BA_ "U_CD542_MY2021_Rx" SG_ 587 BattTracClnt_Te_Actl 1;
BA_ "U_CDX706_MY2023_Rx" SG_ 587 BattTracClnt_Te_Actl 1;
BA_ "GenSigStartValueInteger" SG_ 587 BattTracClnt_Te_Rq 190;
BA_ "GenSigStartValue" SG_ 587 BattTracClnt_Te_Rq 190;
BA_ "GenSigStartValueInteger" SG_ 587 BattTracSoc_Pc_MxPrtct 700;
BA_ "GenSigStartValue" SG_ 587 BattTracSoc_Pc_MxPrtct 700;
BA_ "U_CX727_MY2021_Rx" SG_ 587 BattTracSoc_Pc_MxPrtct 1;
BA_ "U_P702_MY2021_Rx" SG_ 587 BattTracSoc_Pc_MxPrtct 1;
BA_ "U_CD542_MY2021_Rx" SG_ 587 BattTracSoc_Pc_MxPrtct 1;
BA_ "U_CDX706_MY2023_Rx" SG_ 587 BattTracSoc_Pc_MxPrtct 1;
BA_ "GenSigStartValueInteger" SG_ 587 BattTracSoc_Pc_MnPrtct 300;
BA_ "GenSigStartValue" SG_ 587 BattTracSoc_Pc_MnPrtct 30;
BA_ "U_CX727_MY2021_Rx" SG_ 587 BattTracSoc_Pc_MnPrtct 1;
BA_ "U_P702_MY2021_Rx" SG_ 587 BattTracSoc_Pc_MnPrtct 1;
BA_ "U_CD542_MY2021_Rx" SG_ 587 BattTracSoc_Pc_MnPrtct 1;
BA_ "U_CDX706_MY2023_Rx" SG_ 587 BattTracSoc_Pc_MnPrtct 1;
BA_ "GenSigStartValueInteger" SG_ 587 BattTracSoc_Pc_LimLo 400;
BA_ "GenSigStartValue" SG_ 587 BattTracSoc_Pc_LimLo 400;
BA_ "U_CX727_MY2021_Rx" SG_ 587 BattTracSoc_Pc_LimLo 1;
BA_ "U_P702_MY2021_Rx" SG_ 587 BattTracSoc_Pc_LimLo 1;
BA_ "U_CD542_MY2021_Rx" SG_ 587 BattTracSoc_Pc_LimLo 1;
BA_ "U_CDX706_MY2023_Rx" SG_ 587 BattTracSoc_Pc_LimLo 1;
BA_ "GenSigStartValueInteger" SG_ 587 BattTracSoc_Pc_LimHi 600;
BA_ "GenSigStartValue" SG_ 587 BattTracSoc_Pc_LimHi 600;
BA_ "U_CX727_MY2021_Rx" SG_ 587 BattTracSoc_Pc_LimHi 1;
BA_ "U_P702_MY2021_Rx" SG_ 587 BattTracSoc_Pc_LimHi 1;
BA_ "U_CD542_MY2021_Rx" SG_ 587 BattTracSoc_Pc_LimHi 1;
BA_ "U_CDX706_MY2023_Rx" SG_ 587 BattTracSoc_Pc_LimHi 1;
BA_ "U_CX727_MY2021_Tx" SG_ 389 BattTracClntFlw_Pc_Rq 1;
BA_ "U_P702_MY2021_Tx" SG_ 389 BattTracClntFlw_Pc_Rq 1;
BA_ "U_CD542_MY2021_Tx" SG_ 389 BattTracClntFlw_Pc_Rq 1;
BA_ "U_CDX706_MY2023_Tx" SG_ 389 BattTracClntFlw_Pc_Rq 1;
BA_ "U_CX727_MY2021_Tx" SG_ 389 HtrnOvrTeLamp_B_Dsply 1;
BA_ "U_P702_MY2021_Tx" SG_ 389 HtrnOvrTeLamp_B_Dsply 1;
BA_ "U_CD542_MY2021_Tx" SG_ 389 HtrnOvrTeLamp_B_Dsply 1;
BA_ "U_CDX706_MY2023_Tx" SG_ 389 HtrnOvrTeLamp_B_Dsply 1;
BA_ "U_CX727_MY2021_Tx" SG_ 389 HtrnMil_D_Rq 1;
BA_ "U_P702_MY2021_Tx" SG_ 389 HtrnMil_D_Rq 1;
BA_ "U_CD542_MY2021_Tx" SG_ 389 HtrnMil_D_Rq 1;
BA_ "U_CDX706_MY2023_Tx" SG_ 389 HtrnMil_D_Rq 1;
BA_ "U_P702_MY2021_Rx" SG_ 389 HtrnAin_UHi_Actl 1;
BA_ "ECGUsedRxSignal" SG_ 389 HtrnAin_UHi_Actl 1;
BA_ "U_CD542_MY2021_Rx" SG_ 389 HtrnAin_UHi_Actl 1;
BA_ "U_U55X_MY2022_Rx" SG_ 389 HtrnAin_UHi_Actl 1;
BA_ "U_CD764_MY2022_Rx" SG_ 389 HtrnAin_UHi_Actl 1;
BA_ "U_CDX706_MY2023_Rx" SG_ 389 HtrnAin_UHi_Actl 1;
BA_ "U_CX727_MY2021_Tx" SG_ 389 HtrnAin_UHi_Actl 1;
BA_ "U_P702_MY2021_Tx" SG_ 389 HtrnAin_UHi_Actl 1;
BA_ "U_CD542_MY2021_Tx" SG_ 389 HtrnAin_UHi_Actl 1;
BA_ "U_CDX706_MY2023_Tx" SG_ 389 HtrnAin_UHi_Actl 1;
BA_ "ECGUsedRxSignal" SG_ 389 HtrnSrvcRqd_B_Dsply 1;
BA_ "U_CD764_MY2022_Rx" SG_ 389 HtrnSrvcRqd_B_Dsply 1;
BA_ "U_CDX706_MY2023_Rx" SG_ 389 HtrnSrvcRqd_B_Dsply 1;
BA_ "U_CX727_MY2021_Tx" SG_ 389 HtrnSrvcRqd_B_Dsply 1;
BA_ "U_P702_MY2021_Tx" SG_ 389 HtrnSrvcRqd_B_Dsply 1;
BA_ "U_CD542_MY2021_Tx" SG_ 389 HtrnSrvcRqd_B_Dsply 1;
BA_ "U_CDX706_MY2023_Tx" SG_ 389 HtrnSrvcRqd_B_Dsply 1;
BA_ "U_P702_MY2021_Rx" SG_ 389 HtrnHvilOpen_B_Actl 1;
BA_ "ECGUsedRxSignal" SG_ 389 HtrnHvilOpen_B_Actl 1;
BA_ "U_CD542_MY2021_Rx" SG_ 389 HtrnHvilOpen_B_Actl 1;
BA_ "U_U55X_MY2022_Rx" SG_ 389 HtrnHvilOpen_B_Actl 1;
BA_ "U_CD764_MY2022_Rx" SG_ 389 HtrnHvilOpen_B_Actl 1;
BA_ "U_CDX706_MY2023_Rx" SG_ 389 HtrnHvilOpen_B_Actl 1;
BA_ "U_CX727_MY2021_Tx" SG_ 389 HtrnHvilOpen_B_Actl 1;
BA_ "U_P702_MY2021_Tx" SG_ 389 HtrnHvilOpen_B_Actl 1;
BA_ "U_CD542_MY2021_Tx" SG_ 389 HtrnHvilOpen_B_Actl 1;
BA_ "U_CDX706_MY2023_Tx" SG_ 389 HtrnHvilOpen_B_Actl 1;
BA_ "U_CX727_MY2021_Tx" SG_ 389 PtWakeupDeltaT_T_Rq 1;
BA_ "U_P702_MY2021_Tx" SG_ 389 PtWakeupDeltaT_T_Rq 1;
BA_ "U_CD542_MY2021_Tx" SG_ 389 PtWakeupDeltaT_T_Rq 1;
BA_ "U_CX727_MY2021_Rx" SG_ 389 PreCondActv_B_Actl 1;
BA_ "U_CD542_MY2021_Rx" SG_ 389 PreCondActv_B_Actl 1;
BA_ "U_CDX706_MY2023_Rx" SG_ 389 PreCondActv_B_Actl 1;
BA_ "U_CX727_MY2021_Tx" SG_ 389 PreCondActv_B_Actl 1;
BA_ "U_P702_MY2021_Tx" SG_ 389 PreCondActv_B_Actl 1;
BA_ "U_CD542_MY2021_Tx" SG_ 389 PreCondActv_B_Actl 1;
BA_ "U_CX727_MY2021_Tx" SG_ 389 DrvCondTpRrDefrs_B_Rq 1;
BA_ "U_P702_MY2021_Tx" SG_ 389 DrvCondTpRrDefrs_B_Rq 1;
BA_ "U_CD542_MY2021_Tx" SG_ 389 DrvCondTpRrDefrs_B_Rq 1;
BA_ "U_CDX706_MY2023_Tx" SG_ 389 DrvCondTpRrDefrs_B_Rq 1;
BA_ "GenSigStartValueInteger" SG_ 389 BattTrac_I_EstVsc 15000;
BA_ "U_CX727_MY2021_Tx" SG_ 389 BattTrac_I_EstVsc 1;
BA_ "U_P702_MY2021_Tx" SG_ 389 BattTrac_I_EstVsc 1;
BA_ "U_CD542_MY2021_Tx" SG_ 389 BattTrac_I_EstVsc 1;
BA_ "U_CDX706_MY2023_Tx" SG_ 389 BattTrac_I_EstVsc 1;
BA_ "ContentDependant" SG_ 361 TrcmSrvcRqd_B_Rq 1;
BA_ "ContentDependant" SG_ 361 TrnGear_I_MeasMax 1;
BA_ "ContentDependant" SG_ 361 TrnCapHlth_Actl 1;
BA_ "ContentDependant" SG_ 361 TrnPwmFalt_B_Actl 1;
BA_ "ContentDependant" SG_ 361 TrnActFalt_B_Actl 1;
BA_ "U_T6_MCA_MY2020_Rx" SG_ 1009 AutoHoldSwtch_D_Stat3 1;
BA_ "U_CD542_MY2021_Rx" SG_ 1009 AutoHoldSwtch_D_Stat3 1;
BA_ "U_U55X_MY2022_Rx" SG_ 1009 AutoHoldSwtch_D_Stat3 1;
BA_ "U_CD764_MY2022_Rx" SG_ 1009 AutoHoldSwtch_D_Stat3 1;
BA_ "U_CDX706_MY2023_Rx" SG_ 1009 AutoHoldSwtch_D_Stat3 1;
BA_ "U_P702_MY2021_Rx" SG_ 1009 TrlrAidCancl_B_Rq 1;
BA_ "U_T6_MCA_MY2020_Rx" SG_ 1009 TrlrAidCancl_B_Rq 1;
BA_ "U_CD542_MY2021_Rx" SG_ 1009 TrlrAidCancl_B_Rq 1;
BA_ "U_U55X_MY2022_Rx" SG_ 1009 TrlrAidCancl_B_Rq 1;
BA_ "U_CDX706_MY2023_Rx" SG_ 1009 TrlrAidCancl_B_Rq 1;
BA_ "GenSigStartValueInteger" SG_ 1009 CenterStackRing_D_Actl 2;
BA_ "GenSigStartValue" SG_ 1009 CenterStackRing_D_Actl 2;
BA_ "ContentDependant" SG_ 360 GsmSrvcRqd_B_Rq 1;
BA_ "U_CX727_MY2021_Rx" SG_ 360 GsmSrvcRqd_B_Rq 1;
BA_ "U_CD542_MY2021_Rx" SG_ 360 GsmSrvcRqd_B_Rq 1;
BA_ "U_CDX706_MY2023_Rx" SG_ 360 GsmSrvcRqd_B_Rq 1;
BA_ "ContentDependant" SG_ 360 TrnTrcmPwmSig_D_Actl 1;
BA_ "U_CDX706_MY2023_Rx" SG_ 360 TrnTrcmPwmSig_D_Actl 1;
BA_ "ContentDependant" SG_ 360 TrnGearPwmFalt_B_Actl 1;
BA_ "U_CX727_MY2021_Rx" SG_ 360 TrnGearPwmFalt_B_Actl 1;
BA_ "U_P702_MY2021_Rx" SG_ 360 TrnGearPwmFalt_B_Actl 1;
BA_ "U_T6_MCA_MY2020_Rx" SG_ 360 TrnGearPwmFalt_B_Actl 1;
BA_ "U_CD542_MY2021_Rx" SG_ 360 TrnGearPwmFalt_B_Actl 1;
BA_ "U_U55X_MY2022_Rx" SG_ 360 TrnGearPwmFalt_B_Actl 1;
BA_ "U_CD764_MY2022_Rx" SG_ 360 TrnGearPwmFalt_B_Actl 1;
BA_ "U_CDX706_MY2023_Rx" SG_ 360 TrnGearPwmFalt_B_Actl 1;
BA_ "ContentDependant" SG_ 360 GearButtnStuck_B_Actl 1;
BA_ "U_CX727_MY2021_Rx" SG_ 360 GearButtnStuck_B_Actl 1;
BA_ "U_P702_MY2021_Rx" SG_ 360 GearButtnStuck_B_Actl 1;
BA_ "U_T6_MCA_MY2020_Rx" SG_ 360 GearButtnStuck_B_Actl 1;
BA_ "U_CD542_MY2021_Rx" SG_ 360 GearButtnStuck_B_Actl 1;
BA_ "U_U55X_MY2022_Rx" SG_ 360 GearButtnStuck_B_Actl 1;
BA_ "U_CD764_MY2022_Rx" SG_ 360 GearButtnStuck_B_Actl 1;
BA_ "U_CDX706_MY2023_Rx" SG_ 360 GearButtnStuck_B_Actl 1;
BA_ "MetaData" SG_ 331 TrnAout2ActUflt_No_Cnt 1;
BA_ "MetaData" SG_ 331 TrnAout2ActlUflt_No_Cs 1;
BA_ "GenSigStartValueInteger" SG_ 331 TrnAout2_W_ActlUnfilt 65534;
BA_ "GenSigStartValue" SG_ 331 TrnAout2_W_ActlUnfilt 65534;
BA_ "U_CDX706_MY2023_Tx" SG_ 331 TrnAout2_W_ActlUnfilt 1;
BA_ "U_CD542_MY2021_Rx" SG_ 331 CmbbEngTqMn_B_ActlHtrn 1;
BA_ "U_CX727_MY2021_Tx" SG_ 331 CmbbEngTqMn_B_ActlHtrn 1;
BA_ "U_CD542_MY2021_Tx" SG_ 331 CmbbEngTqMn_B_ActlHtrn 1;
BA_ "U_CDX706_MY2023_Tx" SG_ 331 CmbbEngTqMn_B_ActlHtrn 1;
BA_ "U_CD542_MY2021_Rx" SG_ 331 CmbbDeny_B_ActlHtrn 1;
BA_ "U_CX727_MY2021_Tx" SG_ 331 CmbbDeny_B_ActlHtrn 1;
BA_ "U_CD542_MY2021_Tx" SG_ 331 CmbbDeny_B_ActlHtrn 1;
BA_ "U_CDX706_MY2023_Tx" SG_ 331 CmbbDeny_B_ActlHtrn 1;
BA_ "U_CDX706_MY2023_Rx" SG_ 140 DcacPwResetBttn_D_Stat 1;
BA_ "GenSigStartValueInteger" SG_ 122 BattTrac_U_LimLo 88;
BA_ "GenSigStartValue" SG_ 122 BattTrac_U_LimLo 88;
BA_ "U_CX727_MY2021_Rx" SG_ 122 BattTrac_U_LimLo 1;
BA_ "U_P702_MY2021_Rx" SG_ 122 BattTrac_U_LimLo 1;
BA_ "U_CD542_MY2021_Rx" SG_ 122 BattTrac_U_LimLo 1;
BA_ "U_CDX706_MY2023_Rx" SG_ 122 BattTrac_U_LimLo 1;
BA_ "GenSigStartValueInteger" SG_ 122 BattTrac_U_LimHi 163;
BA_ "GenSigStartValue" SG_ 122 BattTrac_U_LimHi 163;
BA_ "U_CX727_MY2021_Rx" SG_ 122 BattTrac_U_LimHi 1;
BA_ "U_P702_MY2021_Rx" SG_ 122 BattTrac_U_LimHi 1;
BA_ "U_CD542_MY2021_Rx" SG_ 122 BattTrac_U_LimHi 1;
BA_ "U_CDX706_MY2023_Rx" SG_ 122 BattTrac_U_LimHi 1;
BA_ "U_CX727_MY2021_Rx" SG_ 122 VehStrtInhbt_B_RqBatt 1;
BA_ "U_P702_MY2021_Rx" SG_ 122 VehStrtInhbt_B_RqBatt 1;
BA_ "U_CD542_MY2021_Rx" SG_ 122 VehStrtInhbt_B_RqBatt 1;
BA_ "U_CDX706_MY2023_Rx" SG_ 122 VehStrtInhbt_B_RqBatt 1;
BA_ "U_CX727_MY2021_Rx" SG_ 122 BattTracOffFst_D_Actl 1;
BA_ "U_P702_MY2021_Rx" SG_ 122 BattTracOffFst_D_Actl 1;
BA_ "U_CD542_MY2021_Rx" SG_ 122 BattTracOffFst_D_Actl 1;
BA_ "U_CDX706_MY2023_Rx" SG_ 122 BattTracOffFst_D_Actl 1;
BA_ "U_CX727_MY2021_Rx" SG_ 122 BattTracOff_B_Actl 1;
BA_ "U_P702_MY2021_Rx" SG_ 122 BattTracOff_B_Actl 1;
BA_ "U_CD542_MY2021_Rx" SG_ 122 BattTracOff_B_Actl 1;
BA_ "U_CDX706_MY2023_Rx" SG_ 122 BattTracOff_B_Actl 1;
BA_ "U_CX727_MY2021_Rx" SG_ 122 BattTracMil_D_Rq 1;
BA_ "U_CD542_MY2021_Rx" SG_ 122 BattTracMil_D_Rq 1;
BA_ "U_CDX706_MY2023_Rx" SG_ 122 BattTracMil_D_Rq 1;
BA_ "U_CX727_MY2021_Rx" SG_ 122 BattTracCnnct_B_Cmd 1;
BA_ "U_CDX706_MY2023_Rx" SG_ 122 BattTracCnnct_B_Cmd 1;
BA_ "GenSigStartValueInteger" SG_ 122 BattTrac_U_Actl 1022;
BA_ "GenSigStartValue" SG_ 122 BattTrac_U_Actl 1022;
BA_ "U_CX727_MY2021_Rx" SG_ 122 BattTrac_U_Actl 1;
BA_ "U_P702_MY2021_Rx" SG_ 122 BattTrac_U_Actl 1;
BA_ "U_CD542_MY2021_Rx" SG_ 122 BattTrac_U_Actl 1;
BA_ "U_CDX706_MY2023_Rx" SG_ 122 BattTrac_U_Actl 1;
BA_ "GenSigStartValueInteger" SG_ 122 BattTrac_I_Actl 15000;
BA_ "U_CX727_MY2021_Rx" SG_ 122 BattTrac_I_Actl 1;
BA_ "U_P702_MY2021_Rx" SG_ 122 BattTrac_I_Actl 1;
BA_ "U_CD542_MY2021_Rx" SG_ 122 BattTrac_I_Actl 1;
BA_ "U_CDX706_MY2023_Rx" SG_ 122 BattTrac_I_Actl 1;
BA_ "ContentDependant" SG_ 93 TrnTrcmNtmState_D_Actl 1;
BA_ "ContentDependant" SG_ 93 TrnSns2Pos_Pc_Actl 1;
BA_ "ContentDependant" SG_ 93 TrnSns1Pos_Pc_Actl 1;
BA_ "ContentDependant" SG_ 93 TrnSecPrkStat_D_Actl 1;
BA_ "ContentDependant" SG_ 93 TrnNtrlTowCnfm_B_Actl 1;
BA_ "ContentDependant" SG_ 93 TrnGearFinalPos_B_Actl 1;
BA_ "ContentDependant" SG_ 93 TrnGearCnfm_No_Cs 1;
BA_ "MetaData" SG_ 93 TrnGearCnfm_No_Cs 1;
BA_ "ContentDependant" SG_ 93 TrnGearCnfm_No_Cnt 1;
BA_ "MetaData" SG_ 93 TrnGearCnfm_No_Cnt 1;
BA_ "ContentDependant" SG_ 93 TrnGear_D_Actl 1;
BA_ "ContentDependant" SG_ 90 TrnGsmNtmState_D_Actl 1;
BA_ "U_CX727_MY2021_Rx" SG_ 90 TrnGsmNtmState_D_Actl 1;
BA_ "U_P702_MY2021_Rx" SG_ 90 TrnGsmNtmState_D_Actl 1;
BA_ "U_T6_MCA_MY2020_Rx" SG_ 90 TrnGsmNtmState_D_Actl 1;
BA_ "U_CD542_MY2021_Rx" SG_ 90 TrnGsmNtmState_D_Actl 1;
BA_ "U_U55X_MY2022_Rx" SG_ 90 TrnGsmNtmState_D_Actl 1;
BA_ "U_CD764_MY2022_Rx" SG_ 90 TrnGsmNtmState_D_Actl 1;
BA_ "U_CDX706_MY2023_Rx" SG_ 90 TrnGsmNtmState_D_Actl 1;
BA_ "GenSigStartValueInteger" SG_ 90 DrQltyDrv_D_StatGsm 6;
BA_ "ContentDependant" SG_ 90 DrQltyDrv_D_StatGsm 1;
BA_ "GenSigStartValue" SG_ 90 DrQltyDrv_D_StatGsm 6;
BA_ "U_CX727_MY2021_Rx" SG_ 90 DrQltyDrv_D_StatGsm 1;
BA_ "U_P702_MY2021_Rx" SG_ 90 DrQltyDrv_D_StatGsm 1;
BA_ "U_T6_MCA_MY2020_Rx" SG_ 90 DrQltyDrv_D_StatGsm 1;
BA_ "U_CD542_MY2021_Rx" SG_ 90 DrQltyDrv_D_StatGsm 1;
BA_ "U_U55X_MY2022_Rx" SG_ 90 DrQltyDrv_D_StatGsm 1;
BA_ "U_CD764_MY2022_Rx" SG_ 90 DrQltyDrv_D_StatGsm 1;
BA_ "U_CDX706_MY2023_Rx" SG_ 90 DrQltyDrv_D_StatGsm 1;
BA_ "ContentDependant" SG_ 90 TrnBtsiOvrrd_B_Stat 1;
BA_ "U_CX727_MY2021_Rx" SG_ 90 TrnBtsiOvrrd_B_Stat 1;
BA_ "U_P702_MY2021_Rx" SG_ 90 TrnBtsiOvrrd_B_Stat 1;
BA_ "U_T6_MCA_MY2020_Rx" SG_ 90 TrnBtsiOvrrd_B_Stat 1;
BA_ "U_CD542_MY2021_Rx" SG_ 90 TrnBtsiOvrrd_B_Stat 1;
BA_ "U_U55X_MY2022_Rx" SG_ 90 TrnBtsiOvrrd_B_Stat 1;
BA_ "U_CD764_MY2022_Rx" SG_ 90 TrnBtsiOvrrd_B_Stat 1;
BA_ "U_CDX706_MY2023_Rx" SG_ 90 TrnBtsiOvrrd_B_Stat 1;
BA_ "U_CX727_MY2021_Rx" SG_ 90 GsmGearMsgTxt_D_Rq 1;
BA_ "U_CD542_MY2021_Rx" SG_ 90 GsmGearMsgTxt_D_Rq 1;
BA_ "U_CDX706_MY2023_Rx" SG_ 90 GsmGearMsgTxt_D_Rq 1;
BA_ "GenSigStartValueInteger" SG_ 90 TrnRng_D_RqGsm 14;
BA_ "GenSigStartValue" SG_ 90 TrnRng_D_RqGsm 14;
BA_ "U_CX727_MY2021_Rx" SG_ 90 TrnRng_D_RqGsm 1;
BA_ "U_P702_MY2021_Rx" SG_ 90 TrnRng_D_RqGsm 1;
BA_ "U_T6_MCA_MY2020_Rx" SG_ 90 TrnRng_D_RqGsm 1;
BA_ "U_CD542_MY2021_Rx" SG_ 90 TrnRng_D_RqGsm 1;
BA_ "U_U55X_MY2022_Rx" SG_ 90 TrnRng_D_RqGsm 1;
BA_ "U_CD764_MY2022_Rx" SG_ 90 TrnRng_D_RqGsm 1;
BA_ "U_CDX706_MY2023_Rx" SG_ 90 TrnRng_D_RqGsm 1;
BA_ "U_CX727_MY2021_Rx" SG_ 90 PrkBrkActv_D_RqGsmGear 1;
BA_ "U_P702_MY2021_Rx" SG_ 90 PrkBrkActv_D_RqGsmGear 1;
BA_ "U_T6_MCA_MY2020_Rx" SG_ 90 PrkBrkActv_D_RqGsmGear 1;
BA_ "U_CD542_MY2021_Rx" SG_ 90 PrkBrkActv_D_RqGsmGear 1;
BA_ "U_U55X_MY2022_Rx" SG_ 90 PrkBrkActv_D_RqGsmGear 1;
BA_ "U_CD764_MY2022_Rx" SG_ 90 PrkBrkActv_D_RqGsmGear 1;
BA_ "U_CDX706_MY2023_Rx" SG_ 90 PrkBrkActv_D_RqGsmGear 1;
BA_ "ContentDependant" SG_ 90 TrnValidGearRq_D_Stat 1;
BA_ "U_CX727_MY2021_Rx" SG_ 90 TrnValidGearRq_D_Stat 1;
BA_ "U_P702_MY2021_Rx" SG_ 90 TrnValidGearRq_D_Stat 1;
BA_ "U_T6_MCA_MY2020_Rx" SG_ 90 TrnValidGearRq_D_Stat 1;
BA_ "U_CD542_MY2021_Rx" SG_ 90 TrnValidGearRq_D_Stat 1;
BA_ "U_U55X_MY2022_Rx" SG_ 90 TrnValidGearRq_D_Stat 1;
BA_ "U_CD764_MY2022_Rx" SG_ 90 TrnValidGearRq_D_Stat 1;
BA_ "U_CDX706_MY2023_Rx" SG_ 90 TrnValidGearRq_D_Stat 1;
BA_ "ContentDependant" SG_ 90 TrnGearRqCnt_B_Actl 1;
BA_ "U_CX727_MY2021_Rx" SG_ 90 TrnGearRqCnt_B_Actl 1;
BA_ "U_P702_MY2021_Rx" SG_ 90 TrnGearRqCnt_B_Actl 1;
BA_ "U_T6_MCA_MY2020_Rx" SG_ 90 TrnGearRqCnt_B_Actl 1;
BA_ "U_CD542_MY2021_Rx" SG_ 90 TrnGearRqCnt_B_Actl 1;
BA_ "U_U55X_MY2022_Rx" SG_ 90 TrnGearRqCnt_B_Actl 1;
BA_ "U_CD764_MY2022_Rx" SG_ 90 TrnGearRqCnt_B_Actl 1;
BA_ "U_CDX706_MY2023_Rx" SG_ 90 TrnGearRqCnt_B_Actl 1;
BA_ "WakeupSignal" SG_ 90 TrnGearButtn_U_Actl 1;
BA_ "ContentDependant" SG_ 90 TrnGearButtn_U_Actl 1;
BA_ "U_CX727_MY2021_Rx" SG_ 90 TrnGearButtn_U_Actl 1;
BA_ "U_P702_MY2021_Rx" SG_ 90 TrnGearButtn_U_Actl 1;
BA_ "U_T6_MCA_MY2020_Rx" SG_ 90 TrnGearButtn_U_Actl 1;
BA_ "U_CD542_MY2021_Rx" SG_ 90 TrnGearButtn_U_Actl 1;
BA_ "U_CDX706_MY2023_Rx" SG_ 90 TrnGearButtn_U_Actl 1;
BA_ "WakeupSignal" SG_ 90 TrnGearButtn_B_ActlR2 1;
BA_ "ContentDependant" SG_ 90 TrnGearButtn_B_ActlR2 1;
BA_ "U_CX727_MY2021_Rx" SG_ 90 TrnGearButtn_B_ActlR2 1;
BA_ "U_P702_MY2021_Rx" SG_ 90 TrnGearButtn_B_ActlR2 1;
BA_ "U_T6_MCA_MY2020_Rx" SG_ 90 TrnGearButtn_B_ActlR2 1;
BA_ "U_CD542_MY2021_Rx" SG_ 90 TrnGearButtn_B_ActlR2 1;
BA_ "U_U55X_MY2022_Rx" SG_ 90 TrnGearButtn_B_ActlR2 1;
BA_ "U_CD764_MY2022_Rx" SG_ 90 TrnGearButtn_B_ActlR2 1;
BA_ "U_CDX706_MY2023_Rx" SG_ 90 TrnGearButtn_B_ActlR2 1;
BA_ "WakeupSignal" SG_ 90 TrnGearButtn_B_ActlR1 1;
BA_ "ContentDependant" SG_ 90 TrnGearButtn_B_ActlR1 1;
BA_ "U_CX727_MY2021_Rx" SG_ 90 TrnGearButtn_B_ActlR1 1;
BA_ "U_P702_MY2021_Rx" SG_ 90 TrnGearButtn_B_ActlR1 1;
BA_ "U_T6_MCA_MY2020_Rx" SG_ 90 TrnGearButtn_B_ActlR1 1;
BA_ "U_CD542_MY2021_Rx" SG_ 90 TrnGearButtn_B_ActlR1 1;
BA_ "U_U55X_MY2022_Rx" SG_ 90 TrnGearButtn_B_ActlR1 1;
BA_ "U_CD764_MY2022_Rx" SG_ 90 TrnGearButtn_B_ActlR1 1;
BA_ "U_CDX706_MY2023_Rx" SG_ 90 TrnGearButtn_B_ActlR1 1;
BA_ "WakeupSignal" SG_ 90 TrnGearButtn_B_ActlR0 1;
BA_ "ContentDependant" SG_ 90 TrnGearButtn_B_ActlR0 1;
BA_ "U_CX727_MY2021_Rx" SG_ 90 TrnGearButtn_B_ActlR0 1;
BA_ "U_P702_MY2021_Rx" SG_ 90 TrnGearButtn_B_ActlR0 1;
BA_ "U_T6_MCA_MY2020_Rx" SG_ 90 TrnGearButtn_B_ActlR0 1;
BA_ "U_CD542_MY2021_Rx" SG_ 90 TrnGearButtn_B_ActlR0 1;
BA_ "U_U55X_MY2022_Rx" SG_ 90 TrnGearButtn_B_ActlR0 1;
BA_ "U_CD764_MY2022_Rx" SG_ 90 TrnGearButtn_B_ActlR0 1;
BA_ "U_CDX706_MY2023_Rx" SG_ 90 TrnGearButtn_B_ActlR0 1;
BA_ "WakeupSignal" SG_ 90 TrnGearButtn_B_ActlP2 1;
BA_ "ContentDependant" SG_ 90 TrnGearButtn_B_ActlP2 1;
BA_ "U_CX727_MY2021_Rx" SG_ 90 TrnGearButtn_B_ActlP2 1;
BA_ "U_P702_MY2021_Rx" SG_ 90 TrnGearButtn_B_ActlP2 1;
BA_ "U_T6_MCA_MY2020_Rx" SG_ 90 TrnGearButtn_B_ActlP2 1;
BA_ "U_CD542_MY2021_Rx" SG_ 90 TrnGearButtn_B_ActlP2 1;
BA_ "U_U55X_MY2022_Rx" SG_ 90 TrnGearButtn_B_ActlP2 1;
BA_ "U_CD764_MY2022_Rx" SG_ 90 TrnGearButtn_B_ActlP2 1;
BA_ "U_CDX706_MY2023_Rx" SG_ 90 TrnGearButtn_B_ActlP2 1;
BA_ "WakeupSignal" SG_ 90 TrnGearButtn_B_ActlP1 1;
BA_ "ContentDependant" SG_ 90 TrnGearButtn_B_ActlP1 1;
BA_ "U_CX727_MY2021_Rx" SG_ 90 TrnGearButtn_B_ActlP1 1;
BA_ "U_P702_MY2021_Rx" SG_ 90 TrnGearButtn_B_ActlP1 1;
BA_ "U_T6_MCA_MY2020_Rx" SG_ 90 TrnGearButtn_B_ActlP1 1;
BA_ "U_CD542_MY2021_Rx" SG_ 90 TrnGearButtn_B_ActlP1 1;
BA_ "U_U55X_MY2022_Rx" SG_ 90 TrnGearButtn_B_ActlP1 1;
BA_ "U_CD764_MY2022_Rx" SG_ 90 TrnGearButtn_B_ActlP1 1;
BA_ "U_CDX706_MY2023_Rx" SG_ 90 TrnGearButtn_B_ActlP1 1;
BA_ "WakeupSignal" SG_ 90 TrnGearButtn_B_ActlP0 1;
BA_ "ContentDependant" SG_ 90 TrnGearButtn_B_ActlP0 1;
BA_ "U_CX727_MY2021_Rx" SG_ 90 TrnGearButtn_B_ActlP0 1;
BA_ "U_P702_MY2021_Rx" SG_ 90 TrnGearButtn_B_ActlP0 1;
BA_ "U_T6_MCA_MY2020_Rx" SG_ 90 TrnGearButtn_B_ActlP0 1;
BA_ "U_CD542_MY2021_Rx" SG_ 90 TrnGearButtn_B_ActlP0 1;
BA_ "U_U55X_MY2022_Rx" SG_ 90 TrnGearButtn_B_ActlP0 1;
BA_ "U_CD764_MY2022_Rx" SG_ 90 TrnGearButtn_B_ActlP0 1;
BA_ "U_CDX706_MY2023_Rx" SG_ 90 TrnGearButtn_B_ActlP0 1;
BA_ "WakeupSignal" SG_ 90 TrnGearButtn_B_ActlN2 1;
BA_ "ContentDependant" SG_ 90 TrnGearButtn_B_ActlN2 1;
BA_ "U_CX727_MY2021_Rx" SG_ 90 TrnGearButtn_B_ActlN2 1;
BA_ "U_P702_MY2021_Rx" SG_ 90 TrnGearButtn_B_ActlN2 1;
BA_ "U_T6_MCA_MY2020_Rx" SG_ 90 TrnGearButtn_B_ActlN2 1;
BA_ "U_CD542_MY2021_Rx" SG_ 90 TrnGearButtn_B_ActlN2 1;
BA_ "U_U55X_MY2022_Rx" SG_ 90 TrnGearButtn_B_ActlN2 1;
BA_ "U_CD764_MY2022_Rx" SG_ 90 TrnGearButtn_B_ActlN2 1;
BA_ "U_CDX706_MY2023_Rx" SG_ 90 TrnGearButtn_B_ActlN2 1;
BA_ "WakeupSignal" SG_ 90 TrnGearButtn_B_ActlN1 1;
BA_ "ContentDependant" SG_ 90 TrnGearButtn_B_ActlN1 1;
BA_ "U_CX727_MY2021_Rx" SG_ 90 TrnGearButtn_B_ActlN1 1;
BA_ "U_P702_MY2021_Rx" SG_ 90 TrnGearButtn_B_ActlN1 1;
BA_ "U_T6_MCA_MY2020_Rx" SG_ 90 TrnGearButtn_B_ActlN1 1;
BA_ "U_CD542_MY2021_Rx" SG_ 90 TrnGearButtn_B_ActlN1 1;
BA_ "U_U55X_MY2022_Rx" SG_ 90 TrnGearButtn_B_ActlN1 1;
BA_ "U_CD764_MY2022_Rx" SG_ 90 TrnGearButtn_B_ActlN1 1;
BA_ "U_CDX706_MY2023_Rx" SG_ 90 TrnGearButtn_B_ActlN1 1;
BA_ "WakeupSignal" SG_ 90 TrnGearButtn_B_ActlN0 1;
BA_ "ContentDependant" SG_ 90 TrnGearButtn_B_ActlN0 1;
BA_ "U_CX727_MY2021_Rx" SG_ 90 TrnGearButtn_B_ActlN0 1;
BA_ "U_P702_MY2021_Rx" SG_ 90 TrnGearButtn_B_ActlN0 1;
BA_ "U_T6_MCA_MY2020_Rx" SG_ 90 TrnGearButtn_B_ActlN0 1;
BA_ "U_CD542_MY2021_Rx" SG_ 90 TrnGearButtn_B_ActlN0 1;
BA_ "U_U55X_MY2022_Rx" SG_ 90 TrnGearButtn_B_ActlN0 1;
BA_ "U_CD764_MY2022_Rx" SG_ 90 TrnGearButtn_B_ActlN0 1;
BA_ "U_CDX706_MY2023_Rx" SG_ 90 TrnGearButtn_B_ActlN0 1;
BA_ "WakeupSignal" SG_ 90 TrnGearButtn_B_ActlM2 1;
BA_ "ContentDependant" SG_ 90 TrnGearButtn_B_ActlM2 1;
BA_ "U_CX727_MY2021_Rx" SG_ 90 TrnGearButtn_B_ActlM2 1;
BA_ "U_P702_MY2021_Rx" SG_ 90 TrnGearButtn_B_ActlM2 1;
BA_ "U_T6_MCA_MY2020_Rx" SG_ 90 TrnGearButtn_B_ActlM2 1;
BA_ "U_CD542_MY2021_Rx" SG_ 90 TrnGearButtn_B_ActlM2 1;
BA_ "U_U55X_MY2022_Rx" SG_ 90 TrnGearButtn_B_ActlM2 1;
BA_ "U_CD764_MY2022_Rx" SG_ 90 TrnGearButtn_B_ActlM2 1;
BA_ "U_CDX706_MY2023_Rx" SG_ 90 TrnGearButtn_B_ActlM2 1;
BA_ "WakeupSignal" SG_ 90 TrnGearButtn_B_ActlM1 1;
BA_ "ContentDependant" SG_ 90 TrnGearButtn_B_ActlM1 1;
BA_ "U_CX727_MY2021_Rx" SG_ 90 TrnGearButtn_B_ActlM1 1;
BA_ "U_P702_MY2021_Rx" SG_ 90 TrnGearButtn_B_ActlM1 1;
BA_ "U_T6_MCA_MY2020_Rx" SG_ 90 TrnGearButtn_B_ActlM1 1;
BA_ "U_CD542_MY2021_Rx" SG_ 90 TrnGearButtn_B_ActlM1 1;
BA_ "U_U55X_MY2022_Rx" SG_ 90 TrnGearButtn_B_ActlM1 1;
BA_ "U_CD764_MY2022_Rx" SG_ 90 TrnGearButtn_B_ActlM1 1;
BA_ "U_CDX706_MY2023_Rx" SG_ 90 TrnGearButtn_B_ActlM1 1;
BA_ "WakeupSignal" SG_ 90 TrnGearButtn_B_ActlM0 1;
BA_ "ContentDependant" SG_ 90 TrnGearButtn_B_ActlM0 1;
BA_ "U_CX727_MY2021_Rx" SG_ 90 TrnGearButtn_B_ActlM0 1;
BA_ "U_P702_MY2021_Rx" SG_ 90 TrnGearButtn_B_ActlM0 1;
BA_ "U_T6_MCA_MY2020_Rx" SG_ 90 TrnGearButtn_B_ActlM0 1;
BA_ "U_CD542_MY2021_Rx" SG_ 90 TrnGearButtn_B_ActlM0 1;
BA_ "U_U55X_MY2022_Rx" SG_ 90 TrnGearButtn_B_ActlM0 1;
BA_ "U_CD764_MY2022_Rx" SG_ 90 TrnGearButtn_B_ActlM0 1;
BA_ "U_CDX706_MY2023_Rx" SG_ 90 TrnGearButtn_B_ActlM0 1;
BA_ "WakeupSignal" SG_ 90 TrnGearButtn_B_ActlD2 1;
BA_ "ContentDependant" SG_ 90 TrnGearButtn_B_ActlD2 1;
BA_ "U_CX727_MY2021_Rx" SG_ 90 TrnGearButtn_B_ActlD2 1;
BA_ "U_P702_MY2021_Rx" SG_ 90 TrnGearButtn_B_ActlD2 1;
BA_ "U_T6_MCA_MY2020_Rx" SG_ 90 TrnGearButtn_B_ActlD2 1;
BA_ "U_CD542_MY2021_Rx" SG_ 90 TrnGearButtn_B_ActlD2 1;
BA_ "U_U55X_MY2022_Rx" SG_ 90 TrnGearButtn_B_ActlD2 1;
BA_ "U_CD764_MY2022_Rx" SG_ 90 TrnGearButtn_B_ActlD2 1;
BA_ "U_CDX706_MY2023_Rx" SG_ 90 TrnGearButtn_B_ActlD2 1;
BA_ "WakeupSignal" SG_ 90 TrnGearButtn_B_ActlD1 1;
BA_ "ContentDependant" SG_ 90 TrnGearButtn_B_ActlD1 1;
BA_ "U_CX727_MY2021_Rx" SG_ 90 TrnGearButtn_B_ActlD1 1;
BA_ "U_P702_MY2021_Rx" SG_ 90 TrnGearButtn_B_ActlD1 1;
BA_ "U_T6_MCA_MY2020_Rx" SG_ 90 TrnGearButtn_B_ActlD1 1;
BA_ "U_CD542_MY2021_Rx" SG_ 90 TrnGearButtn_B_ActlD1 1;
BA_ "U_U55X_MY2022_Rx" SG_ 90 TrnGearButtn_B_ActlD1 1;
BA_ "U_CD764_MY2022_Rx" SG_ 90 TrnGearButtn_B_ActlD1 1;
BA_ "U_CDX706_MY2023_Rx" SG_ 90 TrnGearButtn_B_ActlD1 1;
BA_ "WakeupSignal" SG_ 90 TrnGearButtn_B_ActlD0 1;
BA_ "ContentDependant" SG_ 90 TrnGearButtn_B_ActlD0 1;
BA_ "U_CX727_MY2021_Rx" SG_ 90 TrnGearButtn_B_ActlD0 1;
BA_ "U_P702_MY2021_Rx" SG_ 90 TrnGearButtn_B_ActlD0 1;
BA_ "U_T6_MCA_MY2020_Rx" SG_ 90 TrnGearButtn_B_ActlD0 1;
BA_ "U_CD542_MY2021_Rx" SG_ 90 TrnGearButtn_B_ActlD0 1;
BA_ "U_U55X_MY2022_Rx" SG_ 90 TrnGearButtn_B_ActlD0 1;
BA_ "U_CD764_MY2022_Rx" SG_ 90 TrnGearButtn_B_ActlD0 1;
BA_ "U_CDX706_MY2023_Rx" SG_ 90 TrnGearButtn_B_ActlD0 1;
BA_ "ContentDependant" SG_ 90 TrnGear_No_Cs 1;
BA_ "MetaData" SG_ 90 TrnGear_No_Cs 1;
BA_ "U_CX727_MY2021_Rx" SG_ 90 TrnGear_No_Cs 1;
BA_ "U_P702_MY2021_Rx" SG_ 90 TrnGear_No_Cs 1;
BA_ "U_T6_MCA_MY2020_Rx" SG_ 90 TrnGear_No_Cs 1;
BA_ "U_CD542_MY2021_Rx" SG_ 90 TrnGear_No_Cs 1;
BA_ "U_U55X_MY2022_Rx" SG_ 90 TrnGear_No_Cs 1;
BA_ "U_CD764_MY2022_Rx" SG_ 90 TrnGear_No_Cs 1;
BA_ "U_CDX706_MY2023_Rx" SG_ 90 TrnGear_No_Cs 1;
BA_ "ContentDependant" SG_ 90 TrnGear_No_Cnt 1;
BA_ "MetaData" SG_ 90 TrnGear_No_Cnt 1;
BA_ "U_CX727_MY2021_Rx" SG_ 90 TrnGear_No_Cnt 1;
BA_ "U_P702_MY2021_Rx" SG_ 90 TrnGear_No_Cnt 1;
BA_ "U_T6_MCA_MY2020_Rx" SG_ 90 TrnGear_No_Cnt 1;
BA_ "U_CD542_MY2021_Rx" SG_ 90 TrnGear_No_Cnt 1;
BA_ "U_U55X_MY2022_Rx" SG_ 90 TrnGear_No_Cnt 1;
BA_ "U_CD764_MY2022_Rx" SG_ 90 TrnGear_No_Cnt 1;
BA_ "U_CDX706_MY2023_Rx" SG_ 90 TrnGear_No_Cnt 1;
BA_ "WakeupSignal" SG_ 90 TrnGear_D_RqDrv 1;
BA_ "ContentDependant" SG_ 90 TrnGear_D_RqDrv 1;
BA_ "U_CX727_MY2021_Rx" SG_ 90 TrnGear_D_RqDrv 1;
BA_ "U_P702_MY2021_Rx" SG_ 90 TrnGear_D_RqDrv 1;
BA_ "U_T6_MCA_MY2020_Rx" SG_ 90 TrnGear_D_RqDrv 1;
BA_ "U_CD542_MY2021_Rx" SG_ 90 TrnGear_D_RqDrv 1;
BA_ "U_U55X_MY2022_Rx" SG_ 90 TrnGear_D_RqDrv 1;
BA_ "U_CD764_MY2022_Rx" SG_ 90 TrnGear_D_RqDrv 1;
BA_ "U_CDX706_MY2023_Rx" SG_ 90 TrnGear_D_RqDrv 1;
BA_ "ContentDependant" SG_ 90 BrkSwtchPos_B_ActlGsm 1;
BA_ "U_CX727_MY2021_Rx" SG_ 90 BrkSwtchPos_B_ActlGsm 1;
BA_ "U_P702_MY2021_Rx" SG_ 90 BrkSwtchPos_B_ActlGsm 1;
BA_ "U_T6_MCA_MY2020_Rx" SG_ 90 BrkSwtchPos_B_ActlGsm 1;
BA_ "U_CD542_MY2021_Rx" SG_ 90 BrkSwtchPos_B_ActlGsm 1;
BA_ "U_U55X_MY2022_Rx" SG_ 90 BrkSwtchPos_B_ActlGsm 1;
BA_ "U_CD764_MY2022_Rx" SG_ 90 BrkSwtchPos_B_ActlGsm 1;
BA_ "U_CDX706_MY2023_Rx" SG_ 90 BrkSwtchPos_B_ActlGsm 1;
BA_ "U_P702_MY2021_Rx" SG_ 1114 TrailCtlSwtch_B_Stat2 1;
BA_ "U_U55X_MY2022_Rx" SG_ 1114 TrailCtlSwtch_B_Stat2 1;
BA_ "GenSigStartValueInteger" SG_ 1111 TrlrYawWActl_D_Qf 1;
BA_ "MetaData" SG_ 1111 TrlrYawWActl_D_Qf 1;
BA_ "GenSigStartValue" SG_ 1111 TrlrYawWActl_D_Qf 1;
BA_ "U_P702_MY2021_Rx" SG_ 1111 TrlrYawWActl_D_Qf 1;
BA_ "U_T6_MCA_MY2020_Rx" SG_ 1111 TrlrYawWActl_D_Qf 1;
BA_ "U_U55X_MY2022_Rx" SG_ 1111 TrlrYawWActl_D_Qf 1;
BA_ "U_CDX706_MY2023_Rx" SG_ 1111 TrlrYawWActl_D_Qf 1;
BA_ "GenSigStartValueInteger" SG_ 1111 TrlrYaw_W_Actl 65534;
BA_ "GenSigStartValue" SG_ 1111 TrlrYaw_W_Actl 65534;
BA_ "U_P702_MY2021_Rx" SG_ 1111 TrlrYaw_W_Actl 1;
BA_ "U_T6_MCA_MY2020_Rx" SG_ 1111 TrlrYaw_W_Actl 1;
BA_ "U_U55X_MY2022_Rx" SG_ 1111 TrlrYaw_W_Actl 1;
BA_ "U_CDX706_MY2023_Rx" SG_ 1111 TrlrYaw_W_Actl 1;
BA_ "GenSigStartValueInteger" SG_ 1111 TrlrHitYaw_AnRate_Actl 4094;
BA_ "GenSigStartValue" SG_ 1111 TrlrHitYaw_AnRate_Actl 4093;
BA_ "U_P702_MY2021_Rx" SG_ 1111 TrlrHitYaw_AnRate_Actl 1;
BA_ "U_T6_MCA_MY2020_Rx" SG_ 1111 TrlrHitYaw_AnRate_Actl 1;
BA_ "U_U55X_MY2022_Rx" SG_ 1111 TrlrHitYaw_AnRate_Actl 1;
BA_ "U_CDX706_MY2023_Rx" SG_ 1111 TrlrHitYaw_AnRate_Actl 1;
BA_ "U_P702_MY2021_Rx" SG_ 1111 TrlrHitchYaw_D_Stat 1;
BA_ "U_T6_MCA_MY2020_Rx" SG_ 1111 TrlrHitchYaw_D_Stat 1;
BA_ "U_U55X_MY2022_Rx" SG_ 1111 TrlrHitchYaw_D_Stat 1;
BA_ "U_CDX706_MY2023_Rx" SG_ 1111 TrlrHitchYaw_D_Stat 1;
BA_ "GenSigStartValueInteger" SG_ 1111 TrlrHitchYaw_An_Actl 4094;
BA_ "GenSigStartValue" SG_ 1111 TrlrHitchYaw_An_Actl 4093;
BA_ "U_P702_MY2021_Rx" SG_ 1111 TrlrHitchYaw_An_Actl 1;
BA_ "U_T6_MCA_MY2020_Rx" SG_ 1111 TrlrHitchYaw_An_Actl 1;
BA_ "U_U55X_MY2022_Rx" SG_ 1111 TrlrHitchYaw_An_Actl 1;
BA_ "U_CDX706_MY2023_Rx" SG_ 1111 TrlrHitchYaw_An_Actl 1;
BA_ "U_P702_MY2021_Rx" SG_ 1106 TrlrSnsId_No_Actl 1;
BA_ "U_T6_MCA_MY2020_Rx" SG_ 1106 TrlrSnsId_No_Actl 1;
BA_ "U_U55X_MY2022_Rx" SG_ 1106 TrlrSnsId_No_Actl 1;
BA_ "U_CDX706_MY2023_Rx" SG_ 1106 TrlrSnsId_No_Actl 1;
BA_ "ContentDependant" SG_ 1091 PoliceAux4Lamp_B_Rq2 1;
BA_ "ContentDependant" SG_ 1091 PoliceAux3Lamp_B_Rq2 1;
BA_ "ContentDependant" SG_ 1091 PoliceAux2Lamp_B_Rq2 1;
BA_ "ContentDependant" SG_ 1091 PoliceAux1Lamp_B_Rq2 1;
BA_ "U_CX727_MY2021_Rx" SG_ 1091 TrlrLampCnnct_B_Actl 1;
BA_ "U_P702_MY2021_Rx" SG_ 1091 TrlrLampCnnct_B_Actl 1;
BA_ "U_T6_MCA_MY2020_Rx" SG_ 1091 TrlrLampCnnct_B_Actl 1;
BA_ "U_CD542_MY2021_Rx" SG_ 1091 TrlrLampCnnct_B_Actl 1;
BA_ "U_U55X_MY2022_Rx" SG_ 1091 TrlrLampCnnct_B_Actl 1;
BA_ "U_CD764_MY2022_Rx" SG_ 1091 TrlrLampCnnct_B_Actl 1;
BA_ "U_CDX706_MY2023_Rx" SG_ 1091 TrlrLampCnnct_B_Actl 1;
BA_ "GenSigStartValueInteger" SG_ 1091 WakeAlarm2_T_Rq 32767;
BA_ "GenSigStartValue" SG_ 1091 WakeAlarm2_T_Rq 32767;
BA_ "U_P702_MY2021_Rx" SG_ 138 SteWhlRelCalib_T_Actl 1;
BA_ "ContentDependant" SG_ 138 SteWhlRelCalib_An_Sns 1;
BA_ "U_CX727_MY2021_Rx" SG_ 138 SteWhlRelCalib_An_Sns 1;
BA_ "U_P702_MY2021_Rx" SG_ 138 SteWhlRelCalib_An_Sns 1;
BA_ "U_T6_MCA_MY2020_Rx" SG_ 138 SteWhlRelCalib_An_Sns 1;
BA_ "U_CD542_MY2021_Rx" SG_ 138 SteWhlRelCalib_An_Sns 1;
BA_ "U_U55X_MY2022_Rx" SG_ 138 SteWhlRelCalib_An_Sns 1;
BA_ "U_CD764_MY2022_Rx" SG_ 138 SteWhlRelCalib_An_Sns 1;
BA_ "U_CDX706_MY2023_Rx" SG_ 138 SteWhlRelCalib_An_Sns 1;
BA_ "WakeupSignal" SG_ 131 HeadLghtHiCtrl_D_RqAhb 1;
BA_ "U_CX727_MY2021_Rx" SG_ 131 HeadLghtHiCtrl_D_RqAhb 1;
BA_ "U_P702_MY2021_Rx" SG_ 131 HeadLghtHiCtrl_D_RqAhb 1;
BA_ "U_U55X_MY2022_Rx" SG_ 131 HeadLghtHiCtrl_D_RqAhb 1;
BA_ "U_CD764_MY2022_Rx" SG_ 131 HeadLghtHiCtrl_D_RqAhb 1;
BA_ "GenSigStartValueInteger" SG_ 131 WiprFrontSwtch_D_Stat 9;
BA_ "GenSigStartValue" SG_ 131 WiprFrontSwtch_D_Stat 9;
BA_ "WakeupSignal" SG_ 131 HeadLghtHiOn_B_StatAhb 1;
BA_ "U_T6_MCA_MY2020_Rx" SG_ 131 HeadLghtHiOn_B_StatAhb 1;
BA_ "U_CD542_MY2021_Rx" SG_ 131 HeadLghtHiOn_B_StatAhb 1;
BA_ "U_U55X_MY2022_Rx" SG_ 131 HeadLghtHiOn_B_StatAhb 1;
BA_ "U_CD764_MY2022_Rx" SG_ 131 HeadLghtHiOn_B_StatAhb 1;
BA_ "U_CDX706_MY2023_Rx" SG_ 131 HeadLghtHiOn_B_StatAhb 1;
BA_ "U_T6_MCA_MY2020_Rx" SG_ 131 HeadLghtHiFlash_D_Actl 1;
BA_ "U_CD542_MY2021_Rx" SG_ 131 HeadLghtHiFlash_D_Actl 1;
BA_ "U_U55X_MY2022_Rx" SG_ 131 HeadLghtHiFlash_D_Actl 1;
BA_ "U_CD764_MY2022_Rx" SG_ 131 HeadLghtHiFlash_D_Actl 1;
BA_ "U_CDX706_MY2023_Rx" SG_ 131 HeadLghtHiFlash_D_Actl 1;
BA_ "U_T6_MCA_MY2020_Rx" SG_ 131 TjaButtnOnOffPress 1;
BA_ "U_CD542_MY2021_Rx" SG_ 131 TjaButtnOnOffPress 1;
BA_ "U_U55X_MY2022_Rx" SG_ 131 TjaButtnOnOffPress 1;
BA_ "U_CD764_MY2022_Rx" SG_ 131 TjaButtnOnOffPress 1;
BA_ "U_CDX706_MY2023_Rx" SG_ 131 TjaButtnOnOffPress 1;
BA_ "U_T6_MCA_MY2020_Rx" SG_ 131 AccButtnGapTogglePress 1;
BA_ "U_CD542_MY2021_Rx" SG_ 131 AccButtnGapTogglePress 1;
BA_ "U_U55X_MY2022_Rx" SG_ 131 AccButtnGapTogglePress 1;
BA_ "U_CD764_MY2022_Rx" SG_ 131 AccButtnGapTogglePress 1;
BA_ "U_CDX706_MY2023_Rx" SG_ 131 AccButtnGapTogglePress 1;
BA_ "GenSigStartValueInteger" SG_ 131 WiprFront_D_Stat 15;
BA_ "GenSigStartValue" SG_ 131 WiprFront_D_Stat 15;
BA_ "U_CX727_MY2021_Rx" SG_ 131 WiprFront_D_Stat 1;
BA_ "U_P702_MY2021_Rx" SG_ 131 WiprFront_D_Stat 1;
BA_ "U_T6_MCA_MY2020_Rx" SG_ 131 WiprFront_D_Stat 1;
BA_ "U_CD542_MY2021_Rx" SG_ 131 WiprFront_D_Stat 1;
BA_ "U_U55X_MY2022_Rx" SG_ 131 WiprFront_D_Stat 1;
BA_ "U_CD764_MY2022_Rx" SG_ 131 WiprFront_D_Stat 1;
BA_ "U_CDX706_MY2023_Rx" SG_ 131 WiprFront_D_Stat 1;
BA_ "WakeupSignal" SG_ 131 TurnLghtSwtch_D_Stat 1;
BA_ "U_CX727_MY2021_Rx" SG_ 131 TurnLghtSwtch_D_Stat 1;
BA_ "U_P702_MY2021_Rx" SG_ 131 TurnLghtSwtch_D_Stat 1;
BA_ "U_T6_MCA_MY2020_Rx" SG_ 131 TurnLghtSwtch_D_Stat 1;
BA_ "U_CD542_MY2021_Rx" SG_ 131 TurnLghtSwtch_D_Stat 1;
BA_ "U_U55X_MY2022_Rx" SG_ 131 TurnLghtSwtch_D_Stat 1;
BA_ "U_CD764_MY2022_Rx" SG_ 131 TurnLghtSwtch_D_Stat 1;
BA_ "U_CDX706_MY2023_Rx" SG_ 131 TurnLghtSwtch_D_Stat 1;
BA_ "GenSigStartValueInteger" SG_ 131 LghtAmb_D_Sns 7;
BA_ "GenSigStartValue" SG_ 131 LghtAmb_D_Sns 7;
BA_ "U_CX727_MY2021_Rx" SG_ 131 LghtAmb_D_Sns 1;
BA_ "U_P702_MY2021_Rx" SG_ 131 LghtAmb_D_Sns 1;
BA_ "U_T6_MCA_MY2020_Rx" SG_ 131 LghtAmb_D_Sns 1;
BA_ "U_CD542_MY2021_Rx" SG_ 131 LghtAmb_D_Sns 1;
BA_ "U_U55X_MY2022_Rx" SG_ 131 LghtAmb_D_Sns 1;
BA_ "U_CD764_MY2022_Rx" SG_ 131 LghtAmb_D_Sns 1;
BA_ "U_CDX706_MY2023_Rx" SG_ 131 LghtAmb_D_Sns 1;
BA_ "U_T6_MCA_MY2020_Rx" SG_ 131 AccButtnGapIncPress 1;
BA_ "U_CD542_MY2021_Rx" SG_ 131 AccButtnGapIncPress 1;
BA_ "U_U55X_MY2022_Rx" SG_ 131 AccButtnGapIncPress 1;
BA_ "U_CD764_MY2022_Rx" SG_ 131 AccButtnGapIncPress 1;
BA_ "U_CDX706_MY2023_Rx" SG_ 131 AccButtnGapIncPress 1;
BA_ "U_T6_MCA_MY2020_Rx" SG_ 131 AccButtnGapDecPress 1;
BA_ "U_CD542_MY2021_Rx" SG_ 131 AccButtnGapDecPress 1;
BA_ "U_U55X_MY2022_Rx" SG_ 131 AccButtnGapDecPress 1;
BA_ "U_CD764_MY2022_Rx" SG_ 131 AccButtnGapDecPress 1;
BA_ "U_CDX706_MY2023_Rx" SG_ 131 AccButtnGapDecPress 1;
BA_ "U_CX727_MY2021_Rx" SG_ 131 AslButtnOnOffPress 1;
BA_ "U_P702_MY2021_Rx" SG_ 131 AslButtnOnOffPress 1;
BA_ "U_T6_MCA_MY2020_Rx" SG_ 131 AslButtnOnOffPress 1;
BA_ "U_CD542_MY2021_Rx" SG_ 131 AslButtnOnOffPress 1;
BA_ "U_U55X_MY2022_Rx" SG_ 131 AslButtnOnOffPress 1;
BA_ "U_CD764_MY2022_Rx" SG_ 131 AslButtnOnOffPress 1;
BA_ "U_CDX706_MY2023_Rx" SG_ 131 AslButtnOnOffPress 1;
BA_ "U_CX727_MY2021_Rx" SG_ 131 AslButtnOnOffCnclPress 1;
BA_ "U_P702_MY2021_Rx" SG_ 131 AslButtnOnOffCnclPress 1;
BA_ "U_T6_MCA_MY2020_Rx" SG_ 131 AslButtnOnOffCnclPress 1;
BA_ "U_CD542_MY2021_Rx" SG_ 131 AslButtnOnOffCnclPress 1;
BA_ "U_U55X_MY2022_Rx" SG_ 131 AslButtnOnOffCnclPress 1;
BA_ "U_CD764_MY2022_Rx" SG_ 131 AslButtnOnOffCnclPress 1;
BA_ "U_CDX706_MY2023_Rx" SG_ 131 AslButtnOnOffCnclPress 1;
BA_ "U_CX727_MY2021_Rx" SG_ 131 CcButtnOnPress 1;
BA_ "U_P702_MY2021_Rx" SG_ 131 CcButtnOnPress 1;
BA_ "U_T6_MCA_MY2020_Rx" SG_ 131 CcButtnOnPress 1;
BA_ "U_CD542_MY2021_Rx" SG_ 131 CcButtnOnPress 1;
BA_ "U_U55X_MY2022_Rx" SG_ 131 CcButtnOnPress 1;
BA_ "U_CD764_MY2022_Rx" SG_ 131 CcButtnOnPress 1;
BA_ "U_CDX706_MY2023_Rx" SG_ 131 CcButtnOnPress 1;
BA_ "U_CX727_MY2021_Rx" SG_ 131 CcButtnOnOffPress 1;
BA_ "U_P702_MY2021_Rx" SG_ 131 CcButtnOnOffPress 1;
BA_ "U_T6_MCA_MY2020_Rx" SG_ 131 CcButtnOnOffPress 1;
BA_ "U_CD542_MY2021_Rx" SG_ 131 CcButtnOnOffPress 1;
BA_ "U_U55X_MY2022_Rx" SG_ 131 CcButtnOnOffPress 1;
BA_ "U_CD764_MY2022_Rx" SG_ 131 CcButtnOnOffPress 1;
BA_ "U_CDX706_MY2023_Rx" SG_ 131 CcButtnOnOffPress 1;
BA_ "U_CX727_MY2021_Rx" SG_ 131 CcButtnOnOffCnclPress 1;
BA_ "U_P702_MY2021_Rx" SG_ 131 CcButtnOnOffCnclPress 1;
BA_ "U_T6_MCA_MY2020_Rx" SG_ 131 CcButtnOnOffCnclPress 1;
BA_ "U_CD542_MY2021_Rx" SG_ 131 CcButtnOnOffCnclPress 1;
BA_ "U_U55X_MY2022_Rx" SG_ 131 CcButtnOnOffCnclPress 1;
BA_ "U_CD764_MY2022_Rx" SG_ 131 CcButtnOnOffCnclPress 1;
BA_ "U_CDX706_MY2023_Rx" SG_ 131 CcButtnOnOffCnclPress 1;
BA_ "U_CX727_MY2021_Rx" SG_ 131 CcButtnOffPress 1;
BA_ "U_P702_MY2021_Rx" SG_ 131 CcButtnOffPress 1;
BA_ "U_T6_MCA_MY2020_Rx" SG_ 131 CcButtnOffPress 1;
BA_ "U_CD542_MY2021_Rx" SG_ 131 CcButtnOffPress 1;
BA_ "U_U55X_MY2022_Rx" SG_ 131 CcButtnOffPress 1;
BA_ "U_CD764_MY2022_Rx" SG_ 131 CcButtnOffPress 1;
BA_ "U_CDX706_MY2023_Rx" SG_ 131 CcButtnOffPress 1;
BA_ "U_CX727_MY2021_Rx" SG_ 131 CcAsllButtnResPress 1;
BA_ "U_P702_MY2021_Rx" SG_ 131 CcAsllButtnResPress 1;
BA_ "U_T6_MCA_MY2020_Rx" SG_ 131 CcAsllButtnResPress 1;
BA_ "U_CD542_MY2021_Rx" SG_ 131 CcAsllButtnResPress 1;
BA_ "U_U55X_MY2022_Rx" SG_ 131 CcAsllButtnResPress 1;
BA_ "U_CD764_MY2022_Rx" SG_ 131 CcAsllButtnResPress 1;
BA_ "U_CDX706_MY2023_Rx" SG_ 131 CcAsllButtnResPress 1;
BA_ "U_CD542_MY2021_Rx" SG_ 131 CcAslButtnSetPress 1;
BA_ "U_CX727_MY2021_Rx" SG_ 131 CcAslButtnSetIncPress 1;
BA_ "U_P702_MY2021_Rx" SG_ 131 CcAslButtnSetIncPress 1;
BA_ "U_T6_MCA_MY2020_Rx" SG_ 131 CcAslButtnSetIncPress 1;
BA_ "U_CD542_MY2021_Rx" SG_ 131 CcAslButtnSetIncPress 1;
BA_ "U_U55X_MY2022_Rx" SG_ 131 CcAslButtnSetIncPress 1;
BA_ "U_CD764_MY2022_Rx" SG_ 131 CcAslButtnSetIncPress 1;
BA_ "U_CDX706_MY2023_Rx" SG_ 131 CcAslButtnSetIncPress 1;
BA_ "U_CX727_MY2021_Rx" SG_ 131 CcAslButtnSetDecPress 1;
BA_ "U_P702_MY2021_Rx" SG_ 131 CcAslButtnSetDecPress 1;
BA_ "U_T6_MCA_MY2020_Rx" SG_ 131 CcAslButtnSetDecPress 1;
BA_ "U_CD542_MY2021_Rx" SG_ 131 CcAslButtnSetDecPress 1;
BA_ "U_U55X_MY2022_Rx" SG_ 131 CcAslButtnSetDecPress 1;
BA_ "U_CD764_MY2022_Rx" SG_ 131 CcAslButtnSetDecPress 1;
BA_ "U_CDX706_MY2023_Rx" SG_ 131 CcAslButtnSetDecPress 1;
BA_ "U_CX727_MY2021_Rx" SG_ 131 CcAslButtnResIncPress 1;
BA_ "U_P702_MY2021_Rx" SG_ 131 CcAslButtnResIncPress 1;
BA_ "U_T6_MCA_MY2020_Rx" SG_ 131 CcAslButtnResIncPress 1;
BA_ "U_CD542_MY2021_Rx" SG_ 131 CcAslButtnResIncPress 1;
BA_ "U_U55X_MY2022_Rx" SG_ 131 CcAslButtnResIncPress 1;
BA_ "U_CD764_MY2022_Rx" SG_ 131 CcAslButtnResIncPress 1;
BA_ "U_CDX706_MY2023_Rx" SG_ 131 CcAslButtnResIncPress 1;
BA_ "U_CX727_MY2021_Rx" SG_ 131 CcAslButtnOnPress 1;
BA_ "U_P702_MY2021_Rx" SG_ 131 CcAslButtnOnPress 1;
BA_ "U_T6_MCA_MY2020_Rx" SG_ 131 CcAslButtnOnPress 1;
BA_ "U_CD542_MY2021_Rx" SG_ 131 CcAslButtnOnPress 1;
BA_ "U_U55X_MY2022_Rx" SG_ 131 CcAslButtnOnPress 1;
BA_ "U_CD764_MY2022_Rx" SG_ 131 CcAslButtnOnPress 1;
BA_ "U_CDX706_MY2023_Rx" SG_ 131 CcAslButtnOnPress 1;
BA_ "U_CX727_MY2021_Rx" SG_ 131 CcAslButtnIndxIncPress 1;
BA_ "U_P702_MY2021_Rx" SG_ 131 CcAslButtnIndxIncPress 1;
BA_ "U_T6_MCA_MY2020_Rx" SG_ 131 CcAslButtnIndxIncPress 1;
BA_ "U_CD542_MY2021_Rx" SG_ 131 CcAslButtnIndxIncPress 1;
BA_ "U_U55X_MY2022_Rx" SG_ 131 CcAslButtnIndxIncPress 1;
BA_ "U_CD764_MY2022_Rx" SG_ 131 CcAslButtnIndxIncPress 1;
BA_ "U_CDX706_MY2023_Rx" SG_ 131 CcAslButtnIndxIncPress 1;
BA_ "U_CX727_MY2021_Rx" SG_ 131 CcAslButtnIndxDecPress 1;
BA_ "U_P702_MY2021_Rx" SG_ 131 CcAslButtnIndxDecPress 1;
BA_ "U_T6_MCA_MY2020_Rx" SG_ 131 CcAslButtnIndxDecPress 1;
BA_ "U_CD542_MY2021_Rx" SG_ 131 CcAslButtnIndxDecPress 1;
BA_ "U_U55X_MY2022_Rx" SG_ 131 CcAslButtnIndxDecPress 1;
BA_ "U_CD764_MY2022_Rx" SG_ 131 CcAslButtnIndxDecPress 1;
BA_ "U_CDX706_MY2023_Rx" SG_ 131 CcAslButtnIndxDecPress 1;
BA_ "U_CX727_MY2021_Rx" SG_ 131 CcAslButtnDeny_B_Actl 1;
BA_ "U_P702_MY2021_Rx" SG_ 131 CcAslButtnDeny_B_Actl 1;
BA_ "U_T6_MCA_MY2020_Rx" SG_ 131 CcAslButtnDeny_B_Actl 1;
BA_ "U_CD542_MY2021_Rx" SG_ 131 CcAslButtnDeny_B_Actl 1;
BA_ "U_U55X_MY2022_Rx" SG_ 131 CcAslButtnDeny_B_Actl 1;
BA_ "U_CD764_MY2022_Rx" SG_ 131 CcAslButtnDeny_B_Actl 1;
BA_ "U_CDX706_MY2023_Rx" SG_ 131 CcAslButtnDeny_B_Actl 1;
BA_ "U_CX727_MY2021_Rx" SG_ 131 CcAslButtnCnclResPress 1;
BA_ "U_P702_MY2021_Rx" SG_ 131 CcAslButtnCnclResPress 1;
BA_ "U_T6_MCA_MY2020_Rx" SG_ 131 CcAslButtnCnclResPress 1;
BA_ "U_CD542_MY2021_Rx" SG_ 131 CcAslButtnCnclResPress 1;
BA_ "U_U55X_MY2022_Rx" SG_ 131 CcAslButtnCnclResPress 1;
BA_ "U_CD764_MY2022_Rx" SG_ 131 CcAslButtnCnclResPress 1;
BA_ "U_CDX706_MY2023_Rx" SG_ 131 CcAslButtnCnclResPress 1;
BA_ "U_CX727_MY2021_Rx" SG_ 131 CcAslButtnCnclPress 1;
BA_ "U_P702_MY2021_Rx" SG_ 131 CcAslButtnCnclPress 1;
BA_ "U_T6_MCA_MY2020_Rx" SG_ 131 CcAslButtnCnclPress 1;
BA_ "U_CD542_MY2021_Rx" SG_ 131 CcAslButtnCnclPress 1;
BA_ "U_U55X_MY2022_Rx" SG_ 131 CcAslButtnCnclPress 1;
BA_ "U_CD764_MY2022_Rx" SG_ 131 CcAslButtnCnclPress 1;
BA_ "U_CDX706_MY2023_Rx" SG_ 131 CcAslButtnCnclPress 1;
BA_ "U_T6_MCA_MY2020_Rx" SG_ 131 LaSwtchPos_D_Stat 1;
BA_ "U_CD542_MY2021_Rx" SG_ 131 LaSwtchPos_D_Stat 1;
BA_ "U_U55X_MY2022_Rx" SG_ 131 LaSwtchPos_D_Stat 1;
BA_ "U_CD764_MY2022_Rx" SG_ 131 LaSwtchPos_D_Stat 1;
BA_ "U_CDX706_MY2023_Rx" SG_ 131 LaSwtchPos_D_Stat 1;
BA_ "WakeupSignal" SG_ 131 HeadLghtHiFlash_D_Stat 1;
BA_ "WakeupSignal" SG_ 787 DrLckCnt_No_ActlTgate 1;
BA_ "WakeupSignal" SG_ 787 DrTgateChime2_D_Rq 1;
BA_ "WakeupSignal" SG_ 787 DrTGate_D_Rq 1;
BA_ "U_P702_MY2021_Rx" SG_ 787 DrTGate_D_Rq 1;
BA_ "U_T6_MCA_MY2020_Rx" SG_ 787 DrTGate_D_Rq 1;
BA_ "WakeupSignal" SG_ 787 PwLftgtIntSw_B_Stat 1;
BA_ "U_T6_MCA_MY2020_Rx" SG_ 570 SuspClkSync_No_Rq 1;
BA_ "U_U55X_MY2022_Rx" SG_ 570 SuspClkSync_No_Rq 1;
BA_ "U_CDX706_MY2023_Rx" SG_ 570 SuspClkSync_No_Rq 1;
BA_ "U_U55X_MY2022_Tx" SG_ 570 SuspClkSync_No_Rq 1;
BA_ "GenSigStartValueInteger" SG_ 570 SuspRearRight_L_Actl 511;
BA_ "GenSigStartValue" SG_ 570 SuspRearRight_L_Actl 511;
BA_ "U_CX727_MY2021_Rx" SG_ 570 SuspRearRight_L_Actl 1;
BA_ "U_T6_MCA_MY2020_Rx" SG_ 570 SuspRearRight_L_Actl 1;
BA_ "U_U55X_MY2022_Rx" SG_ 570 SuspRearRight_L_Actl 1;
BA_ "U_CDX706_MY2023_Rx" SG_ 570 SuspRearRight_L_Actl 1;
BA_ "U_T6_MCA_MY2020_Tx" SG_ 570 SuspRearRight_L_Actl 1;
BA_ "U_U55X_MY2022_Tx" SG_ 570 SuspRearRight_L_Actl 1;
BA_ "GenSigStartValueInteger" SG_ 570 SuspFrntRight_L_Actl 511;
BA_ "GenSigStartValue" SG_ 570 SuspFrntRight_L_Actl 511;
BA_ "U_CX727_MY2021_Rx" SG_ 570 SuspFrntRight_L_Actl 1;
BA_ "U_T6_MCA_MY2020_Rx" SG_ 570 SuspFrntRight_L_Actl 1;
BA_ "U_U55X_MY2022_Rx" SG_ 570 SuspFrntRight_L_Actl 1;
BA_ "U_CDX706_MY2023_Rx" SG_ 570 SuspFrntRight_L_Actl 1;
BA_ "U_T6_MCA_MY2020_Tx" SG_ 570 SuspFrntRight_L_Actl 1;
BA_ "U_U55X_MY2022_Tx" SG_ 570 SuspFrntRight_L_Actl 1;
BA_ "GenSigStartValueInteger" SG_ 570 SuspRear_L_Prev 511;
BA_ "GenSigStartValue" SG_ 570 SuspRear_L_Prev 511;
BA_ "U_CX727_MY2021_Rx" SG_ 570 SuspRear_L_Prev 1;
BA_ "U_P702_MY2021_Rx" SG_ 570 SuspRear_L_Prev 1;
BA_ "U_T6_MCA_MY2020_Tx" SG_ 570 SuspRear_L_Prev 1;
BA_ "U_U55X_MY2022_Tx" SG_ 570 SuspRear_L_Prev 1;
BA_ "GenSigStartValueInteger" SG_ 570 SuspRear_L_Actl 511;
BA_ "GenSigStartValue" SG_ 570 SuspRear_L_Actl 511;
BA_ "U_CX727_MY2021_Rx" SG_ 570 SuspRear_L_Actl 1;
BA_ "U_P702_MY2021_Rx" SG_ 570 SuspRear_L_Actl 1;
BA_ "U_T6_MCA_MY2020_Rx" SG_ 570 SuspRear_L_Actl 1;
BA_ "U_U55X_MY2022_Rx" SG_ 570 SuspRear_L_Actl 1;
BA_ "U_CD764_MY2022_Rx" SG_ 570 SuspRear_L_Actl 1;
BA_ "U_CDX706_MY2023_Rx" SG_ 570 SuspRear_L_Actl 1;
BA_ "U_T6_MCA_MY2020_Tx" SG_ 570 SuspRear_L_Actl 1;
BA_ "U_U55X_MY2022_Tx" SG_ 570 SuspRear_L_Actl 1;
BA_ "GenSigStartValueInteger" SG_ 570 SuspFrnt_L_Prev 511;
BA_ "GenSigStartValue" SG_ 570 SuspFrnt_L_Prev 511;
BA_ "U_CX727_MY2021_Rx" SG_ 570 SuspFrnt_L_Prev 1;
BA_ "U_P702_MY2021_Rx" SG_ 570 SuspFrnt_L_Prev 1;
BA_ "U_T6_MCA_MY2020_Tx" SG_ 570 SuspFrnt_L_Prev 1;
BA_ "U_U55X_MY2022_Tx" SG_ 570 SuspFrnt_L_Prev 1;
BA_ "GenSigStartValueInteger" SG_ 570 SuspFrnt_L_Actl 511;
BA_ "GenSigStartValue" SG_ 570 SuspFrnt_L_Actl 511;
BA_ "U_CX727_MY2021_Rx" SG_ 570 SuspFrnt_L_Actl 1;
BA_ "U_P702_MY2021_Rx" SG_ 570 SuspFrnt_L_Actl 1;
BA_ "U_T6_MCA_MY2020_Rx" SG_ 570 SuspFrnt_L_Actl 1;
BA_ "U_U55X_MY2022_Rx" SG_ 570 SuspFrnt_L_Actl 1;
BA_ "U_CD764_MY2022_Rx" SG_ 570 SuspFrnt_L_Actl 1;
BA_ "U_CDX706_MY2023_Rx" SG_ 570 SuspFrnt_L_Actl 1;
BA_ "U_T6_MCA_MY2020_Tx" SG_ 570 SuspFrnt_L_Actl 1;
BA_ "U_U55X_MY2022_Tx" SG_ 570 SuspFrnt_L_Actl 1;
BA_ "U_CDX706_MY2023_Rx" SG_ 953 BattULoChrgHyb_B_Rq 1;
BA_ "GenSigStartValueInteger" SG_ 953 WakeAlarm3_D_Stat 3;
BA_ "GenSigStartValue" SG_ 953 WakeAlarm3_D_Stat 3;
BA_ "GenSigStartValueInteger" SG_ 953 WakeAlarm2_D_Stat 3;
BA_ "GenSigStartValue" SG_ 953 WakeAlarm2_D_Stat 3;
BA_ "GenSigStartValueInteger" SG_ 953 WakeAlarm1_D_Stat 3;
BA_ "GenSigStartValue" SG_ 953 WakeAlarm1_D_Stat 3;
BA_ "U_CX727_MY2021_Rx" SG_ 953 WakeAlarm1_D_Stat 1;
BA_ "U_P702_MY2021_Rx" SG_ 953 WakeAlarm1_D_Stat 1;
BA_ "U_T6_MCA_MY2020_Rx" SG_ 953 WakeAlarm1_D_Stat 1;
BA_ "U_CD542_MY2021_Rx" SG_ 953 WakeAlarm1_D_Stat 1;
BA_ "U_CDX706_MY2023_Rx" SG_ 953 WakeAlarm1_D_Stat 1;
BA_ "GenSigStartValueInteger" SG_ 953 WakeAlarm0_D_Stat 3;
BA_ "GenSigStartValue" SG_ 953 WakeAlarm0_D_Stat 3;
BA_ "U_CX727_MY2021_Rx" SG_ 953 WakeAlarm0_D_Stat 1;
BA_ "U_CD542_MY2021_Rx" SG_ 953 WakeAlarm0_D_Stat 1;
BA_ "U_CDX706_MY2023_Rx" SG_ 953 WakeAlarm0_D_Stat 1;
BA_ "GenSigStartValueInteger" SG_ 953 BattRgenLoSoc_Pc_LimLo 30;
BA_ "GenSigStartValue" SG_ 953 BattRgenLoSoc_Pc_LimLo 30;
BA_ "U_P702_MY2021_Rx" SG_ 953 BattRgenLoChrg_D_Rq 1;
BA_ "U_P702_MY2021_Rx" SG_ 953 BattRgenLoDChrg_D_Rq 1;
BA_ "GenSigSendType" SG_ 1101 AwdLckLamp_D_Rq 3;
BA_ "U_T6_MCA_MY2020_Tx" SG_ 1101 AwdLckLamp_D_Rq 1;
BA_ "GenSigStartValueInteger" SG_ 1101 Ptu_Te_Actl 50;
BA_ "U_T6_MCA_MY2020_Rx" SG_ 1101 Ptu_Te_Actl 1;
BA_ "U_T6_MCA_MY2020_Tx" SG_ 1101 Ptu_Te_Actl 1;
BA_ "GenSigSendType" SG_ 1101 PtLatchActv_B_RqAwd 3;
BA_ "U_CX727_MY2021_Rx" SG_ 1101 PtLatchActv_B_RqAwd 1;
BA_ "U_T6_MCA_MY2020_Rx" SG_ 1101 PtLatchActv_B_RqAwd 1;
BA_ "U_CDX706_MY2023_Rx" SG_ 1101 PtLatchActv_B_RqAwd 1;
BA_ "U_T6_MCA_MY2020_Tx" SG_ 1101 PtLatchActv_B_RqAwd 1;
BA_ "GenSigSendType" SG_ 1101 PtuFanOn_B_Rq 3;
BA_ "U_T6_MCA_MY2020_Rx" SG_ 1101 PtuFanOn_B_Rq 1;
BA_ "U_T6_MCA_MY2020_Tx" SG_ 1101 PtuFanOn_B_Rq 1;
BA_ "GenSigSendType" SG_ 1101 RearDiffLckLamp_D_Rq3 3;
BA_ "U_U55X_MY2022_Rx" SG_ 1099 RearDiff_D_Stat 1;
BA_ "U_U55X_MY2022_Rx" SG_ 1099 RearDiffThrml_D_Stat 1;
BA_ "U_CDX706_MY2023_Rx" SG_ 1099 RearDiffThrml_D_Stat 1;
BA_ "U_CDX706_MY2023_Rx" SG_ 1099 RearDiffSrvcRqd_B_Rq 1;
BA_ "U_T6_MCA_MY2020_Rx" SG_ 1052 AwdDcnntSlipTrgt_B_Rq 1;
BA_ "U_CDX706_MY2023_Rx" SG_ 1052 AwdDcnntSlipTrgt_B_Rq 1;
BA_ "U_T6_MCA_MY2020_Tx" SG_ 1052 AwdDcnntSlipTrgt_B_Rq 1;
BA_ "GenSigStartValueInteger" SG_ 1052 AwdCnnct_D_Stat 1;
BA_ "GenSigStartValue" SG_ 1052 AwdCnnct_D_Stat 1;
BA_ "U_T6_MCA_MY2020_Rx" SG_ 1052 AwdCnnct_D_Stat 1;
BA_ "U_CDX706_MY2023_Rx" SG_ 1052 AwdCnnct_D_Stat 1;
BA_ "U_T6_MCA_MY2020_Tx" SG_ 1052 AwdCnnct_D_Stat 1;
BA_ "U_CX727_MY2021_Rx" SG_ 1052 AwdLck_Tq_Actl 1;
BA_ "U_P702_MY2021_Rx" SG_ 1052 AwdLck_Tq_Actl 1;
BA_ "U_T6_MCA_MY2020_Rx" SG_ 1052 AwdLck_Tq_Actl 1;
BA_ "U_CD542_MY2021_Rx" SG_ 1052 AwdLck_Tq_Actl 1;
BA_ "U_CDX706_MY2023_Rx" SG_ 1052 AwdLck_Tq_Actl 1;
BA_ "U_CX727_MY2021_Tx" SG_ 1052 AwdLck_Tq_Actl 1;
BA_ "U_T6_MCA_MY2020_Tx" SG_ 1052 AwdLck_Tq_Actl 1;
BA_ "U_CX727_MY2021_Rx" SG_ 1052 AwdLckTqNeg_B_Actl 1;
BA_ "U_CD542_MY2021_Rx" SG_ 1052 AwdLckTqNeg_B_Actl 1;
BA_ "U_CDX706_MY2023_Rx" SG_ 1052 AwdLckTqNeg_B_Actl 1;
BA_ "U_CX727_MY2021_Tx" SG_ 1052 AwdLckTqNeg_B_Actl 1;
BA_ "U_U55X_MY2022_Rx" SG_ 1093 TrlrBrkMde_D_Actl 1;
BA_ "U_T6_MCA_MY2020_Rx" SG_ 1093 TrlrBrkDcnnt_B_Actl 1;
BA_ "U_U55X_MY2022_Rx" SG_ 1093 TrlrBrkDcnnt_B_Actl 1;
BA_ "U_CX727_MY2021_Rx" SG_ 1093 TrlrBrkActCnnct_B_Actl 1;
BA_ "U_P702_MY2021_Rx" SG_ 1093 TrlrBrkActCnnct_B_Actl 1;
BA_ "U_T6_MCA_MY2020_Rx" SG_ 1093 TrlrBrkActCnnct_B_Actl 1;
BA_ "U_CD542_MY2021_Rx" SG_ 1093 TrlrBrkActCnnct_B_Actl 1;
BA_ "U_U55X_MY2022_Rx" SG_ 1093 TrlrBrkActCnnct_B_Actl 1;
BA_ "U_CD764_MY2022_Rx" SG_ 1093 TrlrBrkActCnnct_B_Actl 1;
BA_ "U_CDX706_MY2023_Rx" SG_ 1093 TrlrBrkActCnnct_B_Actl 1;
BA_ "ContentDependant" SG_ 1093 StopLamp_B_RqTrlrBrk 1;
BA_ "U_T6_MCA_MY2020_Rx" SG_ 1093 TrlrBrkCtl_B_Falt 1;
BA_ "U_CD542_MY2021_Rx" SG_ 1093 TrlrBrkCtl_B_Falt 1;
BA_ "U_U55X_MY2022_Rx" SG_ 1093 TrlrBrkCtl_B_Falt 1;
BA_ "U_CD764_MY2022_Rx" SG_ 1093 TrlrBrkCtl_B_Falt 1;
BA_ "U_CDX706_MY2023_Rx" SG_ 1093 TrlrBrkCtl_B_Falt 1;
BA_ "U_T6_MCA_MY2020_Rx" SG_ 1093 TrlrBrkActCirct_B_Falt 1;
BA_ "U_CD542_MY2021_Rx" SG_ 1093 TrlrBrkActCirct_B_Falt 1;
BA_ "U_U55X_MY2022_Rx" SG_ 1093 TrlrBrkActCirct_B_Falt 1;
BA_ "U_CD764_MY2022_Rx" SG_ 1093 TrlrBrkActCirct_B_Falt 1;
BA_ "U_CDX706_MY2023_Rx" SG_ 1093 TrlrBrkActCirct_B_Falt 1;
BA_ "MetaData" SG_ 837 SuspVLimBRq_No_Cs 1;
BA_ "MetaData" SG_ 837 SuspVLimBRq_No_Cnt 1;
BA_ "GenSigSendType" SG_ 837 VdmSustnActv_B_Rq 3;
BA_ "GenSigStartValue" SG_ 837 VehCurb_M_Actl 1022;
BA_ "U_CDX706_MY2023_Rx" SG_ 837 VehCurb_M_Actl 1;
BA_ "GenSigStartValue" SG_ 837 VehGvwr_M_Actl 1022;
BA_ "GenSigSendType" SG_ 837 Ccd_B_Falt 3;
BA_ "U_T6_MCA_MY2020_Tx" SG_ 837 Ccd_B_Falt 1;
BA_ "U_U55X_MY2022_Tx" SG_ 837 Ccd_B_Falt 1;
BA_ "GenSigSendType" SG_ 837 SuspVLim_B_Rq 3;
BA_ "U_CDX706_MY2023_Rx" SG_ 837 SuspVLim_B_Rq 1;
BA_ "GenSigSendType" SG_ 837 SelDrvMdeSusp_D_Stat 3;
BA_ "U_CX727_MY2021_Rx" SG_ 837 SelDrvMdeSusp_D_Stat 1;
BA_ "U_P702_MY2021_Rx" SG_ 837 SelDrvMdeSusp_D_Stat 1;
BA_ "U_T6_MCA_MY2020_Rx" SG_ 837 SelDrvMdeSusp_D_Stat 1;
BA_ "U_U55X_MY2022_Rx" SG_ 837 SelDrvMdeSusp_D_Stat 1;
BA_ "U_T6_MCA_MY2020_Tx" SG_ 837 SelDrvMdeSusp_D_Stat 1;
BA_ "U_U55X_MY2022_Tx" SG_ 837 SelDrvMdeSusp_D_Stat 1;
BA_ "GenSigSendType" SG_ 837 AdptDrvMdePt_D_Rq 3;
BA_ "U_CX727_MY2021_Rx" SG_ 837 AdptDrvMdePt_D_Rq 1;
BA_ "U_P702_MY2021_Rx" SG_ 837 AdptDrvMdePt_D_Rq 1;
BA_ "U_T6_MCA_MY2020_Rx" SG_ 837 AdptDrvMdePt_D_Rq 1;
BA_ "U_U55X_MY2022_Rx" SG_ 837 AdptDrvMdePt_D_Rq 1;
BA_ "U_CDX706_MY2023_Rx" SG_ 837 AdptDrvMdePt_D_Rq 1;
BA_ "U_U55X_MY2022_Tx" SG_ 837 AdptDrvMdePt_D_Rq 1;
BA_ "GenSigSendType" SG_ 837 AdptDrvMdeChassis_D_Rq 3;
BA_ "U_CX727_MY2021_Rx" SG_ 837 AdptDrvMdeChassis_D_Rq 1;
BA_ "U_P702_MY2021_Rx" SG_ 837 AdptDrvMdeChassis_D_Rq 1;
BA_ "U_T6_MCA_MY2020_Rx" SG_ 837 AdptDrvMdeChassis_D_Rq 1;
BA_ "U_U55X_MY2022_Rx" SG_ 837 AdptDrvMdeChassis_D_Rq 1;
BA_ "U_CDX706_MY2023_Rx" SG_ 837 AdptDrvMdeChassis_D_Rq 1;
BA_ "U_U55X_MY2022_Tx" SG_ 837 AdptDrvMdeChassis_D_Rq 1;
BA_ "GenSigSendType" SG_ 837 AirSprngRateRr_D_Rq 3;
BA_ "GenSigSendType" SG_ 837 AirSprngRateRl_D_Rq 3;
BA_ "GenSigSendType" SG_ 837 SuspType_B_Stat 3;
BA_ "U_CDX706_MY2023_Rx" SG_ 837 SuspType_B_Stat 1;
BA_ "GenSigSendType" SG_ 837 AirSprngRateFr_D_Rq 3;
BA_ "GenSigSendType" SG_ 837 AirSprngRateFl_D_Rq 3;
BA_ "GenSigSendType" SG_ 837 AirSusp_D_Stat 3;
BA_ "GenSigSendType" SG_ 837 AirSuspMsgTxt_D_Rq 3;
BA_ "GenSigSendType" SG_ 837 SuspDrvMde_D_Stat 3;
BA_ "GenSigSendType" SG_ 837 CcdMsgTxt_D_RqDsply 3;
BA_ "U_P702_MY2021_Rx" SG_ 837 CcdMsgTxt_D_RqDsply 1;
BA_ "U_U55X_MY2022_Rx" SG_ 837 CcdMsgTxt_D_RqDsply 1;
BA_ "U_T6_MCA_MY2020_Tx" SG_ 837 CcdMsgTxt_D_RqDsply 1;
BA_ "U_U55X_MY2022_Tx" SG_ 837 CcdMsgTxt_D_RqDsply 1;
BA_ "U_P702_MY2021_Rx" SG_ 792 FuelRange_L_Dsply 1;
BA_ "U_T6_MCA_MY2020_Rx" SG_ 792 FuelRange_L_Dsply 1;
BA_ "ContentDependant" SG_ 792 ElTrip_L_Dsply 1;
BA_ "ContentDependant" SG_ 792 ElLongTerm_L_Dsply 1;
BA_ "U_T6_MCA_MY2020_Rx" SG_ 968 RvltnMatchAllw_D_Rq 1;
BA_ "U_CDX706_MY2023_Rx" SG_ 968 RvltnMatchAllw_D_Rq 1;
BA_ "U_T6_MCA_MY2020_Rx" SG_ 968 LnchCtl_N_Rq 1;
BA_ "U_CDX706_MY2023_Rx" SG_ 968 LnchCtl_N_Rq 1;
BA_ "U_CDX706_MY2023_Rx" SG_ 968 LnchCtl_D_Rq 1;
BA_ "GenSigStartValueInteger" SG_ 968 CurrentColor_CmdGage 8;
BA_ "GenSigStartValue" SG_ 968 CurrentColor_CmdGage 8;
BA_ "GenSigStartValueInteger" SG_ 968 BlendedColor_CmdGage 2;
BA_ "GenSigStartValue" SG_ 968 BlendedColor_CmdGage 2;
BA_ "GenSigStartValueInteger" SG_ 968 Current_Color_Cmd 8;
BA_ "GenSigStartValue" SG_ 968 Current_Color_Cmd 8;
BA_ "GenSigStartValueInteger" SG_ 968 BlendedColor_Cmd 2;
BA_ "GenSigStartValue" SG_ 968 BlendedColor_Cmd 2;
BA_ "GenSigStartValueInteger" SG_ 968 SlMde_D_Rq 2;
BA_ "GenSigStartValue" SG_ 968 SlMde_D_Rq 2;
BA_ "U_P702_MY2021_Rx" SG_ 968 SlMde_D_Rq 1;
BA_ "U_T6_MCA_MY2020_Rx" SG_ 968 SlMde_D_Rq 1;
BA_ "U_CD542_MY2021_Rx" SG_ 968 SlMde_D_Rq 1;
BA_ "U_CD764_MY2022_Rx" SG_ 968 SlMde_D_Rq 1;
BA_ "U_CDX706_MY2023_Rx" SG_ 968 SlMde_D_Rq 1;
BA_ "GenSigStartValueInteger" SG_ 968 IsaOffst_D_Rq 14;
BA_ "GenSigStartValue" SG_ 968 IsaOffst_D_Rq 14;
BA_ "U_P702_MY2021_Rx" SG_ 968 IsaOffst_D_Rq 1;
BA_ "U_T6_MCA_MY2020_Rx" SG_ 968 IsaOffst_D_Rq 1;
BA_ "U_CD542_MY2021_Rx" SG_ 968 IsaOffst_D_Rq 1;
BA_ "U_CD764_MY2022_Rx" SG_ 968 IsaOffst_D_Rq 1;
BA_ "U_CDX706_MY2023_Rx" SG_ 968 IsaOffst_D_Rq 1;
BA_ "U_CD542_MY2021_Rx" SG_ 819 WndwUpPsngrRear_D_Falt 1;
BA_ "U_CD764_MY2022_Rx" SG_ 819 WndwUpPsngrRear_D_Falt 1;
BA_ "U_CDX706_MY2023_Rx" SG_ 819 WndwUpPsngrRear_D_Falt 1;
BA_ "U_CD542_MY2021_Rx" SG_ 819 WndwUpPsngrFront_D_Falt 1;
BA_ "U_CD764_MY2022_Rx" SG_ 819 WndwUpPsngrFront_D_Falt 1;
BA_ "U_CDX706_MY2023_Rx" SG_ 819 WndwUpPsngrFront_D_Falt 1;
BA_ "WakeupSignal" SG_ 819 Memory_3_SwPsngr_Stat 1;
BA_ "WakeupSignal" SG_ 819 Memory_2_SwPsngr_Stat 1;
BA_ "WakeupSignal" SG_ 819 Memory_1_SwPsngr_Stat 1;
BA_ "U_T6_MCA_MY2020_Rx" SG_ 819 BLISLEDStatPassSide 1;
BA_ "U_CD542_MY2021_Rx" SG_ 819 BLISLEDStatPassSide 1;
BA_ "U_U55X_MY2022_Rx" SG_ 819 BLISLEDStatPassSide 1;
BA_ "U_CD764_MY2022_Rx" SG_ 819 BLISLEDStatPassSide 1;
BA_ "U_CDX706_MY2023_Rx" SG_ 819 BLISLEDStatPassSide 1;
BA_ "U_P702_MY2021_Rx" SG_ 819 WndwPsngrSide_D_Stat 1;
BA_ "U_T6_MCA_MY2020_Rx" SG_ 819 WndwPsngrSide_D_Stat 1;
BA_ "U_CD542_MY2021_Rx" SG_ 819 WndwPsngrSide_D_Stat 1;
BA_ "U_U55X_MY2022_Rx" SG_ 819 WndwPsngrSide_D_Stat 1;
BA_ "WakeupSignal" SG_ 819 Pasngr_Lock_Sw_Stat 1;
BA_ "WakeupSignal" SG_ 819 Pasngr_Lock_Sw_Cnt 1;
BA_ "MetaData" SG_ 819 Pasngr_Lock_Sw_Cnt 1;
BA_ "WakeupSignal" SG_ 819 ChildLckFdbckRp_B_Stat 1;
BA_ "WakeupSignal" SG_ 819 DrPrsntPsngr_D_Stat 1;
BA_ "WakeupSignal" SG_ 819 DrPrsntRearPsngr_D_Stat 1;
BA_ "U_CD542_MY2021_Rx" SG_ 818 WndwUpDrvRear_D_Falt 1;
BA_ "U_CD764_MY2022_Rx" SG_ 818 WndwUpDrvRear_D_Falt 1;
BA_ "U_CDX706_MY2023_Rx" SG_ 818 WndwUpDrvRear_D_Falt 1;
BA_ "U_CD542_MY2021_Rx" SG_ 818 WndwUpDrvFront_D_Falt 1;
BA_ "U_CD764_MY2022_Rx" SG_ 818 WndwUpDrvFront_D_Falt 1;
BA_ "U_CDX706_MY2023_Rx" SG_ 818 WndwUpDrvFront_D_Falt 1;
BA_ "U_T6_MCA_MY2020_Rx" SG_ 818 BLISLEDStatDriverSide 1;
BA_ "U_CD542_MY2021_Rx" SG_ 818 BLISLEDStatDriverSide 1;
BA_ "U_U55X_MY2022_Rx" SG_ 818 BLISLEDStatDriverSide 1;
BA_ "U_CD764_MY2022_Rx" SG_ 818 BLISLEDStatDriverSide 1;
BA_ "U_CDX706_MY2023_Rx" SG_ 818 BLISLEDStatDriverSide 1;
BA_ "WakeupSignal" SG_ 818 ChildLckPw_N_Cnt 1;
BA_ "U_P702_MY2021_Rx" SG_ 818 WndwDrvSide_D_Stat 1;
BA_ "U_T6_MCA_MY2020_Rx" SG_ 818 WndwDrvSide_D_Stat 1;
BA_ "U_CD542_MY2021_Rx" SG_ 818 WndwDrvSide_D_Stat 1;
BA_ "U_U55X_MY2022_Rx" SG_ 818 WndwDrvSide_D_Stat 1;
BA_ "WakeupSignal" SG_ 818 KeyCylSwDrvDr_D_Stat 1;
BA_ "WakeupSignal" SG_ 818 Driver_Lock_Sw_Stat 1;
BA_ "WakeupSignal" SG_ 818 Driver_Lock_Sw_Cnt 1;
BA_ "MetaData" SG_ 818 Driver_Lock_Sw_Cnt 1;
BA_ "WakeupSignal" SG_ 818 ChildLckPw_D_Rq 1;
BA_ "WakeupSignal" SG_ 818 ChildLckFdbckRd_B_Stat 1;
BA_ "WakeupSignal" SG_ 818 DrPrsntDrv_D_Stat 1;
BA_ "U_T6_MCA_MY2020_Rx" SG_ 818 DrPrsntDrv_D_Stat 1;
BA_ "U_U55X_MY2022_Rx" SG_ 818 DrPrsntDrv_D_Stat 1;
BA_ "WakeupSignal" SG_ 818 DrPrsntRearDrv_D_Stat 1;
BA_ "U_CDX706_MY2023_Rx" SG_ 806 ClimtCoolRear_B_Rq 1;
BA_ "U_CDX706_MY2023_Rx" SG_ 806 ClimtHeatRear_D_Rq 1;
BA_ "GenSigStartValueInteger" SG_ 806 ClimtDeltaLoad_Pw_Actl 32;
BA_ "U_P702_MY2021_Rx" SG_ 806 StopStrtDrvMde_B_RqBtn 1;
BA_ "U_T6_MCA_MY2020_Rx" SG_ 806 StopStrtDrvMde_B_RqBtn 1;
BA_ "U_CD542_MY2021_Rx" SG_ 806 StopStrtDrvMde_B_RqBtn 1;
BA_ "U_U55X_MY2022_Rx" SG_ 806 StopStrtDrvMde_B_RqBtn 1;
BA_ "U_CD764_MY2022_Rx" SG_ 806 StopStrtDrvMde_B_RqBtn 1;
BA_ "U_CDX706_MY2023_Rx" SG_ 806 StopStrtDrvMde_B_RqBtn 1;
BA_ "U_CX727_MY2021_Rx" SG_ 806 HvacHtrCore_Te_Rq 1;
BA_ "U_P702_MY2021_Rx" SG_ 806 HvacHtrCore_Te_Rq 1;
BA_ "U_T6_MCA_MY2020_Rx" SG_ 806 HvacHtrCore_Te_Rq 1;
BA_ "U_CD542_MY2021_Rx" SG_ 806 HvacHtrCore_Te_Rq 1;
BA_ "U_CDX706_MY2023_Rx" SG_ 806 HvacHtrCore_Te_Rq 1;
BA_ "U_CX727_MY2021_Rx" SG_ 806 ClimtHeat_D_Rq 1;
BA_ "U_P702_MY2021_Rx" SG_ 806 ClimtHeat_D_Rq 1;
BA_ "U_T6_MCA_MY2020_Rx" SG_ 806 ClimtHeat_D_Rq 1;
BA_ "U_CD542_MY2021_Rx" SG_ 806 ClimtHeat_D_Rq 1;
BA_ "U_U55X_MY2022_Rx" SG_ 806 ClimtHeat_D_Rq 1;
BA_ "U_CD764_MY2022_Rx" SG_ 806 ClimtHeat_D_Rq 1;
BA_ "U_CDX706_MY2023_Rx" SG_ 806 ClimtHeat_D_Rq 1;
BA_ "U_CX727_MY2021_Rx" SG_ 806 ClimtCool_D_Rq 1;
BA_ "U_P702_MY2021_Rx" SG_ 806 ClimtCool_D_Rq 1;
BA_ "U_T6_MCA_MY2020_Rx" SG_ 806 ClimtCool_D_Rq 1;
BA_ "U_CD542_MY2021_Rx" SG_ 806 ClimtCool_D_Rq 1;
BA_ "U_U55X_MY2022_Rx" SG_ 806 ClimtCool_D_Rq 1;
BA_ "U_CD764_MY2022_Rx" SG_ 806 ClimtCool_D_Rq 1;
BA_ "U_CDX706_MY2023_Rx" SG_ 806 ClimtCool_D_Rq 1;
BA_ "GenSigStartValueInteger" SG_ 806 HvacEvap_Te_Rq 400;
BA_ "U_CX727_MY2021_Rx" SG_ 806 HvacEvap_Te_Rq 1;
BA_ "U_P702_MY2021_Rx" SG_ 806 HvacEvap_Te_Rq 1;
BA_ "U_T6_MCA_MY2020_Rx" SG_ 806 HvacEvap_Te_Rq 1;
BA_ "U_CD542_MY2021_Rx" SG_ 806 HvacEvap_Te_Rq 1;
BA_ "U_U55X_MY2022_Rx" SG_ 806 HvacEvap_Te_Rq 1;
BA_ "U_CD764_MY2022_Rx" SG_ 806 HvacEvap_Te_Rq 1;
BA_ "U_CDX706_MY2023_Rx" SG_ 806 HvacEvap_Te_Rq 1;
BA_ "GenSigStartValueInteger" SG_ 806 HvacEvap_Te_Actl 400;
BA_ "U_CX727_MY2021_Rx" SG_ 806 HvacEvap_Te_Actl 1;
BA_ "U_P702_MY2021_Rx" SG_ 806 HvacEvap_Te_Actl 1;
BA_ "U_T6_MCA_MY2020_Rx" SG_ 806 HvacEvap_Te_Actl 1;
BA_ "U_CD542_MY2021_Rx" SG_ 806 HvacEvap_Te_Actl 1;
BA_ "U_U55X_MY2022_Rx" SG_ 806 HvacEvap_Te_Actl 1;
BA_ "U_CD764_MY2022_Rx" SG_ 806 HvacEvap_Te_Actl 1;
BA_ "U_CDX706_MY2023_Rx" SG_ 806 HvacEvap_Te_Actl 1;
BA_ "U_P702_MY2021_Rx" SG_ 806 HvacAirCond_B_Rq 1;
BA_ "U_T6_MCA_MY2020_Rx" SG_ 806 HvacAirCond_B_Rq 1;
BA_ "U_CD542_MY2021_Rx" SG_ 806 HvacAirCond_B_Rq 1;
BA_ "U_U55X_MY2022_Rx" SG_ 806 HvacAirCond_B_Rq 1;
BA_ "U_CD764_MY2022_Rx" SG_ 806 HvacAirCond_B_Rq 1;
BA_ "U_CDX706_MY2023_Rx" SG_ 806 HvacAirCond_B_Rq 1;
BA_ "GenSigStartValueInteger" SG_ 806 HvacEvap_Te_Offst 400;
BA_ "U_P702_MY2021_Rx" SG_ 806 HvacEvap_Te_Offst 1;
BA_ "U_T6_MCA_MY2020_Rx" SG_ 806 HvacEvap_Te_Offst 1;
BA_ "U_CD542_MY2021_Rx" SG_ 806 HvacEvap_Te_Offst 1;
BA_ "U_U55X_MY2022_Rx" SG_ 806 HvacEvap_Te_Offst 1;
BA_ "U_CD764_MY2022_Rx" SG_ 806 HvacEvap_Te_Offst 1;
BA_ "U_CDX706_MY2023_Rx" SG_ 806 HvacEvap_Te_Offst 1;
BA_ "U_P702_MY2021_Rx" SG_ 806 ClimtPw_B_Rq 1;
BA_ "U_T6_MCA_MY2020_Rx" SG_ 806 ClimtPw_B_Rq 1;
BA_ "U_CD542_MY2021_Rx" SG_ 806 ClimtPw_B_Rq 1;
BA_ "U_U55X_MY2022_Rx" SG_ 806 ClimtPw_B_Rq 1;
BA_ "U_CD764_MY2022_Rx" SG_ 806 ClimtPw_B_Rq 1;
BA_ "U_CDX706_MY2023_Rx" SG_ 806 ClimtPw_B_Rq 1;
BA_ "GenSigStartValueInteger" SG_ 765 BalrSwtch_D_Stat 1;
BA_ "GenSigStartValue" SG_ 765 BalrSwtch_D_Stat 1;
BA_ "U_T6_MCA_MY2020_Rx" SG_ 765 BalrSwtch_D_Stat 1;
BA_ "U_CD542_MY2021_Rx" SG_ 765 BalrSwtch_D_Stat 1;
BA_ "U_U55X_MY2022_Rx" SG_ 765 BalrSwtch_D_Stat 1;
BA_ "U_CD764_MY2022_Rx" SG_ 765 BalrSwtch_D_Stat 1;
BA_ "U_CDX706_MY2023_Rx" SG_ 765 BalrSwtch_D_Stat 1;
BA_ "U_T6_MCA_MY2020_Rx" SG_ 765 BalrMde_D_Rq 1;
BA_ "U_CD542_MY2021_Rx" SG_ 765 BalrMde_D_Rq 1;
BA_ "U_U55X_MY2022_Rx" SG_ 765 BalrMde_D_Rq 1;
BA_ "U_CD764_MY2022_Rx" SG_ 765 BalrMde_D_Rq 1;
BA_ "U_CDX706_MY2023_Rx" SG_ 765 BalrMde_D_Rq 1;
BA_ "GenSigStartValueInteger" SG_ 765 WaitToStartLamp_D_Falt 1;
BA_ "GenSigStartValue" SG_ 765 WaitToStartLamp_D_Falt 1;
BA_ "U_P702_MY2021_Rx" SG_ 765 WaitToStartLamp_D_Falt 1;
BA_ "U_T6_MCA_MY2020_Rx" SG_ 765 WaitToStartLamp_D_Falt 1;
BA_ "GenSigStartValueInteger" SG_ 765 EsaOn_B_Rq 1;
BA_ "GenSigStartValue" SG_ 765 EsaOn_B_Rq 1;
BA_ "U_CX727_MY2021_Rx" SG_ 765 EsaOn_B_Rq 1;
BA_ "U_P702_MY2021_Rx" SG_ 765 EsaOn_B_Rq 1;
BA_ "U_T6_MCA_MY2020_Rx" SG_ 765 EsaOn_B_Rq 1;
BA_ "U_CD542_MY2021_Rx" SG_ 765 EsaOn_B_Rq 1;
BA_ "U_U55X_MY2022_Rx" SG_ 765 EsaOn_B_Rq 1;
BA_ "U_CD764_MY2022_Rx" SG_ 765 EsaOn_B_Rq 1;
BA_ "U_CDX706_MY2023_Rx" SG_ 765 EsaOn_B_Rq 1;
BA_ "U_T6_MCA_MY2020_Rx" SG_ 765 BttOn_B_Rq 1;
BA_ "U_CD542_MY2021_Rx" SG_ 765 BttOn_B_Rq 1;
BA_ "U_U55X_MY2022_Rx" SG_ 765 BttOn_B_Rq 1;
BA_ "U_CD764_MY2022_Rx" SG_ 765 BttOn_B_Rq 1;
BA_ "U_CDX706_MY2023_Rx" SG_ 765 BttOn_B_Rq 1;
BA_ "GenSigStartValueInteger" SG_ 765 Btt_L_Actl 126;
BA_ "GenSigStartValue" SG_ 765 Btt_L_Actl 126;
BA_ "U_T6_MCA_MY2020_Rx" SG_ 765 Btt_L_Actl 1;
BA_ "U_CD542_MY2021_Rx" SG_ 765 Btt_L_Actl 1;
BA_ "U_U55X_MY2022_Rx" SG_ 765 Btt_L_Actl 1;
BA_ "U_CD764_MY2022_Rx" SG_ 765 Btt_L_Actl 1;
BA_ "U_CDX706_MY2023_Rx" SG_ 765 Btt_L_Actl 1;
BA_ "GenSigStartValueInteger" SG_ 765 RearDiffLck_D_RqArb 3;
BA_ "GenSigStartValue" SG_ 765 RearDiffLck_D_RqArb 3;
BA_ "U_P702_MY2021_Rx" SG_ 765 RearDiffLck_D_RqArb 1;
BA_ "GenSigStartValueInteger" SG_ 765 AwdMde_D_RqArb 5;
BA_ "GenSigStartValue" SG_ 765 AwdMde_D_RqArb 5;
BA_ "U_P702_MY2021_Rx" SG_ 765 AwdMde_D_RqArb 1;
BA_ "U_P702_MY2021_Rx" SG_ 765 SelDrvMdeTxtReset_B_Rq 1;
BA_ "U_T6_MCA_MY2020_Rx" SG_ 765 SelDrvMdeTxtReset_B_Rq 1;
BA_ "U_U55X_MY2022_Rx" SG_ 765 SelDrvMdeTxtReset_B_Rq 1;
BA_ "U_CD764_MY2022_Rx" SG_ 765 SelDrvMdeTxtReset_B_Rq 1;
BA_ "U_U55X_MY2022_Rx" SG_ 765 AutoTowAllw_D_RqMnu 1;
BA_ "U_CDX706_MY2023_Rx" SG_ 765 AutoTowAllw_D_RqMnu 1;
BA_ "WakeupSignal" SG_ 765 DrvInputRequired_B_Rq 1;
BA_ "U_P702_MY2021_Rx" SG_ 765 SelDrvMdeDsply_B_Avail 1;
BA_ "U_T6_MCA_MY2020_Rx" SG_ 765 SelDrvMdeDsply_B_Avail 1;
BA_ "U_CD542_MY2021_Rx" SG_ 765 SelDrvMdeDsply_B_Avail 1;
BA_ "U_U55X_MY2022_Rx" SG_ 765 SelDrvMdeDsply_B_Avail 1;
BA_ "U_CD764_MY2022_Rx" SG_ 765 SelDrvMdeDsply_B_Avail 1;
BA_ "GenSigStartValueInteger" SG_ 765 EngExhMdeQuiet_D_Rq 2;
BA_ "GenSigStartValue" SG_ 765 EngExhMdeQuiet_D_Rq 2;
BA_ "U_CD764_MY2022_Rx" SG_ 765 Mc_VehUntTrpCoUsrSel_St 1;
BA_ "U_CDX706_MY2023_Rx" SG_ 765 Mc_VehUntTrpCoUsrSel_St 1;
BA_ "GenSigStartValueInteger" SG_ 765 AwdRnge_D_ActlIpc 7;
BA_ "GenSigStartValue" SG_ 765 AwdRnge_D_ActlIpc 7;
BA_ "U_P702_MY2021_Rx" SG_ 765 AwdRnge_D_ActlIpc 1;
BA_ "U_T6_MCA_MY2020_Rx" SG_ 765 AwdRnge_D_ActlIpc 1;
BA_ "U_CDX706_MY2023_Rx" SG_ 765 AwdRnge_D_ActlIpc 1;
BA_ "U_T6_MCA_MY2020_Rx" SG_ 765 BrkLineLck_D_Rq 1;
BA_ "U_T6_MCA_MY2020_Rx" SG_ 765 EdmSailMde_B_RqDrv 1;
BA_ "U_CDX706_MY2023_Rx" SG_ 765 EdmSailMde_B_RqDrv 1;
BA_ "GenSigStartValueInteger" SG_ 518 RearDiffLck_Tq_Actl2 16382;
BA_ "GenSigStartValue" SG_ 518 RearDiffLck_Tq_Actl2 16382;
BA_ "U_P702_MY2021_Rx" SG_ 518 RearDiffLck_Tq_Actl2 1;
BA_ "U_U55X_MY2022_Rx" SG_ 518 RearDiffLck_Tq_Actl2 1;
BA_ "GenSigStartValue" SG_ 518 LsdCluPlate_Te_Est 65;
BA_ "U_P702_MY2021_Rx" SG_ 559 EhData2_No_Actl 1;
BA_ "U_T6_MCA_MY2020_Rx" SG_ 559 EhData2_No_Actl 1;
BA_ "U_CD542_MY2021_Rx" SG_ 559 EhData2_No_Actl 1;
BA_ "U_U55X_MY2022_Rx" SG_ 559 EhData2_No_Actl 1;
BA_ "U_CD764_MY2022_Rx" SG_ 559 EhData2_No_Actl 1;
BA_ "U_CDX706_MY2023_Rx" SG_ 559 EhData2_No_Actl 1;
BA_ "U_P702_MY2021_Rx" SG_ 558 EhData1_No_Actl 1;
BA_ "U_T6_MCA_MY2020_Rx" SG_ 558 EhData1_No_Actl 1;
BA_ "U_CD542_MY2021_Rx" SG_ 558 EhData1_No_Actl 1;
BA_ "U_U55X_MY2022_Rx" SG_ 558 EhData1_No_Actl 1;
BA_ "U_CD764_MY2022_Rx" SG_ 558 EhData1_No_Actl 1;
BA_ "U_CDX706_MY2023_Rx" SG_ 558 EhData1_No_Actl 1;
BA_ "GenSigSendType" SG_ 934 CtaAlrtLeft2_D_Stat 3;
BA_ "U_T6_MCA_MY2020_Tx" SG_ 934 CtaAlrtLeft2_D_Stat 1;
BA_ "U_CD542_MY2021_Tx" SG_ 934 CtaAlrtLeft2_D_Stat 1;
BA_ "U_U55X_MY2022_Tx" SG_ 934 CtaAlrtLeft2_D_Stat 1;
BA_ "U_CD764_MY2022_Tx" SG_ 934 CtaAlrtLeft2_D_Stat 1;
BA_ "U_CDX706_MY2023_Tx" SG_ 934 CtaAlrtLeft2_D_Stat 1;
BA_ "GenSigSendType" SG_ 934 CtaBrkLeftMsgTxt_B_Rq 3;
BA_ "U_T6_MCA_MY2020_Tx" SG_ 934 CtaBrkLeftMsgTxt_B_Rq 1;
BA_ "U_CD542_MY2021_Tx" SG_ 934 CtaBrkLeftMsgTxt_B_Rq 1;
BA_ "U_U55X_MY2022_Tx" SG_ 934 CtaBrkLeftMsgTxt_B_Rq 1;
BA_ "U_CD764_MY2022_Tx" SG_ 934 CtaBrkLeftMsgTxt_B_Rq 1;
BA_ "U_CDX706_MY2023_Tx" SG_ 934 CtaBrkLeftMsgTxt_B_Rq 1;
BA_ "GenSigSendType" SG_ 934 CtaLeftBrkDecel_B_Rq 3;
BA_ "U_CX727_MY2021_Rx" SG_ 934 CtaLeftBrkDecel_B_Rq 1;
BA_ "U_P702_MY2021_Rx" SG_ 934 CtaLeftBrkDecel_B_Rq 1;
BA_ "U_T6_MCA_MY2020_Rx" SG_ 934 CtaLeftBrkDecel_B_Rq 1;
BA_ "U_CD542_MY2021_Rx" SG_ 934 CtaLeftBrkDecel_B_Rq 1;
BA_ "U_U55X_MY2022_Rx" SG_ 934 CtaLeftBrkDecel_B_Rq 1;
BA_ "U_CD764_MY2022_Rx" SG_ 934 CtaLeftBrkDecel_B_Rq 1;
BA_ "U_CDX706_MY2023_Rx" SG_ 934 CtaLeftBrkDecel_B_Rq 1;
BA_ "U_T6_MCA_MY2020_Tx" SG_ 934 CtaLeftBrkDecel_B_Rq 1;
BA_ "U_CD542_MY2021_Tx" SG_ 934 CtaLeftBrkDecel_B_Rq 1;
BA_ "U_U55X_MY2022_Tx" SG_ 934 CtaLeftBrkDecel_B_Rq 1;
BA_ "U_CD764_MY2022_Tx" SG_ 934 CtaLeftBrkDecel_B_Rq 1;
BA_ "U_CDX706_MY2023_Tx" SG_ 934 CtaLeftBrkDecel_B_Rq 1;
BA_ "GenSigSendType" SG_ 934 CtaLeftBrkEnbl_B_Rq 3;
BA_ "U_CX727_MY2021_Rx" SG_ 934 CtaLeftBrkEnbl_B_Rq 1;
BA_ "U_P702_MY2021_Rx" SG_ 934 CtaLeftBrkEnbl_B_Rq 1;
BA_ "U_T6_MCA_MY2020_Rx" SG_ 934 CtaLeftBrkEnbl_B_Rq 1;
BA_ "U_CD542_MY2021_Rx" SG_ 934 CtaLeftBrkEnbl_B_Rq 1;
BA_ "U_U55X_MY2022_Rx" SG_ 934 CtaLeftBrkEnbl_B_Rq 1;
BA_ "U_CD764_MY2022_Rx" SG_ 934 CtaLeftBrkEnbl_B_Rq 1;
BA_ "U_CDX706_MY2023_Rx" SG_ 934 CtaLeftBrkEnbl_B_Rq 1;
BA_ "U_T6_MCA_MY2020_Tx" SG_ 934 CtaLeftBrkEnbl_B_Rq 1;
BA_ "U_CD542_MY2021_Tx" SG_ 934 CtaLeftBrkEnbl_B_Rq 1;
BA_ "U_U55X_MY2022_Tx" SG_ 934 CtaLeftBrkEnbl_B_Rq 1;
BA_ "U_CD764_MY2022_Tx" SG_ 934 CtaLeftBrkEnbl_B_Rq 1;
BA_ "U_CDX706_MY2023_Tx" SG_ 934 CtaLeftBrkEnbl_B_Rq 1;
BA_ "GenSigStartValueInteger" SG_ 934 Side_Detect_L_Illum 100;
BA_ "GenSigStartValue" SG_ 934 Side_Detect_L_Illum 100;
BA_ "U_T6_MCA_MY2020_Tx" SG_ 934 Side_Detect_L_Illum 1;
BA_ "U_CD542_MY2021_Tx" SG_ 934 Side_Detect_L_Illum 1;
BA_ "U_U55X_MY2022_Tx" SG_ 934 Side_Detect_L_Illum 1;
BA_ "U_CD764_MY2022_Tx" SG_ 934 Side_Detect_L_Illum 1;
BA_ "U_CDX706_MY2023_Tx" SG_ 934 Side_Detect_L_Illum 1;
BA_ "GenSigSendType" SG_ 934 BttLeft_D_Stat 3;
BA_ "U_T6_MCA_MY2020_Tx" SG_ 934 BttLeft_D_Stat 1;
BA_ "U_CD542_MY2021_Tx" SG_ 934 BttLeft_D_Stat 1;
BA_ "U_U55X_MY2022_Tx" SG_ 934 BttLeft_D_Stat 1;
BA_ "U_CD764_MY2022_Tx" SG_ 934 BttLeft_D_Stat 1;
BA_ "GenSigSendType" SG_ 934 BttLeft_D_RqDrv 3;
BA_ "U_T6_MCA_MY2020_Tx" SG_ 934 BttLeft_D_RqDrv 1;
BA_ "U_CD542_MY2021_Tx" SG_ 934 BttLeft_D_RqDrv 1;
BA_ "U_U55X_MY2022_Tx" SG_ 934 BttLeft_D_RqDrv 1;
BA_ "U_CD764_MY2022_Tx" SG_ 934 BttLeft_D_RqDrv 1;
BA_ "GenSigSendType" SG_ 934 CtaSnsLeft_D_Stat 3;
BA_ "U_T6_MCA_MY2020_Tx" SG_ 934 CtaSnsLeft_D_Stat 1;
BA_ "U_CD542_MY2021_Tx" SG_ 934 CtaSnsLeft_D_Stat 1;
BA_ "U_U55X_MY2022_Tx" SG_ 934 CtaSnsLeft_D_Stat 1;
BA_ "U_CD764_MY2022_Tx" SG_ 934 CtaSnsLeft_D_Stat 1;
BA_ "U_CDX706_MY2023_Tx" SG_ 934 CtaSnsLeft_D_Stat 1;
BA_ "GenSigSendType" SG_ 934 SodDetctLeft_D_Stat 3;
BA_ "U_T6_MCA_MY2020_Tx" SG_ 934 SodDetctLeft_D_Stat 1;
BA_ "U_CD542_MY2021_Tx" SG_ 934 SodDetctLeft_D_Stat 1;
BA_ "U_U55X_MY2022_Tx" SG_ 934 SodDetctLeft_D_Stat 1;
BA_ "U_CD764_MY2022_Tx" SG_ 934 SodDetctLeft_D_Stat 1;
BA_ "U_CDX706_MY2023_Tx" SG_ 934 SodDetctLeft_D_Stat 1;
BA_ "GenSigSendType" SG_ 934 CtaLeft_D_Stat 3;
BA_ "U_T6_MCA_MY2020_Tx" SG_ 934 CtaLeft_D_Stat 1;
BA_ "U_CD542_MY2021_Tx" SG_ 934 CtaLeft_D_Stat 1;
BA_ "U_U55X_MY2022_Tx" SG_ 934 CtaLeft_D_Stat 1;
BA_ "U_CD764_MY2022_Tx" SG_ 934 CtaLeft_D_Stat 1;
BA_ "U_CDX706_MY2023_Tx" SG_ 934 CtaLeft_D_Stat 1;
BA_ "GenSigSendType" SG_ 934 CtaAlrtLeft_D_Stat 3;
BA_ "U_T6_MCA_MY2020_Tx" SG_ 934 CtaAlrtLeft_D_Stat 1;
BA_ "U_CD542_MY2021_Tx" SG_ 934 CtaAlrtLeft_D_Stat 1;
BA_ "U_U55X_MY2022_Tx" SG_ 934 CtaAlrtLeft_D_Stat 1;
BA_ "U_CD764_MY2022_Tx" SG_ 934 CtaAlrtLeft_D_Stat 1;
BA_ "U_CDX706_MY2023_Tx" SG_ 934 CtaAlrtLeft_D_Stat 1;
BA_ "GenSigSendType" SG_ 934 SodLeft_D_Stat 3;
BA_ "GenSigStartValueInteger" SG_ 934 SodLeft_D_Stat 2;
BA_ "GenSigStartValue" SG_ 934 SodLeft_D_Stat 2;
BA_ "U_T6_MCA_MY2020_Tx" SG_ 934 SodLeft_D_Stat 1;
BA_ "U_CD542_MY2021_Tx" SG_ 934 SodLeft_D_Stat 1;
BA_ "U_U55X_MY2022_Tx" SG_ 934 SodLeft_D_Stat 1;
BA_ "U_CD764_MY2022_Tx" SG_ 934 SodLeft_D_Stat 1;
BA_ "U_CDX706_MY2023_Tx" SG_ 934 SodLeft_D_Stat 1;
BA_ "GenSigSendType" SG_ 934 SodSnsLeft_D_Stat 3;
BA_ "U_T6_MCA_MY2020_Tx" SG_ 934 SodSnsLeft_D_Stat 1;
BA_ "U_CD542_MY2021_Tx" SG_ 934 SodSnsLeft_D_Stat 1;
BA_ "U_U55X_MY2022_Tx" SG_ 934 SodSnsLeft_D_Stat 1;
BA_ "U_CD764_MY2022_Tx" SG_ 934 SodSnsLeft_D_Stat 1;
BA_ "U_CDX706_MY2023_Tx" SG_ 934 SodSnsLeft_D_Stat 1;
BA_ "GenSigSendType" SG_ 934 SodAlrtLeft_D_Stat 3;
BA_ "U_T6_MCA_MY2020_Tx" SG_ 934 SodAlrtLeft_D_Stat 1;
BA_ "U_CD542_MY2021_Tx" SG_ 934 SodAlrtLeft_D_Stat 1;
BA_ "U_U55X_MY2022_Tx" SG_ 934 SodAlrtLeft_D_Stat 1;
BA_ "U_CD764_MY2022_Tx" SG_ 934 SodAlrtLeft_D_Stat 1;
BA_ "U_CDX706_MY2023_Tx" SG_ 934 SodAlrtLeft_D_Stat 1;
BA_ "GenSigStartValueInteger" SG_ 934 SodWarnLeft_Prd_Rq 14;
BA_ "GenSigStartValue" SG_ 934 SodWarnLeft_Prd_Rq 14;
BA_ "U_T6_MCA_MY2020_Tx" SG_ 934 SodWarnLeft_Prd_Rq 1;
BA_ "U_CD542_MY2021_Tx" SG_ 934 SodWarnLeft_Prd_Rq 1;
BA_ "U_U55X_MY2022_Tx" SG_ 934 SodWarnLeft_Prd_Rq 1;
BA_ "U_CD764_MY2022_Tx" SG_ 934 SodWarnLeft_Prd_Rq 1;
BA_ "U_CDX706_MY2023_Tx" SG_ 934 SodWarnLeft_Prd_Rq 1;
BA_ "U_P702_MY2021_Rx" SG_ 825 LscmbbEngTqMn_B_Rq 1;
BA_ "U_P702_MY2021_Rx" SG_ 825 LscmbbDeny_B_Actl 1;
BA_ "U_P702_MY2021_Rx" SG_ 825 LscmbbBrkPrchg_D_Rq 1;
BA_ "MetaData" SG_ 825 LscmbbBrkDecel_No_Cs 1;
BA_ "U_P702_MY2021_Rx" SG_ 825 LscmbbBrkDecel_No_Cs 1;
BA_ "MetaData" SG_ 825 LscmbbBrkDecel_No_Cnt 1;
BA_ "U_P702_MY2021_Rx" SG_ 825 LscmbbBrkDecel_No_Cnt 1;
BA_ "U_P702_MY2021_Rx" SG_ 825 LscmbbBrkDecel_B_Enbl 1;
BA_ "GenSigStartValueInteger" SG_ 825 LscmbbBrkDecel_A_Rq 255;
BA_ "U_P702_MY2021_Rx" SG_ 825 LscmbbBrkDecel_A_Rq 1;
BA_ "U_P702_MY2021_Rx" SG_ 825 LscmbbBaSens_D_Rq 1;
BA_ "U_P702_MY2021_Rx" SG_ 1072 DrvSlipCtlMde_D_Rq 1;
BA_ "U_T6_MCA_MY2020_Rx" SG_ 1072 DrvSlipCtlMde_D_Rq 1;
BA_ "U_CD542_MY2021_Rx" SG_ 1072 DrvSlipCtlMde_D_Rq 1;
BA_ "U_U55X_MY2022_Rx" SG_ 1072 DrvSlipCtlMde_D_Rq 1;
BA_ "U_CD764_MY2022_Rx" SG_ 1072 DrvSlipCtlMde_D_Rq 1;
BA_ "U_CDX706_MY2023_Rx" SG_ 1072 DrvSlipCtlMde_D_Rq 1;
BA_ "U_CX727_MY2021_Rx" SG_ 1072 EngIdlShutDown_B_RqDrv 1;
BA_ "U_P702_MY2021_Rx" SG_ 1072 EngIdlShutDown_B_RqDrv 1;
BA_ "U_T6_MCA_MY2020_Rx" SG_ 1072 EngIdlShutDown_B_RqDrv 1;
BA_ "U_CD542_MY2021_Rx" SG_ 1072 EngIdlShutDown_B_RqDrv 1;
BA_ "U_U55X_MY2022_Rx" SG_ 1072 EngIdlShutDown_B_RqDrv 1;
BA_ "U_CD764_MY2022_Rx" SG_ 1072 EngIdlShutDown_B_RqDrv 1;
BA_ "U_CDX706_MY2023_Rx" SG_ 1072 EngIdlShutDown_B_RqDrv 1;
BA_ "GenSigStartValueInteger" SG_ 1072 HsaMde_D_Rq 1;
BA_ "GenSigStartValue" SG_ 1072 HsaMde_D_Rq 1;
BA_ "U_CX727_MY2021_Rx" SG_ 1072 HsaMde_D_Rq 1;
BA_ "U_T6_MCA_MY2020_Rx" SG_ 1072 HsaMde_D_Rq 1;
BA_ "U_CD542_MY2021_Rx" SG_ 1072 HsaMde_D_Rq 1;
BA_ "U_U55X_MY2022_Rx" SG_ 1072 HsaMde_D_Rq 1;
BA_ "U_CD764_MY2022_Rx" SG_ 1072 HsaMde_D_Rq 1;
BA_ "U_CDX706_MY2023_Rx" SG_ 1072 HsaMde_D_Rq 1;
BA_ "U_P702_MY2021_Rx" SG_ 1072 StopStrtDrvMde_D_RqMnu 1;
BA_ "U_T6_MCA_MY2020_Rx" SG_ 1072 StopStrtDrvMde_D_RqMnu 1;
BA_ "U_CD542_MY2021_Rx" SG_ 1072 StopStrtDrvMde_D_RqMnu 1;
BA_ "U_U55X_MY2022_Rx" SG_ 1072 StopStrtDrvMde_D_RqMnu 1;
BA_ "U_CX727_MY2021_Rx" SG_ 1072 NtrlTowMdeEnbl_B_RqDrv 1;
BA_ "U_P702_MY2021_Rx" SG_ 1072 NtrlTowMdeEnbl_B_RqDrv 1;
BA_ "U_T6_MCA_MY2020_Rx" SG_ 1072 NtrlTowMdeEnbl_B_RqDrv 1;
BA_ "U_CD542_MY2021_Rx" SG_ 1072 NtrlTowMdeEnbl_B_RqDrv 1;
BA_ "U_U55X_MY2022_Rx" SG_ 1072 NtrlTowMdeEnbl_B_RqDrv 1;
BA_ "U_CD764_MY2022_Rx" SG_ 1072 NtrlTowMdeEnbl_B_RqDrv 1;
BA_ "U_CDX706_MY2023_Rx" SG_ 1072 NtrlTowMdeEnbl_B_RqDrv 1;
BA_ "U_P702_MY2021_Rx" SG_ 1072 ParkDetect_Stat 1;
BA_ "U_CD542_MY2021_Rx" SG_ 1072 ParkDetect_Stat 1;
BA_ "U_P702_MY2021_Rx" SG_ 1072 FrostWarn_D_Stat 1;
BA_ "U_T6_MCA_MY2020_Rx" SG_ 1072 FrostWarn_D_Stat 1;
BA_ "U_CD542_MY2021_Rx" SG_ 1072 FrostWarn_D_Stat 1;
BA_ "U_U55X_MY2022_Rx" SG_ 1072 FrostWarn_D_Stat 1;
BA_ "U_P702_MY2021_Rx" SG_ 1072 TRLR_SWAY_CONFIG_CMD 1;
BA_ "U_T6_MCA_MY2020_Rx" SG_ 1072 TRLR_SWAY_CONFIG_CMD 1;
BA_ "U_CD542_MY2021_Rx" SG_ 1072 TRLR_SWAY_CONFIG_CMD 1;
BA_ "U_U55X_MY2022_Rx" SG_ 1072 TRLR_SWAY_CONFIG_CMD 1;
BA_ "U_CD764_MY2022_Rx" SG_ 1072 TRLR_SWAY_CONFIG_CMD 1;
BA_ "U_CDX706_MY2023_Rx" SG_ 1072 TRLR_SWAY_CONFIG_CMD 1;
BA_ "WakeupSignal" SG_ 1072 Power_Liftgate_Mode_Cmd 1;
BA_ "GenSigStartValueInteger" SG_ 1072 AccEnbl_B_RqDrv 1;
BA_ "GenSigStartValue" SG_ 1072 AccEnbl_B_RqDrv 1;
BA_ "U_T6_MCA_MY2020_Rx" SG_ 1072 AccEnbl_B_RqDrv 1;
BA_ "U_CD542_MY2021_Rx" SG_ 1072 AccEnbl_B_RqDrv 1;
BA_ "U_U55X_MY2022_Rx" SG_ 1072 AccEnbl_B_RqDrv 1;
BA_ "U_CD764_MY2022_Rx" SG_ 1072 AccEnbl_B_RqDrv 1;
BA_ "U_CDX706_MY2023_Rx" SG_ 1072 AccEnbl_B_RqDrv 1;
BA_ "U_CX727_MY2021_Rx" SG_ 1072 OdometerMasterValue 1;
BA_ "U_P702_MY2021_Rx" SG_ 1072 OdometerMasterValue 1;
BA_ "U_T6_MCA_MY2020_Rx" SG_ 1072 OdometerMasterValue 1;
BA_ "U_CD542_MY2021_Rx" SG_ 1072 OdometerMasterValue 1;
BA_ "U_U55X_MY2022_Rx" SG_ 1072 OdometerMasterValue 1;
BA_ "U_CD764_MY2022_Rx" SG_ 1072 OdometerMasterValue 1;
BA_ "U_CDX706_MY2023_Rx" SG_ 1072 OdometerMasterValue 1;
BA_ "U_CX727_MY2021_Rx" SG_ 1072 EngOilLife_B_RqReset 1;
BA_ "U_P702_MY2021_Rx" SG_ 1072 EngOilLife_B_RqReset 1;
BA_ "U_T6_MCA_MY2020_Rx" SG_ 1072 EngOilLife_B_RqReset 1;
BA_ "U_CD542_MY2021_Rx" SG_ 1072 EngOilLife_B_RqReset 1;
BA_ "U_U55X_MY2022_Rx" SG_ 1072 EngOilLife_B_RqReset 1;
BA_ "U_CD764_MY2022_Rx" SG_ 1072 EngOilLife_B_RqReset 1;
BA_ "U_CDX706_MY2023_Rx" SG_ 1072 EngOilLife_B_RqReset 1;
BA_ "U_T6_MCA_MY2020_Rx" SG_ 1072 AccDeny_B_RqIpc 1;
BA_ "U_CD542_MY2021_Rx" SG_ 1072 AccDeny_B_RqIpc 1;
BA_ "U_U55X_MY2022_Rx" SG_ 1072 AccDeny_B_RqIpc 1;
BA_ "U_CD764_MY2022_Rx" SG_ 1072 AccDeny_B_RqIpc 1;
BA_ "U_CDX706_MY2023_Rx" SG_ 1072 AccDeny_B_RqIpc 1;
BA_ "WakeupSignal" SG_ 1072 ePRNDL_MODE 1;
BA_ "U_CX727_MY2021_Rx" SG_ 1072 ePRNDL_MODE 1;
BA_ "U_P702_MY2021_Rx" SG_ 1072 ePRNDL_MODE 1;
BA_ "U_T6_MCA_MY2020_Rx" SG_ 1072 ePRNDL_MODE 1;
BA_ "U_CD542_MY2021_Rx" SG_ 1072 ePRNDL_MODE 1;
BA_ "U_U55X_MY2022_Rx" SG_ 1072 ePRNDL_MODE 1;
BA_ "U_CD764_MY2022_Rx" SG_ 1072 ePRNDL_MODE 1;
BA_ "U_CDX706_MY2023_Rx" SG_ 1072 ePRNDL_MODE 1;
BA_ "U_P702_MY2021_Rx" SG_ 1072 DrvSlipCtlMde_B_Rq2 1;
BA_ "U_T6_MCA_MY2020_Rx" SG_ 1072 DrvSlipCtlMde_B_Rq2 1;
BA_ "U_U55X_MY2022_Rx" SG_ 1072 DrvSlipCtlMde_B_Rq2 1;
BA_ "U_CX727_MY2021_Rx" SG_ 1072 MetricActv_B_Actl 1;
BA_ "U_P702_MY2021_Rx" SG_ 1072 MetricActv_B_Actl 1;
BA_ "U_T6_MCA_MY2020_Rx" SG_ 1072 MetricActv_B_Actl 1;
BA_ "U_CD542_MY2021_Rx" SG_ 1072 MetricActv_B_Actl 1;
BA_ "U_U55X_MY2022_Rx" SG_ 1072 MetricActv_B_Actl 1;
BA_ "U_CD764_MY2022_Rx" SG_ 1072 MetricActv_B_Actl 1;
BA_ "U_CDX706_MY2023_Rx" SG_ 1072 MetricActv_B_Actl 1;
BA_ "U_P702_MY2021_Rx" SG_ 1072 ManRgen_D_Rq 1;
BA_ "U_T6_MCA_MY2020_Rx" SG_ 1072 ManRgen_D_Rq 1;
BA_ "U_T6_MCA_MY2020_Rx" SG_ 1072 HaDsplyCpblty_B_Stat 1;
BA_ "U_U55X_MY2022_Rx" SG_ 1072 HaDsplyCpblty_B_Stat 1;
BA_ "U_CD764_MY2022_Rx" SG_ 1072 HaDsplyCpblty_B_Stat 1;
BA_ "U_CDX706_MY2023_Rx" SG_ 1072 HaDsplyCpblty_B_Stat 1;
BA_ "WakeupSignal" SG_ 909 IgnPsswrdDsply_B_Rq 1;
BA_ "WakeupSignal" SG_ 909 ElPwPoint_D_Rq 1;
BA_ "GenSigStartValueInteger" SG_ 909 WiprFront_D_Stat2 15;
BA_ "GenSigStartValue" SG_ 909 WiprFront_D_Stat2 15;
BA_ "U_T6_MCA_MY2020_Rx" SG_ 909 WiprFront_D_Stat2 1;
BA_ "GenSigStartValueInteger" SG_ 909 HeadLghtHiPrmsn_D_Stat 3;
BA_ "GenSigStartValue" SG_ 909 HeadLghtHiPrmsn_D_Stat 3;
BA_ "U_CX727_MY2021_Rx" SG_ 909 HeadLghtHiPrmsn_D_Stat 1;
BA_ "U_P702_MY2021_Rx" SG_ 909 HeadLghtHiPrmsn_D_Stat 1;
BA_ "U_T6_MCA_MY2020_Rx" SG_ 909 HeadLghtHiPrmsn_D_Stat 1;
BA_ "U_CD542_MY2021_Rx" SG_ 909 HeadLghtHiPrmsn_D_Stat 1;
BA_ "U_U55X_MY2022_Rx" SG_ 909 HeadLghtHiPrmsn_D_Stat 1;
BA_ "U_CD764_MY2022_Rx" SG_ 909 HeadLghtHiPrmsn_D_Stat 1;
BA_ "U_CDX706_MY2023_Rx" SG_ 909 HeadLghtHiPrmsn_D_Stat 1;
BA_ "WakeupSignal" SG_ 909 immoMsgTxt_D_Rq 1;
BA_ "WakeupSignal" SG_ 909 PrsnlDevcChrgEnbl_B_Rq 1;
BA_ "MetaData" SG_ 909 KeyMykeyTot_No_Cnt 1;
BA_ "MetaData" SG_ 909 KeyAdmnTot_No_Cnt 1;
BA_ "WakeupSignal" SG_ 909 HazrdLght_B_Stat 1;
VAL_ 936 ApaSys_D_Stat 7 "Faulty" 6 "Finished" 5 "NotAccessible" 4 "ApaCancelled" 3 "Overspeed" 2 "On" 1 "Off" 0 "Null" ;
VAL_ 936 ApaSteWhl_D_RqDrv 3 "TakeControl" 2 "RemoveHands" 1 "NoRequest" 0 "Null" ;
VAL_ 936 ApaSteScanMde_D_Stat 3 "Steering" 2 "Scanning" 1 "NotScanning" 0 "Null" ;
VAL_ 936 ApaSelSapp_D_Stat 3 "NotConfigured" 2 "NotSelectable" 1 "Selectable" 0 "Null" ;
VAL_ 936 ApaSelPpa_D_Stat 3 "NotConfigured" 2 "NotSelectable" 1 "Selectable" 0 "Null" ;
VAL_ 936 ApaSelPoa_D_Stat 3 "NotConfigured" 2 "NotSelectable" 1 "Selectable" 0 "Null" ;
VAL_ 936 ApaScan_D_Stat 3 "ParkSlotReady" 2 "ParkSlotFound" 1 "NoParkSlot" 0 "Null" ;
VAL_ 936 ApaLongCtl_D_RqDrv 7 "NotUsed3" 6 "NotUsed2" 5 "ReleaseBrake" 4 "DriveBackward" 3 "DriveForward" 2 "Stop" 1 "NoRequest" 0 "Null" ;
VAL_ 936 ApaGearShif_D_RqDrv 7 "NotUSed2" 6 "NotUsed1" 5 "ShiftToP" 4 "ShiftToN" 3 "ShiftToD" 2 "ShiftToR" 1 "NoRequest" 0 "Null" ;
VAL_ 936 ApaActvSide2_D_Stat 3 "NoSide" 2 "Right" 1 "Left" 0 "Null" ;
VAL_ 936 ApaAcsy_D_RqDrv 7 "CloseDoor" 6 "SelectSideRight" 5 "SelectSideLeft" 4 "CheckForObject" 3 "PressApaButton" 2 "SelectSide" 1 "NoRequest" 0 "Null" ;
VAL_ 936 ApaTrgtDist_D_Stat 15 "Step15" 14 "Step14" 13 "Step13" 12 "Step12" 11 "Step11" 10 "Step10" 9 "Step9" 8 "Step8" 7 "Step7" 6 "Step6" 5 "Step5" 4 "Step4" 3 "Step3" 2 "Step2" 1 "Step1" 0 "Off" ;
VAL_ 936 ApaMsgTxt_D_Rq 15 "NotUsed_6" 14 "NotUsed_5" 13 "NotUsed_4" 12 "NotUsed_3" 11 "ReleaseEpb" 10 "TrailerFeatureNotAvailable" 9 "AccelPedalInactive" 8 "WrongDirection" 7 "SteeringInteraction" 6 "BrakingActive" 5 "HighInclination" 4 "SpeedLimitExceeded" 3 "TcsDisabled" 2 "WheelSlip" 1 "None" 0 "Null" ;
VAL_ 936 ApaChime_D_Rq 7 "NotUsed2" 6 "NotUsed1" 5 "Warning_Chime" 4 "Finish_Chime" 3 "Stop_Now_Chime" 2 "Spot_Ready_Chime" 1 "Spot_Found_Chime" 0 "No_Chime" ;
VAL_ 936 EPASExtAngleStatReq 1 "Request" 0 "NoRequest" ;
VAL_ 936 ExtSteeringAngleReq2 32767 "Invalid" 32766 "Unknown" ;
VAL_ 936 ApaButtnPrssd_B_Stat 1 "Pressed" 0 "Not_Pressed" ;
VAL_ 877 VehElEffAvg_No_Dsply 127 "Faulty" 126 "NoDataExists" ;
VAL_ 877 PwFlwFuelDrv_D_Dsply 7 "NotUsed_4" 6 "NotUsed_3" 5 "NotUsed_2" 4 "NotUsed_1" 3 "FlwFromFuelToAllWhls" 2 "FlwFromFuelToFrontWhls" 1 "FlwFromFuelToRearWhls" 0 "NoFlow" ;
VAL_ 877 PwFlwFuelClimt_B_Dsply 1 "On" 0 "Off" ;
VAL_ 877 PwFlwFuelBatt_B_Dsply 1 "On" 0 "Off" ;
VAL_ 877 PwFlwBattGen_D_Dsply 1 "On" 0 "Off" ;
VAL_ 877 PwFlwBattClimt_B_Dsply 1 "On" 0 "Off" ;
VAL_ 877 PwFlwBatt_D_Dsply 15 "NotUsed_8" 14 "NotUsed_7" 13 "NotUsed_6" 12 "NotUsed_5" 11 "NotUsed_4" 10 "NotUsed_3" 9 "NotUsed_2" 8 "NotUsed_1" 7 "FlwFromWallToBatt" 6 "FlwFromAllWhlsToBatt" 5 "FlwFromBattToAllWhls" 4 "FlwFromFrontWhlsToBatt" 3 "FlwFromBattToFrontWhls" 2 "FlwFromRearWhlsToBatt" 1 "FlwFromBattToRearWhls" 0 "NoFlow" ;
VAL_ 877 RngPerChrgAvg_L2_Dsply 8191 "Faulty" 8190 "NoDataExists" ;
VAL_ 791 AwdDrvMde_D2_Rq 15 "Faulty" 14 "NotUsed_7" 13 "NotUsed_6" 12 "NotUsed_5" 11 "NotUsed_4" 10 "NotUsed_3" 9 "NotUsed_2" 8 "NotUsed_1" 7 "NotAvailable" 6 "TowHaul" 5 "RockCrawl" 4 "Baja" 3 "MudAndSand" 2 "Weather" 1 "Sport" 0 "Normal" ;
VAL_ 791 StopStrtVThres_D_RqMnu 3 "High" 2 "Medium" 1 "Low" 0 "NoSelection" ;
VAL_ 791 EngAirFilt_B_RqReset 1 "Yes" 0 "No" ;
VAL_ 791 BattElEmotive_Pc_Dsply 1023 "Faulty" 1022 "NoDataExists" ;
VAL_ 791 HybMdeOvrrd_D_Rq 3 "NotUsed" 2 "Invalid" 1 "Override" 0 "Null" ;
VAL_ 791 GpsElMdeSel_B_Rq 1 "On" 0 "Off" ;
VAL_ 791 LongTermReset_B_Rq 1 "On" 0 "Off" ;
VAL_ 791 EcoCcActv_B_Rq 1 "On" 0 "Off" ;
VAL_ 791 DrvEffLvl_No_Stat 63 "Fault" 62 "NoDataExists" ;
VAL_ 791 ChargeProfIDPref_Rq 3 "NotUsed" 2 "Value" 1 "ChargeNow" 0 "Inactive" ;
VAL_ 791 GrdAsstAllw_D_RqMnu 3 "NotUsed" 2 "On" 1 "Off" 0 "NoModeSelected" ;
VAL_ 791 PlgOvrrdStrt_D_Cmd 3 "NotUsed" 2 "Override_Plug_Status" 1 "Dont_Override_Plug_Status" 0 "Null_State" ;
VAL_ 791 EcoMde_D_RqMnu 3 "NotUsed" 2 "On" 1 "Off" 0 "Null" ;
VAL_ 791 EmotiveType_D_Dsply 3 "EmotiveDisplay_3" 2 "EmotiveDisplay_2" 1 "EmotiveDisplay_1" 0 "Null" ;
VAL_ 791 VehElEffTrip2Reset_B_Rq 1 "On" 0 "Off" ;
VAL_ 791 VehElEffTrip1Reset_B_Rq 1 "On" 0 "Off" ;
VAL_ 786 VehElRngeCyc_L_Dsply 4095 "Faulty" 4094 "NoDataExists" ;
VAL_ 786 RgenTrip_L_Dsply 65535 "Fault" 65534 "NoDataExists" ;
VAL_ 786 PtDataKeyId_D_Stat 15 "NotUsed5" 14 "NotUsed4" 13 "NotUsed3" 12 "NotUsed2" 11 "NotUsed1" 10 "Tot_Veh_NUT" 9 "Cust_4_NUT" 8 "Cust_3_NUT" 7 "Cust_2_NUT" 6 "Cust_1_NUT" 5 "Tot_Veh_Stat" 4 "Cust_4_Stat" 3 "Cust_3_Stat" 2 "Cust_2_Stat" 1 "Cust_1_Stat" 0 "Null" ;
VAL_ 786 ChrgStat_D_Dsply 7 "NotUsed" 6 "Complete" 5 "Scheduled" 4 "In_Progress" 3 "Fault_Outside_Car" 2 "Fault_Inside_Car" 1 "Fault_Unknown_Location" 0 "Not_Ready" ;
VAL_ 786 VehElRnge_L2_Dsply 8191 "Faulty" 8190 "NoDataExists" ;
VAL_ 748 ChrgrOutHi_U_Actl 511 "Invalid" ;
VAL_ 748 ChrgrOutHi_I_Actl 4095 "Invalid" ;
VAL_ 748 ChrgrInPwType_D_Actl 6 "NotUsed3" 5 "NotUsed2" 4 "NotUsed1" 3 "DC_Fast_Charging" 2 "AC_Level2_240v" 1 "AC_Level1_120v" 0 "EVSE_Not_Detected" ;
VAL_ 748 ChrgrIn_Pw_Mx 4095 "Fault" ;
VAL_ 748 PtWakeupActv3_B_Rq 1 "On" 0 "Off" ;
VAL_ 748 PlgActv_D_ActlChrgr 3 "Faulty" 2 "NoDataExists" 1 "On_Plug__Connected_" 0 "Off_Plug__Disconnected_" ;
VAL_ 748 ChrgrRdyStat_D_Actl 7 "NotUsed4" 6 "NotUsed3" 5 "NotUsed2" 4 "NotUsed1" 3 "Charging" 2 "ChargerFault" 1 "ChargerReady" 0 "NotReady" ;
VAL_ 740 BattDcChrg_U_Actl 1023 "Faulty" 1022 "NoDataExists" ;
VAL_ 740 BattChrgMde_D_Actl 3 "NotUsed" 2 "ConstantCurrent" 1 "ConstantVoltage" 0 "NotCharging" ;
VAL_ 740 BattAuxCnnct_B_Cmd 1 "Close" 0 "Open" ;
VAL_ 740 PtWakeupActv2_B_Rq 1 "On" 0 "Off" ;
VAL_ 740 BattChrgCnnct_B_Cmd 1 "Close" 0 "Open" ;
VAL_ 604 EngFuelCutFull_B_Rq 1 "FuelCutRequest" 0 "NormalOperation" ;
VAL_ 604 PrplWhlMx_Tq_Allw 65535 "Fault" ;
VAL_ 604 PrplWhlMn_Tq_CmprBrk 4095 "Fault" ;
VAL_ 604 EngAout_Tq_EstHtrn 2047 "Fault" ;
VAL_ 604 EngStrtSmooth_D_Rq 7 "NotUsed" 6 "Smooth_NoPedal" 5 "Smooth_LightPedal" 4 "Smooth_MediumPedal" 3 "Smooth_HeavyPedal" 2 "Smooth_WOP" 1 "Smooth_Cold" 0 "Smooth_ExtremeCold" ;
VAL_ 604 EngMde_D_Rq 8 "VSC_Sets_Speed_Type_3" 7 "VSC_Sets_Speed_Type_2" 6 "VSC_Sets_Torque_Type_2" 5 "Dependability_Shutdown" 4 "Dependability_Follow" 3 "Start" 2 "VSC_Sets_Torque_Type_1" 1 "VSC_Sets_Speed_Type_1" 0 "Off" 15 "Undefined_7" 14 "Undefined_6" 13 "Undefined_5" 12 "Undefined_4" 11 "Undefined_3" 10 "Undefined_2" 9 "Undefined_1" ;
VAL_ 604 EngStrtCold_B_Rq 1 "ExtremeColdStart" 0 "NormalStart" ;
VAL_ 604 EngFuelCutFull_B_Sched 1 "DFSO_Event_Scheduled" 0 "Normal" ;
VAL_ 604 ApedBrkOvrrd_B_Enbl 1 "Yes" 0 "No" ;
VAL_ 604 EngStopFst_B_Rq 1 "FastEngineShutdown" 0 "NormalOperation" ;
VAL_ 589 DcdcUHi2_I_Actl 2047 "Faulty" ;
VAL_ 588 HvacAirFlw_B_RqBatt 1 "Request" 0 "NoRequest" ;
VAL_ 588 BattChrgRdyStat_D_Actl 7 "NotUsed2" 6 "NotUsed1" 5 "Faulted" 4 "ChargeComplete" 3 "Charging" 2 "BatteryChargeReady" 1 "ChargeWait" 0 "NotReady" ;
VAL_ 588 BattTracSoc2_Pc_Actl 16383 "Faulty" 16382 "NoDataExists" ;
VAL_ 588 BattTracSoc_Pc_Dsply 255 "Faulty" 254 "NoDataExists" ;
VAL_ 588 BattTracCool_D_Falt 3 "NotUsed" 2 "CoolSysPartialyOperational" 1 "Cooling_System_Faulted" 0 "Cooling_System_Operational" ;
VAL_ 588 BattTracClntIn_Te_Actl 255 "Fault" ;
VAL_ 588 BattTrac_Te_Actl 1023 "Fault" 1022 "Unknown" ;
VAL_ 588 HvacRec_D_RqMxBatt 15 "NotUsed5" 14 "NotUsed4" 13 "NotUsed3" 12 "NotUsed2" 11 "NotUsed1" 10 "No_Override" 9 "90Percent_RecircMax" 8 "80Percent_RecircMax" 7 "70Percent_RecircMax" 6 "60Percent_RecircMax" 5 "50Percent_RecircMax" 4 "40Percent_RecircMax" 3 "30Percent_RecircMax" 2 "20Percent_RecircMax" 1 "10Percent_RecircMax" 0 "0Percent_RecircFullOpen" ;
VAL_ 588 HvacAir_Flw_EstBatt 255 "Invalid" ;
VAL_ 587 BattTracClnt_Te_Actl 255 "Faulty" 254 "NoDataExists" ;
VAL_ 587 PwSrcULoMde_D_Actl 3 "BuckSpecial" 2 "ReverseBoost" 1 "ForwardBuck" 0 "Standby" ;
VAL_ 587 BattTracWarnLamp_B_Rq 1 "On" 0 "Off" ;
VAL_ 587 BattTracSrvcRqd_B_Rq 1 "On" 0 "Off" ;
VAL_ 389 HtrnOvrTeLamp_B_Dsply 1 "On" 0 "Off" ;
VAL_ 389 HtrnMil_D_Rq 3 "Not_Used" 2 "Flash" 1 "On" 0 "Off" ;
VAL_ 389 HtrnAin_UHi_Actl 1023 "Fault" 1022 "Unknown" ;
VAL_ 389 HtrnSrvcRqd_B_Dsply 1 "On" 0 "Off" ;
VAL_ 389 HtrnHvilOpen_B_Actl 1 "HVIL_is_Open" 0 "Normal_Operation" ;
VAL_ 389 PtWakeupDeltaT_T_Rq 2047 "Fault" 2046 "NoDataExists" ;
VAL_ 389 PreCondActv_B_Actl 1 "On" 0 "Off" ;
VAL_ 389 DrvCondTpRrDefrs_B_Rq 1 "On" 0 "Off" ;
VAL_ 389 BattTrac_I_EstVsc 32767 "Fault" 32766 "NoDataExists" ;
VAL_ 361 TrcmSrvcRqd_B_Rq 1 "Yes" 0 "No" ;
VAL_ 361 TrnGear_I_MeasMax 255 "Fault" ;
VAL_ 361 TrnCapHlth_Actl 3 "Capacitor_OK" 2 "Degraded_Capacitor" 1 "Capacitor_State_Unknown" 0 "Capacitor_Fault" ;
VAL_ 361 TrnPwmFalt_B_Actl 1 "Yes" 0 "No" ;
VAL_ 361 TrnActFalt_B_Actl 1 "Yes" 0 "No" ;
VAL_ 1009 ChrgCordUnlock_B_Rq 1 "Request" 0 "NoRequest" ;
VAL_ 1009 AutoHoldSwtch_D_Stat3 3 "Faulty" 2 "NotUsed" 1 "Pressed" 0 "Not_Pressed" ;
VAL_ 1009 TrlrAidCancl_B_Rq 1 "Cancel" 0 "Null" ;
VAL_ 1009 CenterStackRing_D_Actl 3 "LimitedOn" 2 "On" 1 "Off" 0 "Null" ;
VAL_ 1009 ValetMode_D_Stat 3 "NotUsed" 2 "On" 1 "Off" 0 "Null" ;
VAL_ 1009 TrlrAidSetup_D_Stat 7 "Faulty" 6 "NotUsed_3" 5 "NotUsed_2" 4 "NotUsed_1" 3 "EnterParameters" 2 "EndSetup" 1 "BeginSetup" 0 "Null" ;
VAL_ 1009 TrlrTrgtAcquire_D_Rq 7 "NotUsed_2" 6 "NotUsed_1" 5 "ActivateRVCforTBA" 4 "CancelAcquisition" 3 "RetryAcquisition" 2 "AcquisitionSuccessful" 1 "StartAcquisition" 0 "Inactive" ;
VAL_ 360 GsmSrvcRqd_B_Rq 1 "Yes" 0 "No" ;
VAL_ 360 TrnTrcmPwmSig_D_Actl 15 "Faulty" 14 "NoDataExists" 13 "NotUsed5" 12 "NotUsed4" 11 "NotUsed3" 10 "NotUsed2" 9 "NotUsed1" 8 "Default_To_Park" 7 "Neutral_Tow" 6 "Car_Wash_Mode" 5 "Manual" 4 "Drive" 3 "Neutral" 2 "Reverse" 1 "Park" 0 "No_Gear" ;
VAL_ 360 TrnGearPwmFalt_B_Actl 1 "Yes" 0 "No" ;
VAL_ 360 GearButtnStuck_B_Actl 1 "Yes" 0 "No" ;
VAL_ 331 TrnAout2_W_ActlUnfilt 65535 "Fault" 65534 "NoDataExists" ;
VAL_ 331 CmbbEngTqMn_B_ActlHtrn 1 "Active" 0 "Inactive" ;
VAL_ 331 CmbbDeny_B_ActlHtrn 1 "Yes" 0 "No" ;
VAL_ 140 DcacPwResetBttn_D_Stat 3 "NotUsed" 2 "Stuck" 1 "Pressed" 0 "Not_Pressed" ;
VAL_ 140 CcAslButtnIndxIncPress2 1 "Button_Pressed" 0 "Button_Not_Pressed" ;
VAL_ 140 SteWhlSwtchMde_D_Stat 3 "NotUsed_2" 2 "NotUsed_1" 1 "Dialog" 0 "Domain" ;
VAL_ 140 CcAslButtnIndxDecPress2 1 "Button_Pressed" 0 "Button_Not_Pressed" ;
VAL_ 140 CcAslButtnResIncPress3 1 "Pressed" 0 "Not pressed" ;
VAL_ 140 CcButtnOnPress3 1 "Pressed" 0 "Not pressed" ;
VAL_ 140 CcButtnOnOffPress3 1 "Pressed" 0 "Not pressed" ;
VAL_ 140 CcButtnOnOffCnclPress3 1 "Pressed" 0 "Not pressed" ;
VAL_ 140 CcButtnOffPress3 1 "Pressed" 0 "Not pressed" ;
VAL_ 140 CcAsllButtnResPress3 1 "Pressed" 0 "Not pressed" ;
VAL_ 140 CcAslButtnSetPress3 1 "Pressed" 0 "Not pressed" ;
VAL_ 140 CcAslButtnSetIncPress3 1 "Pressed" 0 "Not pressed" ;
VAL_ 140 CcAslButtnSetDecPress3 1 "Pressed" 0 "Not pressed" ;
VAL_ 140 CcAslButtnResDecPress3 1 "Pressed" 0 "Not pressed" ;
VAL_ 140 CcAslButtnOnPress3 1 "Pressed" 0 "Not pressed" ;
VAL_ 140 CcAslButtnOnOffCncl3 1 "Pressed" 0 "Not pressed" ;
VAL_ 140 CcAslButtnDeny_B_Actl3 1 "Pressed" 0 "Not pressed" ;
VAL_ 140 CcAslButtnCnclPress3 1 "Pressed" 0 "Not pressed" ;
VAL_ 140 AslButtnOnOffPress3 1 "Pressed" 0 "Not pressed" ;
VAL_ 140 AslButtnOnOffCnclPress2 1 "Pressed" 0 "Not pressed" ;
VAL_ 140 CcAslButtnOffCnclPress2 1 "Button_Pressed" 0 "Button_Not_Pressed" ;
VAL_ 140 CcAslButtnCnclResPress2 1 "Button_Pressed" 0 "Button_Not_Pressed" ;
VAL_ 122 VehStrtInhbt_B_RqBatt 1 "Yes" 0 "No" ;
VAL_ 122 BattTracOffFst_D_Actl 3 "Unexpected_Contactor_Open" 2 "Restraints_Impact_Event" 1 "Interlock_Open" 0 "Normal" ;
VAL_ 122 BattTracOff_B_Actl 1 "Yes" 0 "No" ;
VAL_ 122 BattTracMil_D_Rq 3 "Not_Used" 2 "Flash" 1 "On" 0 "Off" ;
VAL_ 122 BattTracCnnct_B_Cmd 1 "Close" 0 "Open" ;
VAL_ 122 BattTrac_U_Actl 1023 "Fault" 1022 "Unknown" ;
VAL_ 122 BattTrac_I_Actl 32767 "Fault" 32766 "Unknown" ;
VAL_ 93 TrnTrcmNtmState_D_Actl 3 "Faulty" 2 "Neutral_Tow_Mode" 1 "Car_Wash_Mode" 0 "None" ;
VAL_ 93 TrnSns2Pos_Pc_Actl 1023 "Fault" ;
VAL_ 93 TrnSns1Pos_Pc_Actl 1023 "Fault" ;
VAL_ 93 TrnSecPrkStat_D_Actl 7 "Faulty" 6 "Fault_Released" 5 "Fault_Latched" 4 "Recouple_in_Progress" 3 "Mechanism_Released" 2 "RTP_in_Progress" 1 "Pending" 0 "Latched" ;
VAL_ 93 TrnNtrlTowCnfm_B_Actl 1 "Yes" 0 "No" ;
VAL_ 93 TrnGearFinalPos_B_Actl 1 "Yes" 0 "No" ;
VAL_ 93 TrnGear_D_Actl 7 "Fault" 6 "NotUsed" 5 "Manual" 4 "Drive" 3 "Neutral" 2 "Reverse" 1 "Park" 0 "Transition_State" ;
VAL_ 90 TrnGsmNtmState_D_Actl 3 "Faulty" 2 "Neutral_Tow_Mode" 1 "Car_Wash_Mode" 0 "None" ;
VAL_ 90 DrQltyDrv_D_StatGsm 7 "Faulty" 6 "NoDataExists" 5 "NotUsed2" 4 "NotUsed1" 3 "ClosedDegraded" 2 "OpenDegraded" 1 "ClosedOkay" 0 "OpenOkay" ;
VAL_ 90 TrnBtsiOvrrd_B_Stat 1 "Override" 0 "Null" ;
VAL_ 90 GsmGearMsgTxt_D_Rq 3 "Message3" 2 "Message2" 1 "Message1" 0 "NoMessage" ;
VAL_ 90 TrnRng_D_RqGsm 15 "Fault" 14 "UnknownPosition" 13 "Undefined_2" 12 "Undefined_1" 11 "_6" 10 "_5" 9 "_4" 8 "_3" 7 "_2" 6 "_1" 5 "Low" 4 "Sport_DriveSport" 3 "Drive" 2 "Neutral" 1 "Reverse" 0 "Park" ;
VAL_ 90 PrkBrkActv_D_RqGsmGear 3 "NotUsed" 2 "RequestParkBrakeEngage" 1 "NoRequest" 0 "Null" ;
VAL_ 90 TrnValidGearRq_D_Stat 3 "Valid_Request" 2 "Valid_Degraded_Request" 1 "Invalid_Request" 0 "No_Request" ;
VAL_ 90 TrnGearButtn_U_Actl 255 "Fault" ;
VAL_ 90 TrnGearButtn_B_ActlR2 1 "Yes" 0 "No" ;
VAL_ 90 TrnGearButtn_B_ActlR1 1 "Yes" 0 "No" ;
VAL_ 90 TrnGearButtn_B_ActlR0 1 "Yes" 0 "No" ;
VAL_ 90 TrnGearButtn_B_ActlP2 1 "Yes" 0 "No" ;
VAL_ 90 TrnGearButtn_B_ActlP1 1 "Yes" 0 "No" ;
VAL_ 90 TrnGearButtn_B_ActlP0 1 "Yes" 0 "No" ;
VAL_ 90 TrnGearButtn_B_ActlN2 1 "Yes" 0 "No" ;
VAL_ 90 TrnGearButtn_B_ActlN1 1 "Yes" 0 "No" ;
VAL_ 90 TrnGearButtn_B_ActlN0 1 "Yes" 0 "No" ;
VAL_ 90 TrnGearButtn_B_ActlM2 1 "Yes" 0 "No" ;
VAL_ 90 TrnGearButtn_B_ActlM1 1 "Yes" 0 "No" ;
VAL_ 90 TrnGearButtn_B_ActlM0 1 "Yes" 0 "No" ;
VAL_ 90 TrnGearButtn_B_ActlD2 1 "Yes" 0 "No" ;
VAL_ 90 TrnGearButtn_B_ActlD1 1 "Yes" 0 "No" ;
VAL_ 90 TrnGearButtn_B_ActlD0 1 "Yes" 0 "No" ;
VAL_ 90 TrnGear_D_RqDrv 31 "Fault" 30 "NotUsed_25" 29 "NotUsed_24" 28 "NotUsed_23" 27 "NotUsed_22" 26 "NotUsed_21" 25 "NotUsed_20" 24 "NotUsed_19" 23 "NotUsed_18" 22 "NotUsed_17" 21 "Return_To_Park" 20 "NotUsed_15" 19 "NotUsed_14" 18 "NotUsed_13" 17 "NotUsed_12" 16 "Manual" 15 "Not_Used11" 14 "Not_Used10" 13 "NotUsed_9" 12 "NotUsed_8" 11 "NotUsed_7" 10 "NotUsed_6" 9 "NotUsed_5" 8 "Drive" 7 "NotUsed_4" 6 "NotUsed_3" 5 "NotUsed_2" 4 "Neutral" 3 "NotUsed_1" 2 "Reverse" 1 "Park" 0 "No_Gear" ;
VAL_ 90 BrkSwtchPos_B_ActlGsm 1 "Yes" 0 "No" ;
VAL_ 1114 TrailCtlSwtch_B_Stat2 1 "Pressed" 0 "Not_Pressed" ;
VAL_ 1114 TrlBrkInitOut_D_Rq 3 "Heavy" 2 "Medium" 1 "Light" 0 "Null" ;
VAL_ 1111 TrlrYawWActl_D_Qf 3 "OK" 2 "Not_Within_Specifications" 1 "No_Data_Exists" 0 "Faulty" ;
VAL_ 1111 TrlrYaw_W_Actl 65535 "Faulty" 65534 "NoDataExists" ;
VAL_ 1111 TrlrHitYaw_AnRate_Actl 4095 "Fault" 4094 "NoDataExists" ;
VAL_ 1111 TrlrHitchYaw_D_Stat 15 "Faulty" 14 "NotUsed_4" 13 "NotUsed_3" 12 "NotUsed_2" 11 "NotUsed_1" 10 "FaultyYrsuConnection" 9 "FaultyYrsu" 8 "HiConfdLrndAngle" 7 "LowConfdLrndAngle" 6 "HiConfdAngleMem" 5 "LowConfdAngleMem" 4 "InitNoTadAngle" 3 "InitInputs" 2 "TadTrlrDataOutOfRange" 1 "TadNotWithinSpecification" 0 "NoConnectionWithYrsu" ;
VAL_ 1111 TrlrHitchYaw_An_Actl 4095 "Faulty" 4094 "NoDataExists" ;
VAL_ 1106 TrlrSnsId_No_Actl -1 "Faulty_FFFFFFFFFFFF" -2 "NoDataExists_FFFFFFFFFFFE" ;
VAL_ 1091 CamraRearOn_D2_Stat2 7 "Faulty" 6 "NotUsed_3" 5 "NotUsed_2" 4 "NotUsed_1" 3 "Decommission" 2 "Activate" 1 "Deactivate" 0 "Null" ;
VAL_ 1091 PoliceAux4Lamp_B_Rq2 1 "On" 0 "Off" ;
VAL_ 1091 PoliceAux3Lamp_B_Rq2 1 "On" 0 "Off" ;
VAL_ 1091 PoliceAux2Lamp_B_Rq2 1 "On" 0 "Off" ;
VAL_ 1091 PoliceAux1Lamp_B_Rq2 1 "On" 0 "Off" ;
VAL_ 1091 TowBarMsgTxt_D_Rq 7 "NotUsed3" 6 "NotUsed2" 5 "NotUsed1" 4 "TowBar_Ext_No_Trlr" 3 "Error_Dealer_Fix" 2 "Start_Engine_Swivel" 1 "Check_Tow_Bar" 0 "Null" ;
VAL_ 1091 ParkLampTrlrOut_B_Stat 1 "Out" 0 "Null" ;
VAL_ 1091 TrlrLampCtl_D_Stat 3 "NotUsed" 2 "TrlrLampCnnctDrvFailure" 1 "TrlrLampNotCnnctDrvFailure" 0 "Null" ;
VAL_ 1091 TrlrBattChrg_D_Stat 3 "Reverse" 2 "Normal" 1 "Low" 0 "Null" ;
VAL_ 1091 StopLampTrlrOut_B_Stat 1 "Out" 0 "Null" ;
VAL_ 1091 TurnLampTrlrRr_B_Stat 1 "Out" 0 "Null" ;
VAL_ 1091 TurnLampTrlrRl_B_Stat 1 "Out" 0 "Null" ;
VAL_ 1091 TrlrLampCnnct_B_Actl 1 "Yes" 0 "No" ;
VAL_ 1091 WakeAlarm2_B_Typ 1 "CanAndEcuDriveCircuit" 0 "CanOnly" ;
VAL_ 1091 TrlrAlarmSpprt_D_Stat 3 "SupportedByBrakesAndLights" 2 "SupportedByLights" 1 "SupportedByBrakes" 0 "NotSupported" ;
VAL_ 138 SteWhlRelCalib_An_Sns 32767 "Fault" 32766 "NoDataExists" ;
VAL_ 131 TurnLghtSwtch_D_Arb 15 "Faulty" 14 "NotUsed_4" 13 "NotUsed_3" 12 "NotUsed_2" 11 "NotUsed_1" 10 "RightTurnCancelled" 9 "LeftTurnCancelled" 8 "RightTurn" 7 "LeftTurn" 6 "RightLcCancelled" 5 "LeftLcCancelled" 4 "RightLaneChange" 3 "LeftLaneChange" 2 "RightPreLc" 1 "LeftPreLc" 0 "Idle" ;
VAL_ 131 HeadLghtHiCtrl_D_RqAhb 7 "NotUsed2" 6 "NotUsed1" 5 "Auto_HiBeam" 4 "Auto_LoBeam" 3 "Flash" 2 "Man_HiBeam" 1 "Man_LoBeam" 0 "Null" ;
VAL_ 131 AhbStat_B_Dsply 1 "On" 0 "Off" ;
VAL_ 131 WiprFrontSwtch_D_Stat 15 "NotUsed6" 14 "NotUsed5" 13 "NotUsed4" 12 "NotUsed3" 11 "NotUsed2" 10 "NotUsed1" 9 "PositionNotDetermined" 8 "High" 7 "Low" 6 "Position6" 5 "Position5" 4 "Position4" 3 "Position3" 2 "Position2" 1 "Position1" 0 "Off" ;
VAL_ 131 HeadLghtHiOn_B_StatAhb 1 "On" 0 "Off" ;
VAL_ 131 HeadLghtHiFlash_D_Actl 3 "NotUsed" 2 "High" 1 "Flash_to_Pass" 0 "Null" ;
VAL_ 131 TjaButtnOnOffPress 1 "Pressed" 0 "Not_Pressed" ;
VAL_ 131 AccButtnGapTogglePress 1 "Pressed" 0 "Not_Pressed" ;
VAL_ 131 WiprFront_D_Stat 15 "NO_DATA_EXISTS" 14 "STALLED" 13 "RESERVED" 12 "AUTO_ADJUST" 11 "COURTESYWIPE" 10 "AUTO_HIGH" 9 "AUTO_LOW" 8 "WASH" 7 "MIST_FLICK" 6 "MAN_HIGH" 5 "MAN_LOW" 4 "MAN_INT_ON" 3 "MAN_INT_OFF" 2 "OFF_MOVING" 1 "AUTO_OFF" 0 "OFF" ;
VAL_ 131 TurnLghtSwtch_D_Stat 3 "Unused_Treat_As_Off" 2 "Right" 1 "Left" 0 "Off" ;
VAL_ 131 LghtAmb_D_Sns 7 "No_Data_Exists" 6 "Unused2" 5 "Unused1" 4 "Tunnel_Off" 3 "Tunnel_On" 2 "Twilight" 1 "Light" 0 "Dark" ;
VAL_ 131 AccButtnGapIncPress 1 "Button_Pressed" 0 "Button_Not_Pressed" ;
VAL_ 131 AccButtnGapDecPress 1 "Button_Pressed" 0 "Button_Not_Pressed" ;
VAL_ 131 AslButtnOnOffPress 1 "Button_Pressed" 0 "Button_Not_Pressed" ;
VAL_ 131 AslButtnOnOffCnclPress 1 "Button_Pressed" 0 "Button_Not_Pressed" ;
VAL_ 131 CcButtnOnPress 1 "Button_Pressed" 0 "Button_Not_Pressed" ;
VAL_ 131 CcButtnOnOffPress 1 "Button_Pressed" 0 "Button_Not_Pressed" ;
VAL_ 131 CcButtnOnOffCnclPress 1 "Button_Pressed" 0 "Button_Not_Pressed" ;
VAL_ 131 CcButtnOffPress 1 "Button_Pressed" 0 "Button_Not_Pressed" ;
VAL_ 131 CcAsllButtnResPress 1 "Button_Pressed" 0 "Button_Not_Pressed" ;
VAL_ 131 CcAslButtnSetPress 1 "Button_Pressed" 0 "Button_Not_Pressed" ;
VAL_ 131 CcAslButtnSetIncPress 1 "Button_Pressed" 0 "Button_Not_Pressed" ;
VAL_ 131 CcAslButtnSetDecPress 1 "Button_Pressed" 0 "Button_Not_Pressed" ;
VAL_ 131 CcAslButtnResIncPress 1 "Button_Pressed" 0 "Button_Not_Pressed" ;
VAL_ 131 CcAslButtnResDecPress 1 "Button_Pressed" 0 "Button_Not_Pressed" ;
VAL_ 131 CcAslButtnOnPress 1 "Button_Pressed" 0 "Button_Not_Pressed" ;
VAL_ 131 CcAslButtnOnOffCncl 1 "Button_Pressed" 0 "Button_Not_Pressed" ;
VAL_ 131 CcAslButtnOffCnclPress 1 "Button_Pressed" 0 "Button_Not_Pressed" ;
VAL_ 131 CcAslButtnIndxIncPress 1 "Button_Pressed" 0 "Button_Not_Pressed" ;
VAL_ 131 CcAslButtnIndxDecPress 1 "Button_Pressed" 0 "Button_Not_Pressed" ;
VAL_ 131 CcAslButtnDeny_B_Actl 1 "Yes" 0 "No" ;
VAL_ 131 CcAslButtnCnclResPress 1 "Button_Pressed" 0 "Button_Not_Pressed" ;
VAL_ 131 CcAslButtnCnclPress 1 "Button_Pressed" 0 "Button_Not_Pressed" ;
VAL_ 131 LaSwtchPos_D_Stat 3 "Fault" 2 "Unused" 1 "Pressed" 0 "Open" ;
VAL_ 131 HeadLghtHiFlash_D_Stat 3 "NotUsed" 2 "High" 1 "Flash_to_Pass" 0 "Null" ;
VAL_ 787 PwTgateStepMsgTxt_B_Rq 1 "DisplayMessage" 0 "NoMessage" ;
VAL_ 787 PwTgateInhbtMsgTxt_B_Rq 1 "DisplayMessage" 0 "NoMessage" ;
VAL_ 787 DrTgateChime2_D_Rq 7 "NotUsed3" 6 "NotUsed2" 5 "NotUsed1" 4 "Long_Repeated" 3 "Fast" 2 "Short" 1 "Long" 0 "Off" ;
VAL_ 787 DrTGate_D_Rq 3 "NotUsed" 2 "Closing" 1 "Opening" 0 "Not_Moving" ;
VAL_ 787 PwLftgtIntSw_B_Stat 1 "Pressed" 0 "Null" ;
VAL_ 787 Power_Liftgate_Mode_Stt 2 "Unused" 3 "Not_Supported" 1 "Enabled" 0 "Disabled" ;
VAL_ 787 PwTgateMsgTxt_B_Rq 1 "DisplayMessage" 0 "NoMessage" ;
VAL_ 787 PwTgateLamp_B_Rq 1 "On" 0 "Off" ;
VAL_ 570 SuspClkSync_No_Rq 255 "Faulty" 254 "NoDataExists" ;
VAL_ 570 SuspRearRight_L_Actl 511 "Faulty" ;
VAL_ 570 SuspFrntRight_L_Actl 511 "Faulty" ;
VAL_ 570 SuspRear_L_Prev 511 "Fault" ;
VAL_ 570 SuspRear_L_Actl 511 "Fault" ;
VAL_ 570 SuspFrnt_L_Prev 511 "Fault" ;
VAL_ 570 SuspFrnt_L_Actl 511 "Fault" ;
VAL_ 953 PaakMyKeySearch_D_Stat 7 "PhoneErased" 6 "LockButtonTimeOut" 5 "PressLockButton" 4 "ConfirmHmi" 3 "MyKeyPaakFound" 2 "StandardPaakFound" 1 "NoValidPaakFound" 0 "Null" ;
VAL_ 953 BattULoChrgHyb_D_Stat 7 "NotUsed_4" 6 "NotUsed_3" 5 "NotUsed_2" 4 "NotUsed_1" 3 "VehicleServiceRequired" 2 "EvRangeLossDueToLoadActive" 1 "BatteryServiceRequired" 0 "Null" ;
VAL_ 953 BattULoChrgHyb_B_Rq 1 "True" 0 "False" ;
VAL_ 953 ChrgCordLck_B_Stat 1 "Unlock" 0 "Null" ;
VAL_ 953 WakeAlarm3_D_Stat 3 "PublisherReset" 2 "Wake" 1 "AlarmRunning" 0 "AlarmOff" ;
VAL_ 953 WakeAlarm2_D_Stat 3 "PublisherReset" 2 "Wake" 1 "AlarmRunning" 0 "AlarmOff" ;
VAL_ 953 WakeAlarm1_D_Stat 3 "PublisherReset" 2 "Wake" 1 "AlarmRunning" 0 "AlarmOff" ;
VAL_ 953 WakeAlarm0_D_Stat 3 "PublisherReset" 2 "Wake" 1 "AlarmRunning" 0 "AlarmOff" ;
VAL_ 953 BattRgenLoChrg_D_Rq 3 "DoNotCare" 2 "Retain" 1 "Closed" 0 "Open" ;
VAL_ 953 BattRgenLoDChrg_D_Rq 3 "DoNotCare" 2 "Retain" 1 "Closed" 0 "Open" ;
VAL_ 1101 AwdLckLamp_D_Rq 3 "Triggered" 2 "Flash" 1 "On" 0 "Off" ;
VAL_ 1101 Ptu_Te_Actl 255 "Faulty" ;
VAL_ 1101 PtLatchActv_B_RqAwd 1 "Yes" 0 "No" ;
VAL_ 1101 PtuFanOn_B_Rq 1 "On" 0 "Off" ;
VAL_ 1101 RearDiffLckLamp_D_Rq3 3 "Triggered" 2 "Flash" 1 "On" 0 "Off" ;
VAL_ 1099 RearDiff_D_Stat 15 "NotUsed_7" 14 "NotUsed_6" 13 "NotUsed_5" 12 "NotUsed_4" 11 "NotUsed_3" 10 "NotUsed_2" 9 "NotUsed_1" 8 "TorqueReqNotHonored" 7 "MissingSignal" 6 "ModuleFault" 5 "HydroTempSensorFault" 4 "ClutchPressSensorFault" 3 "AccumPressSensorFault" 2 "ControlValveFault" 1 "MotorFault" 0 "Normal" ;
VAL_ 1099 RearDiffThrml_D_Stat 3 "NotUsed_1" 2 "AboveThermalLimit" 1 "ThermalLimit" 0 "Normal" ;
VAL_ 1099 RearDiffSrvcRqd_B_Rq 1 "On" 0 "Off" ;
VAL_ 1078 UStabLvl2OvrTe_B_Stat 1 "Yes" 0 "No" ;
VAL_ 1078 UStabLvl2Ovrld_B_Stat 1 "Yes" 0 "No" ;
VAL_ 1078 UStabLvl2_D_Stat 3 "Fault" 2 "Active" 1 "Ready" 0 "Not_Ready" ;
VAL_ 1052 AwdDcnntSlipTrgt_B_Rq 1 "Request" 0 "NoRequest" ;
VAL_ 1052 AwdCnnct_D_Stat 3 "Connecting" 2 "Disconnecting" 1 "Connected" 0 "Disconnected" ;
VAL_ 1052 AwdRight_Tq_Rq 4095 "Fault" 4094 "Unknown" ;
VAL_ 1052 AwdRight_Tq_Est 4095 "Fault" 4094 "Unknown" ;
VAL_ 1052 AwdLeft_Tq_Rq 4095 "Fault" 4094 "Unknown" ;
VAL_ 1052 AwdLeft_Tq_Est 4095 "Fault" 4094 "Unknown" ;
VAL_ 1052 AwdLck_Tq_Actl 4095 "Fault" 4094 "Unknown" ;
VAL_ 1052 AwdLckTqNeg_B_Actl 1 "Active" 0 "Inactive" ;
VAL_ 1093 TrlBrkInitOut_D_Stat 3 "Heavy" 2 "Medium" 1 "Light" 0 "Null" ;
VAL_ 1093 TrlrBrkMde_D_Actl 1 "Electric_Over_Hydraulic" 0 "Electric" ;
VAL_ 1093 TrlrBrkDsply_B_Rq 1 "Yes" 0 "No" ;
VAL_ 1093 TrlrBrkDcnnt_B_Actl 1 "Yes" 0 "No" ;
VAL_ 1093 TrlrBrkActCnnct_B_Actl 1 "Yes" 0 "No" ;
VAL_ 1093 StopLamp_B_RqTrlrBrk 1 "Yes" 0 "No" ;
VAL_ 1093 TrlrBrkCtl_B_Falt 1 "Yes" 0 "No" ;
VAL_ 1093 TrlrBrkActCirct_B_Falt 1 "Yes" 0 "No" ;
VAL_ 837 VdmSustnActv_B_Rq 1 "Active" 0 "Inactive" ;
VAL_ 837 VehCurb_M_Actl 1023 "Faulty" 1022 "NoDataExists" ;
VAL_ 837 VehGvwr_M_Actl 1023 "Faulty" 1022 "NoDataExists" ;
VAL_ 837 Ccd_B_Falt 1 "Yes" 0 "No" ;
VAL_ 837 SuspVLim_B_Rq 1 "True" 0 "False" ;
VAL_ 837 SelDrvMdeSusp_D_Stat 3 "Faulty" 2 "TemporarilyNotAvailable" 1 "Available" 0 "NotAvailable" ;
VAL_ 837 AdptDrvMdePt_D_Rq 7 "Faulty" 6 "NotUsed3" 5 "NotUsed2" 4 "NotUsed1" 3 "Powertrain2Sport" 2 "Powertrain2Normal" 1 "Powertrain2Comfort" 0 "AdaptiveNotActive" ;
VAL_ 837 AdptDrvMdeChassis_D_Rq 7 "Faulty" 6 "NotUsed3" 5 "NotUsed2" 4 "NotUsed1" 3 "Chassis2Sport" 2 "Chassis2Normal" 1 "Chassis2Comfort" 0 "AdaptiveNotActive" ;
VAL_ 837 AirSprngRateRr_D_Rq 3 "NoRequest" 2 "Firm" 1 "Medium" 0 "Soft" ;
VAL_ 837 AirSprngRateRl_D_Rq 3 "NoRequest" 2 "Firm" 1 "Medium" 0 "Soft" ;
VAL_ 837 SuspType_B_Stat 1 "Magnetic" 0 "NonMagnetic" ;
VAL_ 837 AirSprngRateFr_D_Rq 3 "NoRequest" 2 "Firm" 1 "Medium" 0 "Soft" ;
VAL_ 837 AirSprngRateFl_D_Rq 3 "NoRequest" 2 "Firm" 1 "Medium" 0 "Soft" ;
VAL_ 837 AirSusp_D_Stat 3 "NotUsed" 2 "On" 1 "Off" 0 "Null" ;
VAL_ 837 AirSuspMsgTxt_D_Rq 3 "NotUsed" 2 "Faulty" 1 "Override" 0 "NoMessage" ;
VAL_ 837 SuspDrvMde_D_Stat 7 "Faulty" 6 "NotUsed2" 5 "NotUsed1" 4 "Drag" 3 "Track" 2 "Snow_Wet" 1 "Sport" 0 "Normal" ;
VAL_ 837 CcdMsgTxt_D_RqDsply 15 "Unused8" 14 "Unused7" 13 "Unused6" 12 "Unused5" 11 "Unused4" 10 "Unused3" 9 "Unused2" 8 "StationaryMode" 7 "Mode_Change_Unavailable" 6 "CCD_Temporarily_Off" 5 "CCD_Service_Required" 4 "Faulty" 3 "Sport" 2 "Normal" 1 "Comfort" 0 "No_Mode_Selected" ;
VAL_ 792 DsplyChkActv_B_Stat 1 "Active" 0 "Inactive" ;
VAL_ 792 ElTrip_L_Dsply 65535 "Fault" 65534 "No_Data_Exists" ;
VAL_ 792 ElLongTerm_L_Dsply 16777215 "Fault" 16777214 "No_Data_Exists" ;
VAL_ 968 IpcLvl_B_Type 1 "High" 0 "Low" ;
VAL_ 968 RvltnMatchAllw_D_Rq 3 "RevolutionMatchDisabled" 2 "RevolutionMatchEnabled" 1 "ChangeWithDriveMode" 0 "NoSelection" ;
VAL_ 968 BrkDrvMde_D_Rq 7 "Faulty" 6 "RockCrawl" 5 "Baja" 4 "DragOrMudAndSand" 3 "Track" 2 "Snow_Wet" 1 "Sport" 0 "Normal" ;
VAL_ 968 LnchCtl_D_Rq 3 "NotUsed2" 2 "NotUsed1" 1 "LC_On" 0 "LC_Off" ;
VAL_ 968 CurrentColor_CmdGage 15 "NotUsed7" 14 "NotUsed6" 13 "NotUsed5" 12 "NotUsed4" 11 "NotUsed3" 10 "NotUsed2" 9 "NotUsed1" 8 "Null" 7 "Color7" 6 "Color6" 5 "Color5" 4 "Color4" 3 "Color3" 2 "Color2" 1 "Color1" 0 "Off" ;
VAL_ 968 BlendedColor_CmdGage 3 "NotUsed" 2 "Null" 1 "On" 0 "Off" ;
VAL_ 968 BlendColorRed_CmdGage 15 "NotUsed10" 14 "NotUsed9" 13 "NotUsed8" 12 "NotUsed7" 11 "NotUsed6" 10 "NotUsed5" 9 "NotUsed4" 8 "NotUsed3" 7 "NotUsed2" 6 "NotUsed1" 5 "_5" 4 "_4" 3 "_3" 2 "_2" 1 "_1" 0 "Null" ;
VAL_ 968 BlendColorGrn_CmdGage 15 "NotUsed10" 14 "NotUsed9" 13 "NotUsed8" 12 "NotUsed7" 11 "NotUsed6" 10 "NotUsed5" 9 "NotUsed4" 8 "NotUsed3" 7 "NotUsed2" 6 "NotUsed1" 5 "_5" 4 "_4" 3 "_3" 2 "_2" 1 "_1" 0 "Null" ;
VAL_ 968 BlendColorBlue_CmdGage 15 "NotUsed10" 14 "NotUsed9" 13 "NotUsed8" 12 "NotUsed7" 11 "NotUsed6" 10 "NotUsed5" 9 "NotUsed4" 8 "NotUsed3" 7 "NotUsed2" 6 "NotUsed1" 5 "_5" 4 "_4" 3 "_3" 2 "_2" 1 "_1" 0 "Null" ;
VAL_ 968 Dimming_Level_Cmd 3 "Low" 2 "Not_Used" 1 "High" 0 "Null" ;
VAL_ 968 Current_Color_Cmd 15 "NotUsed7" 14 "NotUsed6" 13 "NotUsed5" 12 "NotUsed4" 11 "NotUsed3" 10 "NotUsed2" 9 "NotUsed1" 8 "Null" 7 "Color7" 6 "Color6" 5 "Color5" 4 "Color4" 3 "Color3" 2 "Color2" 1 "Color1" 0 "Off" ;
VAL_ 968 BlendedColorRed_Cmd 15 "NotUsed10" 14 "NotUsed9" 13 "NotUsed8" 12 "NotUsed7" 11 "NotUsed6" 10 "NotUsed5" 9 "NotUsed4" 8 "NotUsed3" 7 "NotUsed2" 6 "NotUsed1" 5 "_5" 4 "_4" 3 "_3" 2 "_2" 1 "_1" 0 "Null" ;
VAL_ 968 BlendedColorGreen_Cmd 15 "NotUsed10" 14 "NotUsed9" 13 "NotUsed8" 12 "NotUsed7" 11 "NotUsed6" 10 "NotUsed5" 9 "NotUsed4" 8 "NotUsed3" 7 "NotUsed2" 6 "NotUsed1" 5 "_5" 4 "_4" 3 "_3" 2 "_2" 1 "_1" 0 "Null" ;
VAL_ 968 BlendedColorBlue_Cmd 15 "NotUsed10" 14 "NotUsed9" 13 "NotUsed8" 12 "NotUsed7" 11 "NotUsed6" 10 "NotUsed5" 9 "NotUsed4" 8 "NotUsed3" 7 "NotUsed2" 6 "NotUsed1" 5 "_5" 4 "_4" 3 "_3" 2 "_2" 1 "_1" 0 "Null" ;
VAL_ 968 BlendedColor_Cmd 3 "NotUsed" 2 "Null" 1 "On" 0 "Off" ;
VAL_ 968 SuspDrvMde_D_Rq 7 "Faulty" 6 "NotUsed2" 5 "NotUsed1" 4 "Drag" 3 "Track" 2 "Snow_Wet" 1 "Sport" 0 "Normal" ;
VAL_ 968 SlMde_D_Rq 3 "IsaNotConfigured" 2 "Manual_Mode" 1 "Auto_Mode" 0 "Null" ;
VAL_ 968 IsaOffst_D_Rq 15 "Faulty" 14 "Null" 13 "Thirteen" 12 "Twelve" 11 "Eleven" 10 "Ten" 9 "Nine" 8 "Eight" 7 "Seven" 6 "Six" 5 "Five" 4 "Four" 3 "Three" 2 "Two" 1 "One" 0 "Zero" ;
VAL_ 819 WndwUpPsngrRear_D_Falt 3 "NotUsed" 2 "Fault" 1 "NoFault" 0 "Null" ;
VAL_ 819 WndwUpPsngrFront_D_Falt 3 "NotUsed" 2 "Fault" 1 "NoFault" 0 "Null" ;
VAL_ 819 Memory_3_SwPsngr_Stat 1 "Pressed" 0 "Null" ;
VAL_ 819 Memory_2_SwPsngr_Stat 1 "Pressed" 0 "Null" ;
VAL_ 819 Memory_1_SwPsngr_Stat 1 "Pressed" 0 "Null" ;
VAL_ 819 BLISLEDStatPassSide 3 "Fault" 2 "Unused" 1 "On" 0 "Off" ;
VAL_ 819 WndwPsngrSide_D_Stat 3 "BothWindow_Operating" 2 "RearWindow_Operating" 1 "FrontWindow_Operating" 0 "NoWindows_Operating" ;
VAL_ 819 Pasngr_Lock_Sw_Stat 3 "Invalid" 2 "Unlock" 1 "Lock" 0 "Null" ;
VAL_ 819 ChildLckFdbckRp_B_Stat 1 "Locked" 0 "Unlock" ;
VAL_ 819 DrPrsntPsngr_D_Stat 3 "Faulty" 2 "Present" 1 "NotPresent" 0 "NotDetermined" ;
VAL_ 819 DrPsngrMsgTxt_B_Rq 1 "Yes" 0 "No" ;
VAL_ 819 DrPrsntRearPsngr_D_Stat 3 "Faulty" 2 "Present" 1 "NotPresent" 0 "NotDetermined" ;
VAL_ 818 WndwUpDrvRear_D_Falt 3 "NotUsed" 2 "Fault" 1 "NoFault" 0 "Null" ;
VAL_ 818 WndwUpDrvFront_D_Falt 3 "NotUsed" 2 "Fault" 1 "NoFault" 0 "Null" ;
VAL_ 818 BLISLEDStatDriverSide 3 "Fault" 2 "Unused" 1 "On" 0 "Off" ;
VAL_ 818 WndwDrvSide_D_Stat 3 "BothWindow_Operating" 2 "RearWindow_Operating" 1 "FrontWindow_Operating" 0 "NoWindows_Operating" ;
VAL_ 818 KeyCylSwDrvDr_D_Stat 3 "NotUsed" 2 "Unlock" 1 "Lock" 0 "Null" ;
VAL_ 818 Driver_Lock_Sw_Stat 3 "Invalid" 2 "Unlock" 1 "Lock" 0 "Null" ;
VAL_ 818 ChildLckPw_D_Rq 1 "Active" 0 "Null" ;
VAL_ 818 ChildLckFdbckRd_B_Stat 1 "Locked" 0 "Unlock" ;
VAL_ 818 RvrseMirrorChime_B_Rq 1 "Yes" 0 "No" ;
VAL_ 818 DrvSpotLight_B_Stat 1 "Active" 0 "Inactive" ;
VAL_ 818 DrPrsntDrv_D_Stat 3 "Faulty" 2 "Present" 1 "NotPresent" 0 "NotDetermined" ;
VAL_ 818 DrPrsntRearDrv_D_Stat 3 "Faulty" 2 "Present" 1 "NotPresent" 0 "NotDetermined" ;
VAL_ 818 DrDrvMsgTxt_B_Rq 1 "Yes" 0 "No" ;
VAL_ 806 ClimtCoolRear_B_Rq 1 "On" 0 "Off" ;
VAL_ 806 ClimtHeatRear_D_Rq 7 "NotUsed4" 6 "NotUsed3" 5 "HtrCoreClntFlwOnly" 4 "PtcHtrTestMde" 3 "Defrost_Defog" 2 "FastTempPullDownHeatingReq" 1 "OpportunisticHeatingReq" 0 "NoHeatingRequest" ;
VAL_ 806 SnowPlowMde_B_Enbl 1 "Enable" 0 "Disable" ;
VAL_ 806 ClimtDeltaLoad_Pw_Actl 63 "Faulty" 62 "NoDataExists" ;
VAL_ 806 StopStrtDrvMde_B_RqBtn 1 "Pressed" 0 "Not_Pressed" ;
VAL_ 806 HtrCorePump_B_Rq 1 "On" 0 "Off" ;
VAL_ 806 ClimtHeat_D_Rq 7 "NotUsed4" 6 "NotUsed3" 5 "HtrCoreClntFlwOnly" 4 "PtcHtrTestMde" 3 "Defrost_Defog" 2 "FastTempPullDownHeatingReq" 1 "OpportunisticHeatingReq" 0 "NoHeatingRequest" ;
VAL_ 806 ClimtCool_D_Rq 7 "NotUsed4" 6 "NotUsed3" 5 "NotUsed2" 4 "ElACTestMde" 3 "Defrost_Defog" 2 "FastTempPullDownCoolReq" 1 "OpportunisticCoolingReq" 0 "NoCoolingRequest" ;
VAL_ 806 HvacEvap_Te_Actl 1023 "Fault" ;
VAL_ 806 HvacAirCond_B_Rq 1 "Yes" 0 "No" ;
VAL_ 806 ClimtPw_B_Rq 1 "Yes" 0 "No" ;
VAL_ 806 WndwFrontHeat_B_Stat 1 "On" 0 "Off" ;
VAL_ 765 BalrSwtch_D_Stat 3 "NotUsed" 2 "Pressed" 1 "NotPressed" 0 "Null" ;
VAL_ 765 BalrMde_D_Rq 3 "High" 2 "Medium" 1 "Low" 0 "Null" ;
VAL_ 765 RstrnOnPsngr_D_RqMnu 15 "Faulty" 14 "NotUsed_11" 13 "NotUsed_10" 12 "ConfiguredOff" 11 "NotUsed_9" 10 "On" 9 "NotUsed_8" 8 "NotUsed_7" 7 "NotUsed_6" 6 "NotUsed_5" 5 "Off" 4 "NotUsed_4" 3 "NotUsed_3" 2 "NotUsed_2" 1 "NotUsed_1" 0 "NoAction" ;
VAL_ 765 WaitToStartLamp_D_Falt 3 "NotUsed" 2 "Wait_to_start_lamp_failed" 1 "Diagnosis_not_ready" 0 "Wait_to_start_lamp_OK" ;
VAL_ 765 EsaOn_B_Rq 1 "On" 0 "Off" ;
VAL_ 765 BttOn_B_Rq 1 "On" 0 "Off" ;
VAL_ 765 Btt_L_Actl 127 "Faulty" 126 "NoDataExists" ;
VAL_ 765 RearDiffLck_D_RqArb 3 "Faulty" 2 "NotUsed" 1 "On" 0 "Off" ;
VAL_ 765 AwdMde_D_RqArb 7 "Faulty" 6 "NotUsed2" 5 "NoRequest" 4 "Neutral" 3 "FourByFourLow" 2 "FourByFourHigh" 1 "FourByFourAuto" 0 "FourByTwo" ;
VAL_ 765 SelDrvMdeTxtReset_B_Rq 1 "Yes" 0 "No" ;
VAL_ 765 AutoTowAllw_D_RqMnu 3 "TowHaulCommandedOn" 2 "AutoTowHaulEnabled" 1 "AutoTowHaulDisabled" 0 "NoSelection" ;
VAL_ 765 DrvInputRequired_B_Rq 1 "Yes" 0 "No" ;
VAL_ 765 SelDrvMdeDsply_B_Avail 1 "Available" 0 "NotAvailable" ;
VAL_ 765 EngExhMdeQuiet_D_Rq 3 "Faulty" 2 "QuietExhaust" 1 "LoudExhaust" 0 "Null" ;
VAL_ 765 AirSusp_D_RqDrv 3 "NotUsed" 2 "On" 1 "Off" 0 "NoModeSelected" ;
VAL_ 765 Mc_VehUntTrpCoUsrSel_St 0 "TripComputer_metric" 1 "TripComputer_imperial" ;
VAL_ 765 Mc_VehUnitTempUsrSel_St 0 "Temperature_deg_c" 1 "Temperature_deg_f" ;
VAL_ 765 Mc_VehDayNightUsrSel_St 2 "Night" 1 "Day" 0 "Invalid" ;
VAL_ 765 Mc_VehTimeFrmtUsrSel_St 2 "24h_mode" 1 "12h_mode" 0 "Invalid" ;
VAL_ 765 Mc_VehThemeUsrSel_St 2 "Theme_2" 1 "Theme_1" 0 "Invalid" ;
VAL_ 765 Mc_VehLangUsrSel_St 33 "Ukrainian" 32 "Indian_English" 31 "Thai" 30 "Slovak" 29 "Arabic" 28 "Taiwanese" 27 "Mandarin_Chinese" 26 "Korean" 25 "AU_English" 24 "Japanese" 23 "Braz_Portuguese" 22 "EU_Portuguese" 21 "Finish" 20 "Norwegian" 19 "Danish" 18 "Swedish" 17 "Hungarian" 16 "Greek" 15 "Czech" 14 "Polish" 13 "Flemish" 12 "Dutch" 11 "Russian" 10 "Turkish" 9 "Mex_Spanish" 8 "EU_Spanish" 7 "Cana_French" 6 "EU_French" 5 "Italian" 4 "German" 3 "NA_English" 2 "UK_English" 1 "Unknown" 0 "Invalid" ;
VAL_ 765 AwdRnge_D_ActlIpc 7 "Unknown" 6 "High_Range_2wd" 5 "High_Range_Auto" 4 "High_Range_Locked" 3 "Neutral" 2 "Low_Range_2wd" 1 "Low_Range_Auto" 0 "Low_Range_Locked" ;
VAL_ 765 AwdDrvMde_D_Rq 7 "Faulty" 6 "NotAvailable" 5 "RockCrawl" 4 "Baja" 3 "MudAndSand" 2 "Weather" 1 "Sport" 0 "Normal" ;
VAL_ 765 EngExhMdeQuiet_D2_Rq 7 "NotUsed_3" 6 "NotUsed_2" 5 "NotUsed_1" 4 "Track" 3 "Sport" 2 "Normal" 1 "Stealth" 0 "Null" ;
VAL_ 765 BrkLineLck_D_Rq 3 "Off" 2 "Engage" 1 "Initiate" 0 "NoRequest" ;
VAL_ 765 EdmSailMde_B_RqDrv 1 "On" 0 "Off" ;
VAL_ 765 Running_Board_Cmd 3 "Unused" 2 "Manually_Deployed" 1 "All_Enabled" 0 "All_Disabled" ;
VAL_ 518 RearDiffLck_Tq_Actl2 16383 "Faulty" 16382 "NoDataExists" ;
VAL_ 518 LsdCluPlate_Te_Est 511 "Faulty" ;
VAL_ 934 CtaAlrtLeft2_D_Stat 7 "NotUsed3" 6 "NotUsed2" 5 "NotUsed1" 4 "AlertZone4" 3 "AlertZone3" 2 "AlertZone2" 1 "AlertZone1" 0 "Off" ;
VAL_ 934 CtaBrkLeftMsgTxt_B_Rq 1 "Enable" 0 "Disable" ;
VAL_ 934 CtaLeftBrkDecel_B_Rq 1 "Enable" 0 "Disable" ;
VAL_ 934 CtaLeftBrkEnbl_B_Rq 1 "Enable" 0 "Disable" ;
VAL_ 934 BttLeft_D_Stat 7 "BTT5GFault" 6 "Disabled" 5 "Off" 4 "OffTemp" 3 "NotConnected" 2 "Pending" 1 "Connected" 0 "NotDetermined" ;
VAL_ 934 BttLeft_D_RqDrv 3 "NotUsed" 2 "Request" 1 "NoRequest" 0 "Null" ;
VAL_ 934 CtaSnsLeft_D_Stat 3 "Invalid" 2 "System_Failure" 1 "Blocked" 0 "Clear" ;
VAL_ 934 SodDetctLeft_D_Stat 4 "Sensor_Blocked" 3 "Sensor_Fault" 2 "Flash_On" 1 "Alert_On" 0 "AlertOff_FlashOff_SensrClr" ;
VAL_ 934 CtaLeft_D_Stat 7 "NotUsed_3" 6 "NotUsed_2" 5 "NotUsed_1" 4 "Invalid" 3 "Disabled" 2 "On" 1 "Trailer_Tow_Off" 0 "Off" ;
VAL_ 934 CtaAlrtLeft_D_Stat 1 "On" 0 "Off" ;
VAL_ 934 SodLeft_D_Stat 7 "NotUsed_3" 6 "NotUsed_2" 5 "NotUsed_1" 4 "Invalid" 3 "Disabled" 2 "On" 1 "Trailer_Tow_Off" 0 "Off" ;
VAL_ 934 SodSnsLeft_D_Stat 3 "Second_Warning_Audio" 2 "System_Failure" 1 "Blocked" 0 "Clear" ;
VAL_ 934 SodAlrtLeft_D_Stat 3 "Bulb_Proveout" 2 "Flash" 1 "On" 0 "Off" ;
VAL_ 825 WndwFrontHeat_B_Rq 1 "On" 0 "Off" ;
VAL_ 825 FdsmTrgRight_B_Actl 1 "Object_in_Right_Lobe" 0 "No_Object" ;
VAL_ 825 FdsmTrgLeft_B_Actl 1 "Object_in_Left_Lobe" 0 "No_Object" ;
VAL_ 825 FdsmTrgCntr_B_Actl 1 "Object_in_Center_Lobe" 0 "No_Object" ;
VAL_ 825 LscmbbSrvcRqd_B_Rq 1 "Yes" 0 "No" ;
VAL_ 825 LscmbbPostEvnt_B_Dsply 1 "Yes" 0 "No" ;
VAL_ 825 LscmbbEngTqMn_B_Rq 1 "Engine_Braking" 0 "No_Engine_Braking" ;
VAL_ 825 LscmbbMsgTxt_D_Rq 1 "Yes" 0 "No" ;
VAL_ 825 LscmbbDeny_B_Actl 1 "Denied" 0 "Allowed" ;
VAL_ 825 LscmbbBrkPrchg_D_Rq 3 "NotUsed" 2 "Level2_PreCharge" 1 "Level1_PreCharge" 0 "No_Precharge" ;
VAL_ 825 LscmbbBrkDecel_B_Enbl 1 "ConductLSCMbBDecelReq" 0 "DoNotConductLSCMbBDecelReq" ;
VAL_ 825 LscmbbBlck_B_Actl 1 "Yes" 0 "No" ;
VAL_ 825 LscmbbBaSens_D_Rq 3 "Level3_EBA" 2 "Level2_EBA" 1 "Level1_EBA" 0 "Normal_EBA" ;
VAL_ 1072 PtDrvMde_D_Rq 15 "Faulty" 14 "NotUsed11" 13 "NotUsed10" 12 "NotUsed9" 11 "NotUsed8" 10 "NotUsed7" 9 "NotUsed6" 8 "Track" 7 "Drag" 6 "Rock" 5 "Baja" 4 "Sand" 3 "TowHaulGradeAssist" 2 "SnowWet" 1 "Sport" 0 "Normal" ;
VAL_ 1072 DrvSlipCtlMde_D_Rq 3 "App_Specific_Off_Mode_3" 2 "App_Specific_Off_Mode_2" 1 "App_Specific_Off_Mode_1" 0 "Default_Mode" ;
VAL_ 1072 EngIdlShutDown_B_RqDrv 1 "Inhibit" 0 "No_Inibit" ;
VAL_ 1072 DrvPerfMde_D_Rq 3 "Sport" 2 "Normal" 1 "NotUsed" 0 "NoModeSelected" ;
VAL_ 1072 HsaMde_D_Rq 3 "Undefined" 2 "Manual" 1 "Automatic" 0 "Off" ;
VAL_ 1072 StopStrtDrvMde_D_RqMnu 3 "NotUsed2" 2 "NotUsed1" 1 "StopStart_Deselected" 0 "StopStart_Selected" ;
VAL_ 1072 NtrlTowMdeEnbl_B_RqDrv 1 "Yes" 0 "No" ;
VAL_ 1072 LscmbbStat_B_Actl 1 "On" 0 "Off" ;
VAL_ 1072 BulbChkActv_B_Stat 1 "Active" 0 "Inactive" ;
VAL_ 1072 ParkDetect_Stat 1 "Park" 0 "Not_Park" ;
VAL_ 1072 ReducedGuard_D_Rq 3 "NotUsed" 2 "On" 1 "Off" 0 "Null" ;
VAL_ 1072 FrostWarn_D_Stat 3 "NotUsed" 2 "On_Amber" 1 "On_Red" 0 "Off" ;
VAL_ 1072 TrlrBrkMde_D_Rq 1 "ElectricOverHydraulic" 0 "Electric" ;
VAL_ 1072 TRLR_SWAY_CONFIG_CMD 1 "On" 0 "Off" ;
VAL_ 1072 TRAILER_BRAKE_CONFIG 1 "Yes" 0 "No" ;
VAL_ 1072 Power_Liftgate_Mode_Cmd 1 "Enable" 0 "Disable" ;
VAL_ 1072 AccEnbl_B_RqDrv 1 "Adaptive_Cruise" 0 "Normal_Cruise" ;
VAL_ 1072 OdometerMasterValue 16777215 "Invalid" ;
VAL_ 1072 EngOilLife_B_RqReset 1 "Yes" 0 "No" ;
VAL_ 1072 MetricActvTe_B_Actl 1 "Active" 0 "Inactive" ;
VAL_ 1072 AccDeny_B_RqIpc 1 "Yes" 0 "No" ;
VAL_ 1072 ePRNDL_MODE 1 "On" 0 "Off" ;
VAL_ 1072 PrkLckCtlEnbl_D_RqIpc 3 "Rq_Towing" 2 "Rq_Enable" 1 "Rq_Disable" 0 "Null" ;
VAL_ 1072 DrvSlipCtlMde_B_Rq2 1 "Pressed" 0 "Not_Pressed" ;
VAL_ 1072 MetricActv_B_Actl 1 "Active" 0 "Inactive" ;
VAL_ 1072 KeyTypeChngMykey_D_Rq 3 "Search_PE_BackupSlot" 2 "Clear_All_MyKeys" 1 "Request_New_MyKey" 0 "None" ;
VAL_ 1072 ManRgen_D_Rq 3 "NotUsed2" 2 "NotUsed1" 1 "CustInitManExhFilterClean" 0 "No_Customer_Request" ;
VAL_ 1072 Fda_B_Stat 1 "On" 0 "Off" ;
VAL_ 1072 HaDsplyCpblty_B_Stat 1 "Available" 0 "NotAvailable" ;
VAL_ 909 IgnPsswrdDsply_B_Rq 1 "Active" 0 "Inactive" ;
VAL_ 909 ElPwPoint_D_Rq 3 "On" 2 "Off2" 1 "Off1" 0 "Null" ;
VAL_ 909 PoliceIdlMde_D_Stat 15 "NotUsed_7" 14 "NotUsed_6" 13 "NotUsed_5" 12 "NotUsed_4" 11 "NotUsed_3" 10 "UtilityIdleActive" 9 "PepsActive" 8 "Decommissioned" 7 "ActiveFault" 6 "ArmFault" 5 "PrearmedFault" 4 "OffFault" 3 "Active" 2 "Arm" 1 "Prearmed" 0 "Off" ;
VAL_ 909 DrLatchMsgTxt_D_Rq 7 "Message7" 6 "Message6" 5 "Message5" 4 "Message4" 3 "Message3" 2 "Message2" 1 "Message1" 0 "NoMessage" ;
VAL_ 909 WiprFront_D_Stat2 15 "NO_DATA_EXISTS" 14 "STALLED" 13 "NotUsed" 12 "AUTO_ADJUST" 11 "COURTESYWIPE" 10 "AUTO_HIGH" 9 "AUTO_LOW" 8 "WASH" 7 "MIST_FLICK" 6 "MAN_HIGH" 5 "MAN_LOW" 4 "MAN_INT_ON" 3 "MAN_INT_OFF" 2 "OFF_MOVING" 1 "AUTO_OFF" 0 "OFF" ;
VAL_ 909 SecurityMsgTxt_D_Rq 3 "Message3" 2 "Message2" 1 "Message1" 0 "NoMessage" ;
VAL_ 909 PrmtrAlrmEvnt_D_Stat 15 "Diag_Tamper" 14 "Trailer" 13 "Shock_Sensor" 12 "Post_Crash" 11 "Panic" 10 "Intrusion" 9 "Inclination" 8 "Ign_Tamper" 7 "LG_Door" 6 "Decklid" 5 "Hood" 4 "PR_Door" 3 "PF_Door" 2 "DR_Door" 1 "DF_Door" 0 "Null" ;
VAL_ 909 TurnLghtSwtch_D_Stat2 3 "NotUsed" 2 "Right" 1 "Left" 0 "Off" ;
VAL_ 909 HeadLghtHiPrmsn_D_Stat 3 "CancelAndSuppress" 2 "Cancel" 1 "Hold" 0 "AllowChange" ;
VAL_ 909 SteWhlLckMsgTxt_D_Rq 3 "Message_3" 2 "Message_2" 1 "Message_1" 0 "No_Message" ;
VAL_ 909 immoMsgTxt_D_Rq 15 "Immo_Msg_15" 14 "Immo_Msg_14" 13 "Immo_Msg_13" 12 "Immo_Msg_12" 11 "Immo_Msg_11" 10 "Immo_Msg_10" 9 "Immo_Msg_9" 8 "Immo_Msg_8" 7 "Immo_Msg_7" 6 "Immo_Msg_6" 5 "Immo_Msg_5" 4 "Immo_Msg_4" 3 "Immo_Msg_3" 2 "Immo_Msg_2" 1 "Immo_Msg_1" 0 "Immo_Msg_0_Null" ;
VAL_ 909 PrsnlDevcChrgEnbl_B_Rq 1 "Active" 0 "Inactive" ;
VAL_ 909 TracKeyMde_D_Stat 3 "NotUsed" 2 "NotActive" 1 "Active" 0 "ModeNotDetermined" ;
VAL_ 909 PEBackupSlot_Stats 3 "No_Valid_FOB_In_Slot" 2 "MyKey_FOB_In_Slot" 1 "Standard_FOB_In_Slot" 0 "Null" ;
VAL_ 909 KeyMykeyTot_No_Cnt 13 "Thirteen" 12 "Twelve" 11 "Eleven" 10 "Ten" 9 "Nine" 8 "Eight" 7 "Seven" 6 "Six" 5 "Five" 4 "Four" 3 "Three" 2 "Two" 1 "One" 0 "Zero" 15 "Invalid" 14 "Unlimited" ;
VAL_ 909 KeyAdmnTot_No_Cnt 13 "Thirteen" 12 "Twelve" 11 "Eleven" 10 "Ten" 9 "Nine" 8 "Eight" 7 "Seven" 6 "Six" 5 "Five" 4 "Four" 3 "Three" 2 "Two" 1 "One" 0 "Zero" 15 "Invalid" 14 "Unlimited" ;
VAL_ 909 HazrdLght_B_Stat 1 "On" 0 "Off" ;
